VERSION ""

NS_ :

BS_:

BU_: BMS ECC EVBUS_Virtual_ECU GW OBC VCU

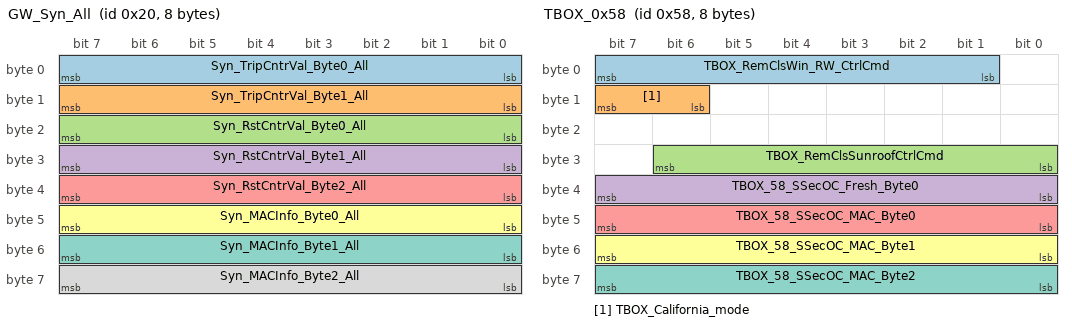
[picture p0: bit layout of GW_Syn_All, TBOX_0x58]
BO_ 32 GW_Syn_All: 8 GW
 SG_ Syn_TripCntrVal_Byte0_All : 7|8@0+ (1,0) [0|255] ""  BMS,OBC,VCU
 SG_ Syn_TripCntrVal_Byte1_All : 15|8@0+ (1,0) [0|255] ""  BMS,OBC,VCU
 SG_ Syn_RstCntrVal_Byte0_All : 23|8@0+ (1,0) [0|255] ""  BMS,OBC,VCU
 SG_ Syn_RstCntrVal_Byte1_All : 31|8@0+ (1,0) [0|255] ""  BMS,OBC,VCU
 SG_ Syn_RstCntrVal_Byte2_All : 39|8@0+ (1,0) [0|255] ""  BMS,OBC,VCU
 SG_ Syn_MACInfo_Byte0_All : 47|8@0+ (1,0) [0|255] ""  BMS,OBC,VCU
 SG_ Syn_MACInfo_Byte1_All : 55|8@0+ (1,0) [0|255] ""  BMS,OBC,VCU
 SG_ Syn_MACInfo_Byte2_All : 63|8@0+ (1,0) [0|255] ""  BMS,OBC,VCU

BO_ 54 TBOX_0x36: 8 GW
 SG_ TBOX_RemSeekCarCtrlCmd : 3|2@0+ (1,0) [0|3] ""  EVBUS_Virtual_ECU
 SG_ TBOX_RemClsTrCmd : 9|2@0+ (1,0) [0|3] ""  EVBUS_Virtual_ECU
 SG_ TBOX_RemDrvrSeatVentnCmd : 12|3@0+ (1,0) [0|7] ""  EVBUS_Virtual_ECU
 SG_ TBOX_RemDrvrSeatHeatgCmd : 15|3@0+ (1,0) [0|7] ""  EVBUS_Virtual_ECU
 SG_ TBOX_RemSetWelFct : 17|2@0+ (1,0) [0|3] ""  EVBUS_Virtual_ECU
 SG_ TBOX_RemPassSeatVentnCmd : 20|3@0+ (1,0) [0|7] ""  EVBUS_Virtual_ECU
 SG_ TBOX_RemPassSeatHeatgCmd : 23|3@0+ (1,0) [0|7] ""  EVBUS_Virtual_ECU
 SG_ TBOX_ClsAVMFct_ICC : 27|1@0+ (1,0) [0|1] ""  EVBUS_Virtual_ECU
 SG_ TBOX_ClsRemAVMFct_AVAP : 28|1@0+ (1,0) [0|1] ""  EVBUS_Virtual_ECU
 SG_ TBOX_RemSetFolwMeFct_BCM : 31|3@0+ (1,0) [0|7] ""  EVBUS_Virtual_ECU
 SG_ TBOX_RemSetCtrlLockFct_PKC : 33|2@0+ (1,0) [0|3] ""  EVBUS_Virtual_ECU
 SG_ TBOX_RemSetKickSnsrFct : 35|2@0+ (1,0) [0|3] ""  EVBUS_Virtual_ECU
 SG_ TBOX_VideoCtrlReq : 38|3@0+ (1,0) [0|7] ""  EVBUS_Virtual_ECU
 SG_ TBOX_VoiceBlowerLimReq : 39|1@0+ (1,0) [0|1] ""  ECC
 SG_ TBOX_RemCtrlCmdFb : 41|2@0+ (1,0) [0|3] ""  EVBUS_Virtual_ECU
 SG_ TBOX_CtrlReMirrReq : 43|2@0+ (1,0) [0|3] ""  EVBUS_Virtual_ECU
 SG_ TBOX_eCallMuteSt : 45|2@0+ (1,0) [0|3] ""  EVBUS_Virtual_ECU
 SG_ TBOX_RemReScrnHeatgCmd : 47|2@0+ (1,0) [0|3] ""  EVBUS_Virtual_ECU
 SG_ TBOX_eCallSt : 58|3@0+ (1,0) [0|7] ""  EVBUS_Virtual_ECU

BO_ 88 TBOX_0x58: 8 GW
 SG_ TBOX_RemClsWin_RW_CtrlCmd : 7|7@0+ (1,0) [0|100] "%"  EVBUS_Virtual_ECU
 SG_ TBOX_California_mode : 15|2@0+ (1,0) [0|3] ""  ECC
 SG_ TBOX_RemClsSunroofCtrlCmd : 30|7@0+ (1,0) [0|100] "%"  EVBUS_Virtual_ECU
 SG_ TBOX_58_SSecOC_Fresh_Byte0 : 39|8@0+ (1,0) [0|255] ""  EVBUS_Virtual_ECU
 SG_ TBOX_58_SSecOC_MAC_Byte0 : 47|8@0+ (1,0) [0|255] ""  EVBUS_Virtual_ECU
 SG_ TBOX_58_SSecOC_MAC_Byte1 : 55|8@0+ (1,0) [0|255] ""  EVBUS_Virtual_ECU
 SG_ TBOX_58_SSecOC_MAC_Byte2 : 63|8@0+ (1,0) [0|255] ""  EVBUS_Virtual_ECU

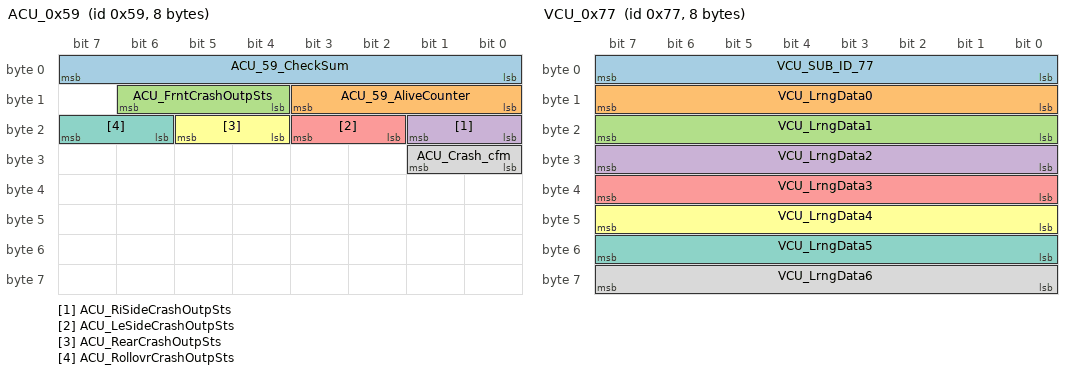
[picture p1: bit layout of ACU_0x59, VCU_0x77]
BO_ 89 ACU_0x59: 8 GW
 SG_ ACU_59_CheckSum : 7|8@0+ (1,0) [0|255] ""  BMS,ECC,OBC
 SG_ ACU_59_AliveCounter : 11|4@0+ (1,0) [0|14] ""  BMS,ECC,OBC
 SG_ ACU_FrntCrashOutpSts : 14|3@0+ (1,0) [0|7] ""  BMS,ECC,OBC
 SG_ ACU_RiSideCrashOutpSts : 17|2@0+ (1,0) [0|3] ""  BMS,ECC,OBC
 SG_ ACU_LeSideCrashOutpSts : 19|2@0+ (1,0) [0|3] ""  BMS,ECC,OBC
 SG_ ACU_RearCrashOutpSts : 21|2@0+ (1,0) [0|3] ""  BMS,ECC,OBC
 SG_ ACU_RollovrCrashOutpSts : 23|2@0+ (1,0) [0|3] ""  BMS,ECC,OBC
 SG_ ACU_Crash_cfm : 25|2@0+ (1,0) [0|3] ""  BMS,ECC,OBC

BO_ 117 VCU_0x75: 8 VCU
 SG_ VCU_SUB_ID_75 : 7|8@0+ (1,0) [0|255] ""  GW
 SG_ VCU_LrngSts : 15|8@0+ (1,0) [0|255] ""  GW

BO_ 119 VCU_0x77: 8 VCU
 SG_ VCU_SUB_ID_77 : 7|8@0+ (1,0) [0|255] ""  GW
 SG_ VCU_LrngData0 : 15|8@0+ (1,0) [0|255] ""  GW
 SG_ VCU_LrngData1 : 23|8@0+ (1,0) [0|255] ""  GW
 SG_ VCU_LrngData2 : 31|8@0+ (1,0) [0|255] ""  GW
 SG_ VCU_LrngData3 : 39|8@0+ (1,0) [0|255] ""  GW
 SG_ VCU_LrngData4 : 47|8@0+ (1,0) [0|255] ""  GW
 SG_ VCU_LrngData5 : 55|8@0+ (1,0) [0|255] ""  GW
 SG_ VCU_LrngData6 : 63|8@0+ (1,0) [0|255] ""  GW

BO_ 121 TBOX_0x79: 8 GW
 SG_ TBOX_LrnFbInfoClassn : 7|8@0+ (1,0) [0|255] ""  EVBUS_Virtual_ECU
 SG_ TBOX_LrngSts : 15|8@0+ (1,0) [0|255] ""  EVBUS_Virtual_ECU

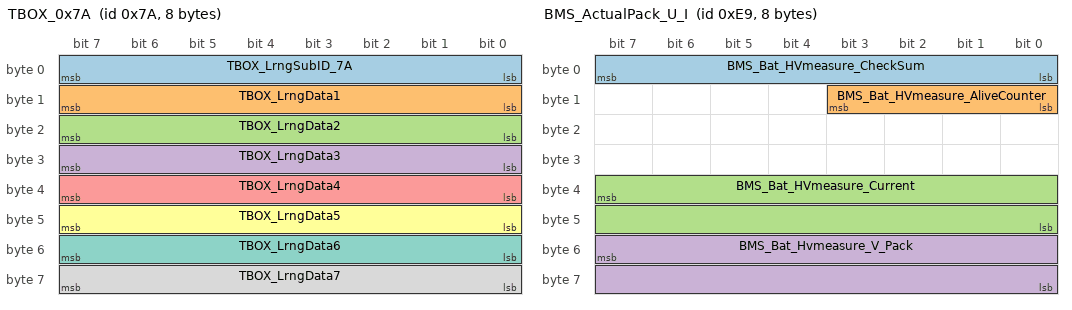
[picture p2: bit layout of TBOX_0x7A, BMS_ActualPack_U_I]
BO_ 122 TBOX_0x7A: 8 GW
 SG_ TBOX_LrngSubID_7A : 7|8@0+ (1,0) [0|255] ""  EVBUS_Virtual_ECU
 SG_ TBOX_LrngData1 : 15|8@0+ (1,0) [0|255] ""  EVBUS_Virtual_ECU
 SG_ TBOX_LrngData2 : 23|8@0+ (1,0) [0|255] ""  EVBUS_Virtual_ECU
 SG_ TBOX_LrngData3 : 31|8@0+ (1,0) [0|255] ""  EVBUS_Virtual_ECU
 SG_ TBOX_LrngData4 : 39|8@0+ (1,0) [0|255] ""  EVBUS_Virtual_ECU
 SG_ TBOX_LrngData5 : 47|8@0+ (1,0) [0|255] ""  EVBUS_Virtual_ECU
 SG_ TBOX_LrngData6 : 55|8@0+ (1,0) [0|255] ""  EVBUS_Virtual_ECU
 SG_ TBOX_LrngData7 : 63|8@0+ (1,0) [0|255] ""  EVBUS_Virtual_ECU

BO_ 147 VCU_0x93: 16 VCU
 SG_ VCU_93_CheckSum : 7|8@0+ (1,0) [0|255] ""  BMS,GW
 SG_ VCU_93_AliveCounter : 11|4@0+ (1,0) [0|14] ""  BMS,GW
 SG_ VCU_EmgyShutOff : 12|1@0+ (1,0) [0|1] ""  BMS,GW
 SG_ VCU_IsolationMonitor_Rq : 13|1@0+ (1,0) [0|1] ""  BMS,GW
 SG_ VCU_Set_Chrg_Mod : 19|4@0+ (1,0) [0|15] ""  BMS,GW
 SG_ VCU_Set_BMS_Mod : 23|4@0+ (1,0) [0|15] ""  BMS,GW
 SG_ VCU_HVBActivateDeactivateRq : 35|4@0+ (1,0) [0|15] ""  BMS,GW
 SG_ VCU_Set_Balc_Mod : 39|4@0+ (1,0) [0|15] ""  BMS,GW
 SG_ VCU_93_SSecOC_Fresh_Byte0 : 71|8@0+ (1,0) [0|255] ""  BMS,GW
 SG_ VCU_93_SSecOC_MAC_Byte0 : 79|8@0+ (1,0) [0|255] ""  BMS,GW
 SG_ VCU_93_SSecOC_MAC_Byte1 : 87|8@0+ (1,0) [0|255] ""  BMS,GW
 SG_ VCU_93_SSecOC_MAC_Byte2 : 95|8@0+ (1,0) [0|255] ""  BMS,GW

BO_ 233 BMS_ActualPack_U_I: 8 BMS
 SG_ BMS_Bat_HVmeasure_CheckSum : 7|8@0+ (1,0) [0|255] ""  GW,VCU
 SG_ BMS_Bat_HVmeasure_AliveCounter : 11|4@0+ (1,0) [0|14] ""  GW,VCU
 SG_ BMS_Bat_HVmeasure_Current : 39|16@0- (0.05,0) [-1250|1250] "A"  ECC,GW,VCU
 SG_ BMS_Bat_Hvmeasure_V_Pack : 55|16@0+ (0.01,0) [0|655.35] "V"  GW,VCU

BO_ 235 BMS_HVBatt_Status_Errors_1: 8 BMS
 SG_ BMS_Critical_Error_Flg_CheckSum : 7|8@0+ (1,0) [0|255] ""  GW,VCU
 SG_ BMS_Critical_Error_Flg_AliveCoun : 11|4@0+ (1,0) [0|14] ""  GW,VCU
 SG_ BMS_ErrorWarning_OverChargeCurre : 12|1@0+ (1,0) [0|1] ""  GW,VCU
 SG_ BMS_ErrorActive_OverChargeCurren : 13|1@0+ (1,0) [0|1] ""  GW,VCU
 SG_ BMS_ErrorWarning_OverDischargeCu : 14|1@0+ (1,0) [0|1] ""  GW,VCU
 SG_ BMS_ErrorActive_OverDischargeCur : 15|1@0+ (1,0) [0|1] ""  GW,VCU
 SG_ BMS_ErrorWarning_ChargePowerLimi : 16|1@0+ (1,0) [0|1] ""  GW,VCU
 SG_ BMS_ErrorActive_ChargePowerLimit : 17|1@0+ (1,0) [0|1] ""  GW,VCU
 SG_ BMS_ErrorWarning_DischargePowerL : 18|1@0+ (1,0) [0|1] ""  GW,VCU
 SG_ BMS_ErrorActive_DischargePowerLi : 19|1@0+ (1,0) [0|1] ""  GW,VCU
 SG_ BMS_ErrorWarning_SOC_Low : 20|1@0+ (1,0) [0|1] ""  GW,VCU
 SG_ BMS_ErrorActive_SOC_Low : 21|1@0+ (1,0) [0|1] ""  GW,VCU
 SG_ BMS_ErrorWarning_Iso : 22|1@0+ (1,0) [0|1] ""  GW,VCU
 SG_ BMS_ErrorActive_Iso_Crit : 23|1@0+ (1,0) [0|1] ""  GW,VCU
 SG_ BMS_ErrorActive_AbsChargeCurrent : 24|1@0+ (1,0) [0|1] ""  GW,VCU
 SG_ BMS_ErrorActive_AbsDischargeCurr : 25|1@0+ (1,0) [0|1] ""  GW,VCU
 SG_ BMS_ErrorActive_AbsChargePowerLi : 26|1@0+ (1,0) [0|1] ""  GW,VCU
 SG_ BMS_ErrorActive_AbsDischargePowe : 27|1@0+ (1,0) [0|1] ""  GW,VCU
 SG_ BMS_ErrorWarning_overcurrent_Pre : 28|1@0+ (1,0) [0|1] ""  GW,VCU
 SG_ BMS_ErrorActive_ServState : 29|1@0+ (1,0) [0|1] ""  GW,VCU
 SG_ BMS_SystemError_KL30C : 30|1@0+ (1,0) [0|1] ""  GW,VCU
 SG_ BMS_SystemError_OmmissionOfKL15 : 31|1@0+ (1,0) [0|1] ""  GW,VCU
 SG_ BMS_SystemError_HV_Interlock : 32|1@0+ (1,0) [0|1] ""  GW,VCU
 SG_ BMS_SystemError_HV_Fuse : 33|1@0+ (1,0) [0|1] ""  GW,VCU
 SG_ BMS_CommError_CommFailure : 34|1@0+ (1,0) [0|1] ""  GW,VCU
 SG_ BMS_CommWarning_PEC_High : 35|1@0+ (1,0) [0|1] ""  GW,VCU
 SG_ BMS_CommError_PEC_High : 36|1@0+ (1,0) [0|1] ""  GW,VCU
 SG_ BMS_HVlinkError_VCU_Comm_Failure : 37|1@0+ (1,0) [0|1] ""  GW,VCU
 SG_ BMS_HVlinkError_Iso_Dev : 38|1@0+ (1,0) [0|1] ""  GW,VCU
 SG_ BMS_HVlinkError_Iso_Dig_Sig : 39|1@0+ (1,0) [0|1] ""  GW,VCU
 SG_ BMS_HVlinkError_ContactorWelded : 40|1@0+ (1,0) [0|1] ""  GW,VCU
 SG_ BMS_HVlinkError_HV_Interlock_Bad : 41|1@0+ (1,0) [0|1] ""  GW,VCU
 SG_ BMS_HardwareError_LCM_General_Fa : 42|1@0+ (1,0) [0|1] ""  GW,VCU
 SG_ BMS_SoftwareError_General_Failr : 43|1@0+ (1,0) [0|1] ""  GW,VCU
 SG_ BMS_ErrorWarning_CellOverVoltage : 44|1@0+ (1,0) [0|1] ""  GW,VCU
 SG_ BMS_ErrorActive_CellOverVoltage : 45|1@0+ (1,0) [0|1] ""  GW,VCU
 SG_ BMS_ErrorWarning_CellUnderVoltag : 46|1@0+ (1,0) [0|1] ""  GW,VCU
 SG_ BMS_ErrorActive_CellUnderVoltage : 47|1@0+ (1,0) [0|1] ""  GW,VCU
 SG_ BMS_ErrorWarning_CellTempHigh : 48|1@0+ (1,0) [0|1] ""  GW,VCU
 SG_ BMS_ErrorActive_CellTempHigh : 49|1@0+ (1,0) [0|1] ""  GW,VCU
 SG_ BMS_ErrorWarning_CellTempLow : 50|1@0+ (1,0) [0|1] ""  GW,VCU
 SG_ BMS_ErrorActive_CellTempLow : 51|1@0+ (1,0) [0|1] ""  GW,VCU
 SG_ BMS_ErrorWarning_HV_OverVoltage : 52|1@0+ (1,0) [0|1] ""  GW,VCU
 SG_ BMS_ErrorActive_HV_OverVoltage : 53|1@0+ (1,0) [0|1] ""  GW,VCU
 SG_ BMS_ErrorWarning_HV_UnderVoltage : 54|1@0+ (1,0) [0|1] ""  GW,VCU
 SG_ BMS_ErrorActive_HV_UnderVoltage : 55|1@0+ (1,0) [0|1] ""  GW,VCU
 SG_ BMS_PVIU_CANcommError : 56|1@0+ (1,0) [0|1] ""  GW,VCU

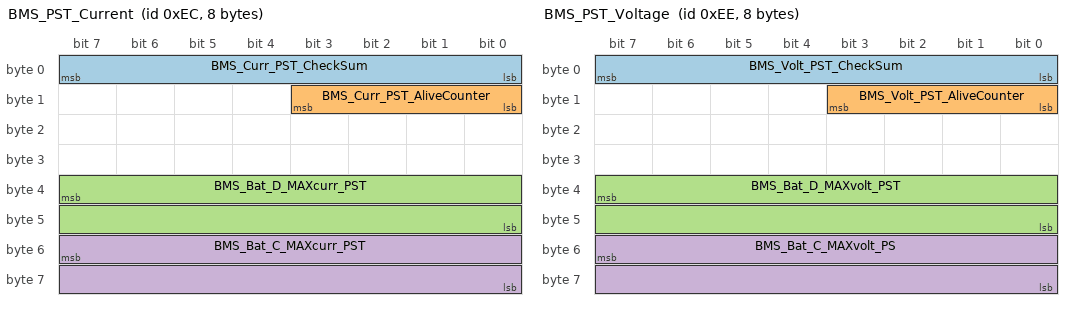
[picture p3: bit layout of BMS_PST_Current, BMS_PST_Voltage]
BO_ 236 BMS_PST_Current: 8 BMS
 SG_ BMS_Curr_PST_CheckSum : 7|8@0+ (1,0) [0|255] ""  GW,VCU
 SG_ BMS_Curr_PST_AliveCounter : 11|4@0+ (1,0) [0|14] ""  GW,VCU
 SG_ BMS_Bat_D_MAXcurr_PST : 39|16@0+ (0.05,0) [0|3276.75] "A"  GW,VCU
 SG_ BMS_Bat_C_MAXcurr_PST : 55|16@0+ (0.05,0) [0|3276.75] "A"  GW,VCU

BO_ 237 BMS_HVBatt_Status_Overall: 8 BMS
 SG_ BMS_OverallStatus_CheckSum : 7|8@0+ (1,0) [0|255] ""  ECC,GW,VCU
 SG_ BMS_OverallStatus_AliveCounter : 11|4@0+ (1,0) [0|14] ""  ECC,GW,VCU
 SG_ BMS_OperationStates : 19|4@0+ (1,0) [0|15] ""  ECC,GW,VCU
 SG_ BMS_BallancingStatus : 23|4@0+ (1,0) [0|15] ""  ECC,GW,VCU
 SG_ BMS_ErrorCategory_CAT0 : 24|1@0+ (1,0) [0|1] ""  ECC,GW,VCU
 SG_ BMS_ErrorCategory_CAT1 : 25|1@0+ (1,0) [0|1] ""  ECC,GW,VCU
 SG_ BMS_ErrorCategory_CAT2 : 26|1@0+ (1,0) [0|1] ""  ECC,GW,VCU
 SG_ BMS_ErrorCategory_CAT3 : 27|1@0+ (1,0) [0|1] ""  ECC,GW,VCU
 SG_ BMS_ErrorCategory_CAT4 : 28|1@0+ (1,0) [0|1] ""  ECC,GW,VCU
 SG_ BMS_ErrorCategory_CAT5 : 29|1@0+ (1,0) [0|1] ""  ECC,GW,VCU
 SG_ BMS_ErrorCategory_CAT6 : 30|1@0+ (1,0) [0|1] ""  ECC,GW,VCU
 SG_ BMS_ErrorCategory_CAT7 : 31|1@0+ (1,0) [0|1] ""  ECC,GW,VCU
 SG_ BMS_ErrorCategory_CAT8 : 32|1@0+ (1,0) [0|1] ""  ECC,GW,VCU
 SG_ BMS_HardwareStatus_OK : 33|1@0+ (1,0) [0|1] ""  ECC,GW,VCU
 SG_ BMS_ErrorCategory_Mem_Empty : 34|1@0+ (1,0) [0|1] ""  ECC,GW,VCU
 SG_ BMS_ConfigurationStatus_OK : 35|1@0+ (1,0) [0|1] ""  ECC,GW,VCU
 SG_ BMS_MeasurementModules_OK : 36|1@0+ (1,0) [0|1] ""  ECC,GW,VCU
 SG_ BMS_BatteryGeneralStatus_OK : 37|1@0+ (1,0) [0|1] ""  ECC,GW,VCU
 SG_ BMS_SDIL_Sts : 38|1@0+ (1,0) [0|1] ""  ECC,GW,VCU
 SG_ BMS_CL30C_Sts : 39|1@0+ (1,0) [0|1] ""  ECC,GW,VCU
 SG_ BMS_CL15_Sts : 40|1@0+ (1,0) [0|1] ""  ECC,GW,VCU
 SG_ BMS_HVIL_OK : 41|1@0+ (1,0) [0|1] ""  ECC,GW,VCU
 SG_ BMS_HV_ContactorsStatus_OK : 42|1@0+ (1,0) [0|1] ""  ECC,GW,VCU
 SG_ BMS_SW_Status_OK : 43|1@0+ (1,0) [0|1] ""  ECC,GW,VCU
 SG_ BMS_CurrentSensor_OK : 44|1@0+ (1,0) [0|1] ""  ECC,GW,VCU
 SG_ BMS_IsolatoinStatus_OK : 45|1@0+ (1,0) [0|1] ""  ECC,GW,VCU
 SG_ BMS_StateMAchine_Status : 55|8@0+ (1,0) [0|255] ""  ECC,GW,OBC,VCU
 SG_ BMS_BDU_Status : 63|8@0+ (1,0) [0|255] ""  ECC,GW,VCU

BO_ 238 BMS_PST_Voltage: 8 BMS
 SG_ BMS_Volt_PST_CheckSum : 7|8@0+ (1,0) [0|255] ""  GW,VCU
 SG_ BMS_Volt_PST_AliveCounter : 11|4@0+ (1,0) [0|14] ""  GW,VCU
 SG_ BMS_Bat_D_MAXvolt_PST : 39|16@0+ (0.02,0) [0|1310.7] "V"  GW,VCU
 SG_ BMS_Bat_C_MAXvolt_PS : 55|16@0+ (0.02,0) [0|1310.7] "V"  GW,VCU

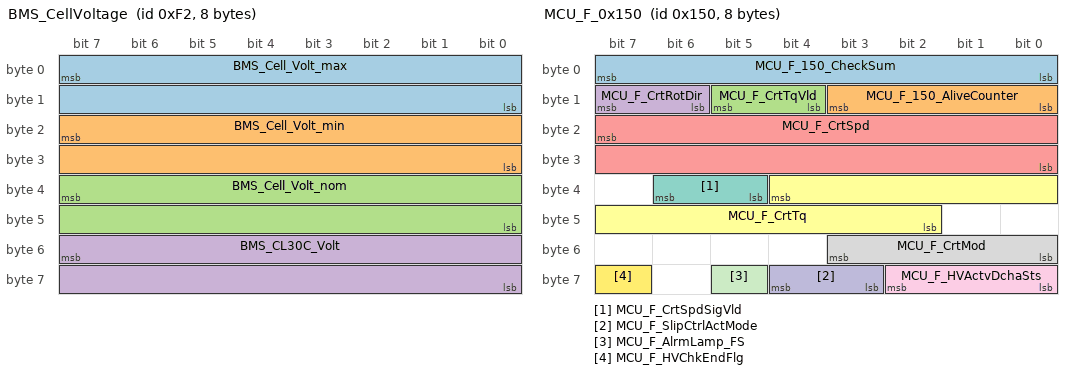
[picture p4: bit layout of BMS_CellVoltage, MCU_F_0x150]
BO_ 242 BMS_CellVoltage: 8 BMS
 SG_ BMS_Cell_Volt_max : 7|16@0+ (0.1,0) [0|6553.5] "mV"  GW,VCU
 SG_ BMS_Cell_Volt_min : 23|16@0+ (0.1,0) [0|6553.5] "mV"  GW,VCU
 SG_ BMS_Cell_Volt_nom : 39|16@0+ (0.1,0) [0|6553.5] "mV"  GW,VCU
 SG_ BMS_CL30C_Volt : 55|16@0+ (0.001,0) [0|65.534] "V"  GW

BO_ 276 ESP_0x114: 8 GW
 SG_ ESP_114_CheckSum : 7|8@0+ (1,0) [0|255] ""  EVBUS_Virtual_ECU
 SG_ ESP_114_AliveCounter : 11|4@0+ (1,0) [0|14] ""  EVBUS_Virtual_ECU
 SG_ ESP_OTARdy_Fb : 13|2@0+ (1,0) [0|3] ""  EVBUS_Virtual_ECU
 SG_ ESP_FltIndcn_DTC : 15|1@0+ (1,0) [0|1] ""  EVBUS_Virtual_ECU
 SG_ ESP_ActvSig_VDC : 16|1@0+ (1,0) [0|1] ""  EVBUS_Virtual_ECU
 SG_ ESP_ActvSig_TCS : 17|1@0+ (1,0) [0|1] ""  EVBUS_Virtual_ECU
 SG_ ESP_ActvSig_EBD : 19|1@0+ (1,0) [0|1] ""  EVBUS_Virtual_ECU
 SG_ ESP_ActvSig_DTC : 20|1@0+ (1,0) [0|1] ""  EVBUS_Virtual_ECU
 SG_ ESP_WarningOn : 22|2@0+ (1,0) [0|3] ""  EVBUS_Virtual_ECU
 SG_ ESP_Actvndcn_CDD : 24|1@0+ (1,0) [0|1] ""  EVBUS_Virtual_ECU
 SG_ ESP_FltIndcn_CDD : 25|1@0+ (1,0) [0|1] ""  EVBUS_Virtual_ECU
 SG_ ESP_ActvIndcn_ABA : 26|1@0+ (1,0) [0|1] ""  EVBUS_Virtual_ECU
 SG_ ESP_FltIndcn_ABA : 27|1@0+ (1,0) [0|1] ""  EVBUS_Virtual_ECU
 SG_ ESP_ActvIndcn_ABP : 28|1@0+ (1,0) [0|1] ""  EVBUS_Virtual_ECU
 SG_ ESP_FltIndcn_ABP : 29|1@0+ (1,0) [0|1] ""  EVBUS_Virtual_ECU
 SG_ ESP_ActvIndcn_AEB : 30|1@0+ (1,0) [0|1] ""  EVBUS_Virtual_ECU
 SG_ ESP_FltIndcn_AEB : 31|1@0+ (1,0) [0|1] ""  EVBUS_Virtual_ECU
 SG_ ESP_ActvIndcn_AWB : 32|1@0+ (1,0) [0|1] ""  EVBUS_Virtual_ECU
 SG_ ESP_FltIndcn_AWB : 33|1@0+ (1,0) [0|1] ""  EVBUS_Virtual_ECU
 SG_ ESP_VehStandstillIndcn : 35|2@0+ (1,0) [0|3] ""  EVBUS_Virtual_ECU
 SG_ ESP_BrkOverTIndcn : 36|1@0+ (1,0) [0|1] ""  ECC
 SG_ ESP_FltIndcn_VDC : 37|1@0+ (1,0) [0|1] ""  EVBUS_Virtual_ECU
 SG_ ESP_ActvIndcn_CDD_AP : 42|1@0+ (1,0) [0|1] ""  EVBUS_Virtual_ECU
 SG_ ESP_FltIndcn_CDD_AP : 43|1@0+ (1,0) [0|1] ""  EVBUS_Virtual_ECU

BO_ 336 MCU_F_0x150: 8 GW
 SG_ MCU_F_150_CheckSum : 7|8@0+ (1,0) [0|255] ""  ECC
 SG_ MCU_F_150_AliveCounter : 11|4@0+ (1,0) [0|14] ""  ECC
 SG_ MCU_F_CrtTqVld : 13|2@0+ (1,0) [0|3] ""  ECC
 SG_ MCU_F_CrtRotDir : 15|2@0+ (1,0) [0|3] ""  ECC
 SG_ MCU_F_CrtSpd : 23|16@0+ (1,-32768) [-32768|32767] "rpm"  BMS,ECC,OBC
 SG_ MCU_F_CrtTq : 36|11@0+ (0.5,-511) [-511|512] "Nm"  ECC
 SG_ MCU_F_CrtSpdSigVld : 38|2@0+ (1,0) [0|3] ""  BMS,ECC,OBC
 SG_ MCU_F_CrtMod : 51|4@0+ (1,0) [0|15] ""  ECC
 SG_ MCU_F_HVActvDchaSts : 58|3@0+ (1,0) [0|7] ""  ECC
 SG_ MCU_F_SlipCtrlActMode : 60|2@0+ (1,0) [0|3] ""  ECC
 SG_ MCU_F_AlrmLamp_FS : 61|1@0+ (1,0) [0|1] ""  ECC
 SG_ MCU_F_HVChkEndFlg : 63|1@0+ (1,0) [0|1] ""  ECC

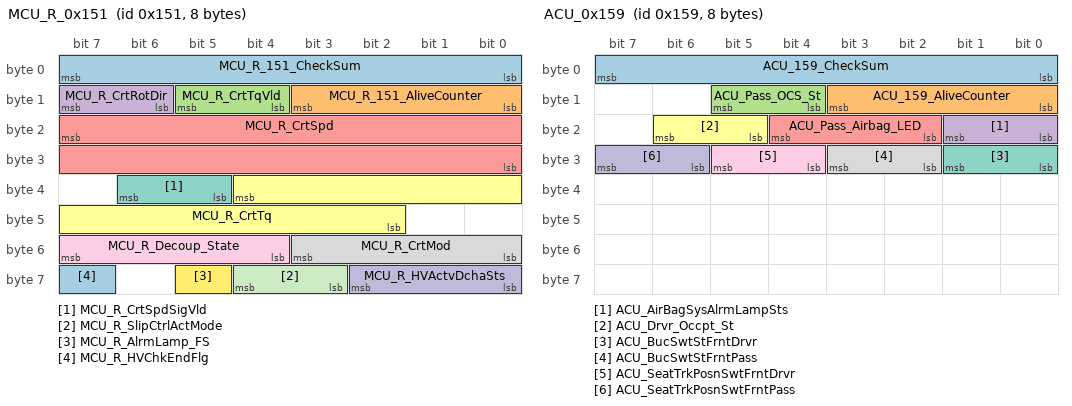
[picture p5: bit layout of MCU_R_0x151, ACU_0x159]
BO_ 337 MCU_R_0x151: 8 GW
 SG_ MCU_R_151_CheckSum : 7|8@0+ (1,0) [0|255] ""  ECC
 SG_ MCU_R_151_AliveCounter : 11|4@0+ (1,0) [0|14] ""  ECC
 SG_ MCU_R_CrtTqVld : 13|2@0+ (1,0) [0|3] ""  ECC
 SG_ MCU_R_CrtRotDir : 15|2@0+ (1,0) [0|3] ""  ECC
 SG_ MCU_R_CrtSpd : 23|16@0+ (1,-32768) [-32768|32767] "rpm"  BMS,ECC,OBC
 SG_ MCU_R_CrtTq : 36|11@0+ (0.5,-511) [-511|512] "Nm"  ECC
 SG_ MCU_R_CrtSpdSigVld : 38|2@0+ (1,0) [0|3] ""  BMS,ECC,OBC
 SG_ MCU_R_CrtMod : 51|4@0+ (1,0) [0|15] ""  ECC
 SG_ MCU_R_Decoup_State : 55|4@0+ (1,0) [0|15] ""  ECC
 SG_ MCU_R_HVActvDchaSts : 58|3@0+ (1,0) [0|7] ""  ECC
 SG_ MCU_R_SlipCtrlActMode : 60|2@0+ (1,0) [0|3] ""  ECC
 SG_ MCU_R_AlrmLamp_FS : 61|1@0+ (1,0) [0|1] ""  ECC
 SG_ MCU_R_HVChkEndFlg : 63|1@0+ (1,0) [0|1] ""  ECC

BO_ 345 ACU_0x159: 8 GW
 SG_ ACU_159_CheckSum : 7|8@0+ (1,0) [0|255] ""  ECC
 SG_ ACU_159_AliveCounter : 11|4@0+ (1,0) [0|14] ""  ECC
 SG_ ACU_Pass_OCS_St : 13|2@0+ (1,0) [0|3] ""  ECC
 SG_ ACU_AirBagSysAlrmLampSts : 17|2@0+ (1,0) [0|3] ""  EVBUS_Virtual_ECU
 SG_ ACU_Pass_Airbag_LED : 20|3@0+ (1,0) [0|7] ""  EVBUS_Virtual_ECU
 SG_ ACU_Drvr_Occpt_St : 22|2@0+ (1,0) [0|3] ""  ECC
 SG_ ACU_BucSwtStFrntDrvr : 25|2@0+ (1,0) [0|3] ""  ECC
 SG_ ACU_BucSwtStFrntPass : 27|2@0+ (1,0) [0|3] ""  ECC
 SG_ ACU_SeatTrkPosnSwtFrntDrvr : 29|2@0+ (1,0) [0|3] ""  EVBUS_Virtual_ECU
 SG_ ACU_SeatTrkPosnSwtFrntPass : 31|2@0+ (1,0) [0|3] ""  EVBUS_Virtual_ECU

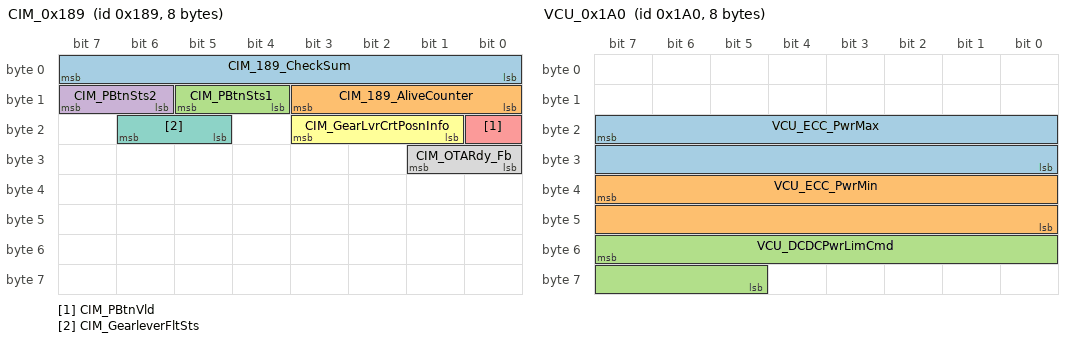
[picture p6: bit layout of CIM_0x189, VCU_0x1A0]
BO_ 393 CIM_0x189: 8 GW
 SG_ CIM_189_CheckSum : 7|8@0+ (1,0) [0|255] ""  VCU
 SG_ CIM_189_AliveCounter : 11|4@0+ (1,0) [0|14] ""  VCU
 SG_ CIM_PBtnSts1 : 13|2@0+ (1,0) [0|3] ""  VCU
 SG_ CIM_PBtnSts2 : 15|2@0+ (1,0) [0|3] ""  VCU
 SG_ CIM_PBtnVld : 16|1@0+ (1,0) [0|1] ""  VCU
 SG_ CIM_GearLvrCrtPosnInfo : 19|3@0+ (1,0) [0|7] ""  VCU
 SG_ CIM_GearleverFltSts : 22|2@0+ (1,0) [0|3] ""  VCU
 SG_ CIM_OTARdy_Fb : 25|2@0+ (1,0) [0|3] ""  EVBUS_Virtual_ECU

BO_ 416 VCU_0x1A0: 8 VCU
 SG_ VCU_ECC_PwrMax : 23|16@0+ (0.01,0) [0|20] "KW"  ECC,GW
 SG_ VCU_ECC_PwrMin : 39|16@0+ (0.01,0) [0|20] "KW"  ECC,GW
 SG_ VCU_DCDCPwrLimCmd : 55|11@0+ (0.01,0) [0|20] "KW"  GW,OBC

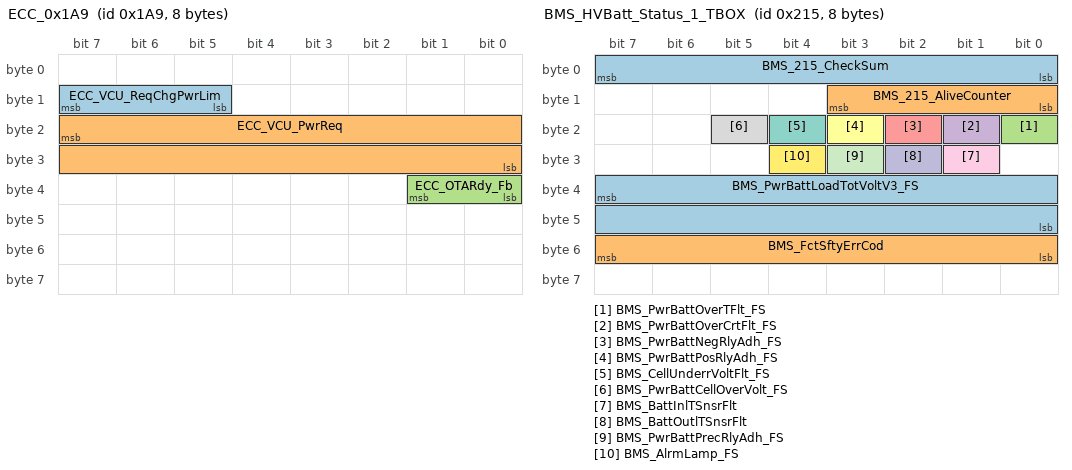
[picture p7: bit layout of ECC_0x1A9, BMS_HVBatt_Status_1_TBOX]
BO_ 425 ECC_0x1A9: 8 ECC
 SG_ ECC_VCU_ReqChgPwrLim : 15|3@0+ (1,0) [0|7] ""  GW,VCU
 SG_ ECC_VCU_PwrReq : 23|16@0+ (0.01,0) [0|20] "KW"  GW,VCU
 SG_ ECC_OTARdy_Fb : 33|2@0+ (1,0) [0|3] ""  GW

BO_ 438 PKC_0x1B6: 8 GW
 SG_ PKC_1B6_CheckSum : 7|8@0+ (1,0) [0|255] ""  VCU
 SG_ PKC_1B6_AliveCounter : 11|4@0+ (1,0) [0|14] ""  VCU
 SG_ PKC_TpMnvrCancel : 13|2@0+ (1,0) [0|3] ""  EVBUS_Virtual_ECU
 SG_ PKC_TpActDeactInp : 15|2@0+ (1,0) [0|3] ""  EVBUS_Virtual_ECU
 SG_ PKC_RemPwrOnOffReq : 17|2@0+ (1,0) [0|3] ""  VCU
 SG_ PKC_RemDrvgReq : 21|4@0+ (1,0) [0|15] ""  VCU
 SG_ PKC_RemChrgDchaGunUnlckCmd : 23|2@0+ (1,0) [0|3] ""  VCU
 SG_ PKC_RmteDviceBattLvl : 31|8@0+ (1,0) [0|100] "%"  EVBUS_Virtual_ECU
 SG_ PKC_BLE_Online : 32|1@0+ (1,0) [0|1] ""  EVBUS_Virtual_ECU
 SG_ PKC_DviceRngeDist : 34|2@0+ (1,0) [0|3] ""  EVBUS_Virtual_ECU
 SG_ PKC_DviceAliveCnt : 39|4@0+ (1,0) [0|15] ""  EVBUS_Virtual_ECU
 SG_ PKC_MnvreEnblInput : 41|2@0+ (1,0) [0|3] ""  EVBUS_Virtual_ECU
 SG_ PKC_RapActDeactInp : 47|2@0+ (1,0) [0|3] ""  EVBUS_Virtual_ECU
 SG_ PKC_MnvrRemsumeKey : 49|2@0+ (1,0) [0|3] ""  EVBUS_Virtual_ECU
 SG_ PKC_MnvrRtnStartKey : 51|2@0+ (1,0) [0|3] ""  EVBUS_Virtual_ECU
 SG_ PKC_AuthUsr : 59|2@0+ (1,0) [0|3] ""  EVBUS_Virtual_ECU
 SG_ PKC_AlcInterlockReqPromt : 61|2@0+ (1,0) [0|3] ""  EVBUS_Virtual_ECU
 SG_ PKC_NFCReminderPromt : 63|2@0+ (1,0) [0|3] ""  EVBUS_Virtual_ECU

BO_ 532 VCU_0x214: 16 VCU
 SG_ VCU_214_234_CheckSum : 7|8@0+ (1,0) [0|255] ""  ECC,GW
 SG_ VCU_214_234_AliveCounter : 11|4@0+ (1,0) [0|14] ""  ECC,GW
 SG_ VCU_RdyLamp : 12|1@0+ (1,0) [0|1] ""  GW
 SG_ VCU_BrkLampCtrlSts : 14|1@0+ (1,0) [0|1] ""  GW
 SG_ VCU_RemWakeUpEndFlg : 15|1@0+ (1,0) [0|1] ""  GW
 SG_ VCU_StgyGearSig : 19|4@0+ (1,0) [0|15] ""  GW
 SG_ VCU_ShiftMisoper : 21|1@0+ (1,0) [0|1] ""  GW
 SG_ VCU_GearSigVld : 23|2@0+ (1,0) [0|3] ""  GW
 SG_ VCU_GearSig : 27|4@0+ (1,0) [0|15] ""  GW
 SG_ VCU_ACCRdy : 28|1@0+ (1,0) [0|1] ""  GW
 SG_ VCU_ParkRdy : 29|1@0+ (1,0) [0|1] ""  GW
 SG_ VCU_APSPercVld : 31|2@0+ (1,0) [0|3] ""  GW
 SG_ VCU_VehSt : 39|16@0+ (1,0) [0|65535] ""  ECC,GW
 SG_ VCU_APSPerc : 55|8@0+ (0.4,0) [0|100] "%"  GW
 SG_ VCU_BrkSig : 56|1@0+ (1,0) [0|1] ""  GW
 SG_ VCU_BrkSigVld : 58|2@0+ (1,0) [0|3] ""  GW
 SG_ VCU_DrvModSigFb : 61|3@0+ (1,0) [0|7] ""  GW
 SG_ VCU_DrvModShiftMisoper : 62|1@0+ (1,0) [0|1] ""  GW
 SG_ VCU_SpclTerrainModEnaSig : 63|1@0+ (1,0) [0|1] ""  GW
 SG_ VCU_214_SSecOC_Fresh_Byte0 : 71|8@0+ (1,0) [0|255] ""  GW
 SG_ VCU_214_SSecOC_MAC_Byte0 : 79|8@0+ (1,0) [0|255] ""  GW
 SG_ VCU_214_SSecOC_MAC_Byte1 : 87|8@0+ (1,0) [0|255] ""  GW
 SG_ VCU_214_SSecOC_MAC_Byte2 : 95|8@0+ (1,0) [0|255] ""  GW

BO_ 533 BMS_HVBatt_Status_1_TBOX: 8 BMS
 SG_ BMS_215_CheckSum : 7|8@0+ (1,0) [0|255] ""  GW,VCU
 SG_ BMS_215_AliveCounter : 11|4@0+ (1,0) [0|14] ""  GW,VCU
 SG_ BMS_PwrBattOverTFlt_FS : 16|1@0+ (1,0) [0|1] ""  GW,VCU
 SG_ BMS_PwrBattOverCrtFlt_FS : 17|1@0+ (1,0) [0|1] ""  GW,VCU
 SG_ BMS_PwrBattNegRlyAdh_FS : 18|1@0+ (1,0) [0|1] ""  GW,VCU
 SG_ BMS_PwrBattPosRlyAdh_FS : 19|1@0+ (1,0) [0|1] ""  GW,VCU
 SG_ BMS_CellUnderrVoltFlt_FS : 20|1@0+ (1,0) [0|1] ""  GW,VCU
 SG_ BMS_PwrBattCellOverVolt_FS : 21|1@0+ (1,0) [0|1] ""  GW,VCU
 SG_ BMS_BattInlTSnsrFlt : 25|1@0+ (1,0) [0|1] ""  ECC,GW,VCU
 SG_ BMS_BattOutlTSnsrFlt : 26|1@0+ (1,0) [0|1] ""  ECC,GW,VCU
 SG_ BMS_PwrBattPrecRlyAdh_FS : 27|1@0+ (1,0) [0|1] ""  GW,VCU
 SG_ BMS_AlrmLamp_FS : 28|1@0+ (1,0) [0|1] ""  GW,VCU
 SG_ BMS_PwrBattLoadTotVoltV3_FS : 39|16@0+ (0.02,0) [0|1310.7] "V"  ECC,GW,VCU
 SG_ BMS_FctSftyErrCod : 55|8@0+ (1,0) [0|255] ""  GW

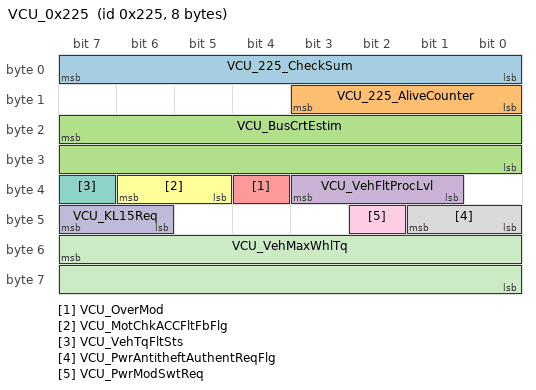
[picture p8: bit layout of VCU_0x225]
BO_ 549 VCU_0x225: 8 VCU
 SG_ VCU_225_CheckSum : 7|8@0+ (1,0) [0|255] ""  GW
 SG_ VCU_225_AliveCounter : 11|4@0+ (1,0) [0|14] ""  GW
 SG_ VCU_BusCrtEstim : 23|16@0+ (0.04,-1000) [-1000|1621.4] "A"  GW
 SG_ VCU_VehFltProcLvl : 35|3@0+ (1,0) [0|7] ""  GW
 SG_ VCU_OverMod : 36|1@0+ (1,0) [0|1] ""  GW
 SG_ VCU_MotChkACCFltFbFlg : 38|2@0+ (1,0) [0|3] ""  GW
 SG_ VCU_VehTqFltSts : 39|1@0+ (1,0) [0|1] ""  GW
 SG_ VCU_PwrAntitheftAuthentReqFlg : 41|2@0+ (1,0) [0|3] ""  GW
 SG_ VCU_PwrModSwtReq : 42|1@0+ (1,0) [0|1] ""  GW
 SG_ VCU_KL15Req : 47|2@0+ (1,0) [0|3] ""  GW
 SG_ VCU_VehMaxWhlTq : 55|16@0+ (1,-32768) [-32768|32767] "Nm"  GW

CM_ SG_ 32 Syn_TripCntrVal_Byte0_All "Trip Counter Value";
CM_ SG_ 32 Syn_TripCntrVal_Byte1_All "Trip Counter Value";
CM_ SG_ 32 Syn_RstCntrVal_Byte0_All "Reset Counter Value";
CM_ SG_ 32 Syn_RstCntrVal_Byte1_All "Reset Counter Value";
CM_ SG_ 32 Syn_RstCntrVal_Byte2_All "Reset Counter Value";
CM_ SG_ 32 Syn_MACInfo_Byte0_All "Synchronization message Mac Info";
CM_ SG_ 32 Syn_MACInfo_Byte1_All "Synchronization message Mac Info";
CM_ SG_ 32 Syn_MACInfo_Byte2_All "Synchronization message Mac Info";
CM_ SG_ 54 TBOX_RemSeekCarCtrlCmd "Remote vehicle locating control command";
CM_ SG_ 54 TBOX_RemClsTrCmd "Close electric tail gate command remotely";
CM_ SG_ 54 TBOX_RemDrvrSeatVentnCmd "Remote driver seat ventilation command";
CM_ SG_ 54 TBOX_RemDrvrSeatHeatgCmd "Remote driver seat heating command";
CM_ SG_ 54 TBOX_RemSetWelFct "Remotely set opening and closing seat courtesy function and steering wheel courtesy function";
CM_ SG_ 54 TBOX_RemPassSeatVentnCmd "Remote passenger seat ventilation command";
CM_ SG_ 54 TBOX_RemPassSeatHeatgCmd "Remote passenger seat heating command";
CM_ SG_ 54 TBOX_ClsAVMFct_ICC "Turn off ICC remote panoramic function";
CM_ SG_ 54 TBOX_ClsRemAVMFct_AVAP "Turn off AVAP signal remote panoramic function";
CM_ SG_ 54 TBOX_RemSetFolwMeFct_BCM "Remotely set BCM follow me home function, headlamp delay off time";
CM_ SG_ 54 TBOX_RemSetCtrlLockFct_PKC "Remote setting opening and closing inductive PEPS unlocking function";
CM_ SG_ 54 TBOX_RemSetKickSnsrFct "Remote setting turns on and off the foot kick sensor function";
CM_ SG_ 54 TBOX_VideoCtrlReq "Video control request";
CM_ SG_ 54 TBOX_VoiceBlowerLimReq "Voice Blower Limit Rquest";
CM_ SG_ 54 TBOX_RemCtrlCmdFb "TBOX remote control command feedback
";
CM_ SG_ 54 TBOX_CtrlReMirrReq "Control rearview mirror request";
CM_ SG_ 54 TBOX_eCallMuteSt "Emergency Call Mute status";
CM_ SG_ 54 TBOX_RemReScrnHeatgCmd "Remote rear screen heating command";
CM_ SG_ 54 TBOX_eCallSt "eCall status";
CM_ SG_ 88 TBOX_58_SSecOC_Fresh_Byte0 "Short SecOC Fresh signal byte 0 on CAN";
CM_ SG_ 88 TBOX_58_SSecOC_MAC_Byte0 "Short SecOC MAC signal byte 0 on CAN";
CM_ SG_ 88 TBOX_58_SSecOC_MAC_Byte1 "Short SecOC MAC signal byte 1 on CAN";
CM_ SG_ 88 TBOX_58_SSecOC_MAC_Byte2 "Short SecOC MAC signal byte 2 on CAN";
CM_ SG_ 89 ACU_59_CheckSum "ACU_59_CheckSum (E2E data ID: 0x98) ";
CM_ SG_ 89 ACU_59_AliveCounter "ACU_0x59_Message counterACU_59_AliveCounter";
CM_ SG_ 89 ACU_FrntCrashOutpSts "Front Crash Status";
CM_ SG_ 89 ACU_RiSideCrashOutpSts "Right Side Crash Status";
CM_ SG_ 89 ACU_LeSideCrashOutpSts "Left Side Crash Status";
CM_ SG_ 89 ACU_RearCrashOutpSts "Rear Crash Status";
CM_ SG_ 89 ACU_RollovrCrashOutpSts "Rollover Crash Status";
CM_ SG_ 89 ACU_Crash_cfm "Crash confirm signal";
CM_ SG_ 117 VCU_SUB_ID_75 "SUB_ID_75";
CM_ SG_ 117 VCU_LrngSts "VCU learning state";
CM_ SG_ 119 VCU_SUB_ID_77 "SUB_ID_77";
CM_ SG_ 119 VCU_LrngData0 "VCU_LEARNING_DATA_0";
CM_ SG_ 119 VCU_LrngData1 "VCU_LEARNING_DATA_1";
CM_ SG_ 119 VCU_LrngData2 "VCU_LEARNING_DATA_2";
CM_ SG_ 119 VCU_LrngData3 "VCU_LEARNING_DATA_3";
CM_ SG_ 119 VCU_LrngData4 "VCU_LEARNING_DATA_4";
CM_ SG_ 119 VCU_LrngData5 "VCU_LEARNING_DATA_5";
CM_ SG_ 119 VCU_LrngData6 "VCU_LEARNING_DATA_6";
CM_ SG_ 121 TBOX_LrnFbInfoClassn "Classification of learning feedback information";
CM_ SG_ 121 TBOX_LrngSts "Tbox learning state";
CM_ SG_ 122 TBOX_LrngSubID_7A "Subfunction identification of learning response message";
CM_ SG_ 122 TBOX_LrngData1 "Learning data";
CM_ SG_ 122 TBOX_LrngData2 "Learning data";
CM_ SG_ 122 TBOX_LrngData3 "Learning data";
CM_ SG_ 122 TBOX_LrngData4 "Learning data";
CM_ SG_ 122 TBOX_LrngData5 "Learning data";
CM_ SG_ 122 TBOX_LrngData6 "Learning data";
CM_ SG_ 122 TBOX_LrngData7 "Learning data";
CM_ SG_ 147 VCU_93_CheckSum "CheckSum(E2E data ID: 0x24)";
CM_ SG_ 147 VCU_93_AliveCounter "Rolling counter";
CM_ SG_ 147 VCU_EmgyShutOff "Emergency shut down request from  VCU";
CM_ SG_ 147 VCU_IsolationMonitor_Rq "Request for isolation Monitoring";
CM_ SG_ 147 VCU_Set_Chrg_Mod "Set BMS to charging Modes";
CM_ SG_ 147 VCU_Set_BMS_Mod "Set BMS to different Modes";
CM_ SG_ 147 VCU_HVBActivateDeactivateRq "Close or open contactors to activate or deactivate HV";
CM_ SG_ 147 VCU_Set_Balc_Mod "Set BMS balancing mode ";
CM_ SG_ 147 VCU_93_SSecOC_Fresh_Byte0 "Short SecOC Fresh signal byte 0 on CAN";
CM_ SG_ 147 VCU_93_SSecOC_MAC_Byte0 "Short SecOC MAC signal byte 0 on CAN";
CM_ SG_ 147 VCU_93_SSecOC_MAC_Byte1 "Short SecOC MAC signal byte 1 on CAN";
CM_ SG_ 147 VCU_93_SSecOC_MAC_Byte2 "Short SecOC MAC signal byte 2 on CAN";
CM_ SG_ 233 BMS_Bat_HVmeasure_CheckSum "Message CheckSum(E2E data ID: 0x26)";
CM_ SG_ 233 BMS_Bat_HVmeasure_AliveCounter "Rolling counter";
CM_ SG_ 233 BMS_Bat_HVmeasure_Current "Values from IVT [A], actual current in HV circuit";
CM_ SG_ 233 BMS_Bat_Hvmeasure_V_Pack "Values from IVT [V], (U1) - Battery voltage";
CM_ SG_ 235 BMS_Critical_Error_Flg_CheckSum "CheckSum  (E2E data ID: 0x21)";
CM_ SG_ 235 BMS_Critical_Error_Flg_AliveCoun "Rolling counter";
CM_ SG_ 235 BMS_ErrorWarning_OverChargeCurre "Battery pack charge current is over the operational limit. The limit value can be calculated as   SOF current prediction value  - 5%";
CM_ SG_ 235 BMS_ErrorActive_OverChargeCurren "Battery pack charge current is over the safety limit. This limit value is calculated in the SOF algorithm and dynamically updated continuously. ";
CM_ SG_ 235 BMS_ErrorWarning_OverDischargeCu "Battery pack discharge current is over the operational limit.  The limit value can be calculated as   SOF current prediction  value - 5%";
CM_ SG_ 235 BMS_ErrorActive_OverDischargeCur "Battery pack discharge current is over the safety limit. This limit value is calculated in the SOF algorithm and dynamically updated continuously. ";
CM_ SG_ 235 BMS_ErrorWarning_ChargePowerLimi "HV system charge power is over the operational limit.  The limit value can be calculated as   SOF value - 5%";
CM_ SG_ 235 BMS_ErrorActive_ChargePowerLimit "HV system charge power is over the safety limit. This limit value is calculated in the SOF algorithm and dynamically updated continuously. ";
CM_ SG_ 235 BMS_ErrorWarning_DischargePowerL "HV system discharge power is over the operational limit.  The limit value can be calculated as   SOF value - 5%";
CM_ SG_ 235 BMS_ErrorActive_DischargePowerLi "HV system discharge power is over the safety limit.  This limit value is calculated in the SOF algorithm and dynamically updated continuously. ";
CM_ SG_ 235 BMS_ErrorWarning_SOC_Low "The currently measured SOC value has reached the warning threshold: SOC system limit ";
CM_ SG_ 235 BMS_ErrorActive_SOC_Low "Current measured SOC value is below of the minimum allowed system limit";
CM_ SG_ 235 BMS_ErrorWarning_Iso "Isolation resistance between HV+ and Ground, or HV- and Ground is under operational limit BMS_Bat_Iso_Warn";
CM_ SG_ 235 BMS_ErrorActive_Iso_Crit "Isolation resistance between HV+ and Ground, or HV- and Ground is under safety limit BMS_Bat_VehIso_Err";
CM_ SG_ 235 BMS_ErrorActive_AbsChargeCurrent "   HV system charge current has exceeded max system  limit";
CM_ SG_ 235 BMS_ErrorActive_AbsDischargeCurr "   HV system discharge current has exceeded max system  limit";
CM_ SG_ 235 BMS_ErrorActive_AbsChargePowerLi "HV system charge power has exceeded max system  limit";
CM_ SG_ 235 BMS_ErrorActive_AbsDischargePowe "HV system charge power has exceeded max system  limit";
CM_ SG_ 235 BMS_ErrorWarning_overcurrent_Pre "Actual HV battery charge or discharge current has exceed the threshold";
CM_ SG_ 235 BMS_ErrorActive_ServState "Service disconnect loop interrupted,  HW reaction will take 500ms BMS_Bat_ServState";
CM_ SG_ 235 BMS_SystemError_KL30C "(Rudimentary) crash signal occured, HW reaction will take 500ms";
CM_ SG_ 235 BMS_SystemError_OmmissionOfKL15 "The clam 15 was suddenly switched off in HV -ON state.";
CM_ SG_ 235 BMS_SystemError_HV_Interlock "HV interlock loop is interrupted, HW reaction will take 500ms";
CM_ SG_ 235 BMS_SystemError_HV_Fuse "The fuse after the contactors was fused due to a short circuit or because the circuit is not closed. This fault can be detected during initialization or in the HV-On state.";
CM_ SG_ 235 BMS_CommError_CommFailure "Communication failure to slave measuremnt modules";
CM_ SG_ 235 BMS_CommWarning_PEC_High "Warning package error count high (checksum)";
CM_ SG_ 235 BMS_CommError_PEC_High "Error package error count high (checksum)";
CM_ SG_ 235 BMS_HVlinkError_VCU_Comm_Failure "VCU_BMS_Control message wasn't received for longer than the VCU_HeartBeat Timeout value";
CM_ SG_ 235 BMS_HVlinkError_Iso_Dev " Status Device err or Kl.31 err.  BMS_Bat_ISO_ERR";
CM_ SG_ 235 BMS_HVlinkError_Iso_Dig_Sig "Device fault, earth connection fault, Undervoltage detected or device switched off BMS_Bat_IntIso_Err";
CM_ SG_ 235 BMS_HVlinkError_ContactorWelded "-A- HV contactor has been welded and no longer opens";
CM_ SG_ 235 BMS_HVlinkError_HV_Interlock_Bad "the PWM frequency or the duty cycle are outside the tolerance range.";
CM_ SG_ 235 BMS_HardwareError_LCM_General_Fa "General hardware error of the master board";
CM_ SG_ 235 BMS_SoftwareError_General_Failr "General software failure";
CM_ SG_ 235 BMS_ErrorWarning_CellOverVoltage "Cell voltage(s) reached over operational limit";
CM_ SG_ 235 BMS_ErrorActive_CellOverVoltage "Cell voltage(s) reached over safety limit";
CM_ SG_ 235 BMS_ErrorWarning_CellUnderVoltag "Cell voltage(s) reached under operational limit";
CM_ SG_ 235 BMS_ErrorActive_CellUnderVoltage "Cell voltage(s) reached under safety limit";
CM_ SG_ 235 BMS_ErrorWarning_CellTempHigh " Cell temperature sensor(s) readout reached over operational limits";
CM_ SG_ 235 BMS_ErrorActive_CellTempHigh " Cell temperature sensor(s) readout reached over safety limits";
CM_ SG_ 235 BMS_ErrorWarning_CellTempLow " Cell temperature sensor(s) readout reached under operational limits";
CM_ SG_ 235 BMS_ErrorActive_CellTempLow " Cell temperature sensor(s) readout reached under safety limits";
CM_ SG_ 235 BMS_ErrorWarning_HV_OverVoltage "U1 Measurement over operational limits";
CM_ SG_ 235 BMS_ErrorActive_HV_OverVoltage "U1 Measurement over safety limits";
CM_ SG_ 235 BMS_ErrorWarning_HV_UnderVoltage "U1 Measurement under operational limits";
CM_ SG_ 235 BMS_ErrorActive_HV_UnderVoltage "U1 Measurement outside limits";
CM_ SG_ 235 BMS_PVIU_CANcommError "PVIU CAN Communication Error status";
CM_ SG_ 236 BMS_Curr_PST_CheckSum "CheckSum(E2E data ID: 0x2C)";
CM_ SG_ 236 BMS_Curr_PST_AliveCounter "Rolling counter";
CM_ SG_ 236 BMS_Bat_D_MAXcurr_PST "predicted discharge current for short time [10s value]";
CM_ SG_ 236 BMS_Bat_C_MAXcurr_PST "   predicted charge current for short time [10s value] When vehicle driving, this signal is used as a recharging (recuperation) current limit";
CM_ SG_ 237 BMS_OverallStatus_CheckSum "Checksum(E2E data ID: 0x22)";
CM_ SG_ 237 BMS_OverallStatus_AliveCounter "Rolling counter";
CM_ SG_ 237 BMS_OperationStates "BMS operational states";
CM_ SG_ 237 BMS_BallancingStatus "BMS balancing status";
CM_ SG_ 237 BMS_ErrorCategory_CAT0 "Escalation level of an error";
CM_ SG_ 237 BMS_ErrorCategory_CAT1 "Escalation level of an error";
CM_ SG_ 237 BMS_ErrorCategory_CAT2 "Escalation level of an error";
CM_ SG_ 237 BMS_ErrorCategory_CAT3 "Escalation level of an error";
CM_ SG_ 237 BMS_ErrorCategory_CAT4 "Escalation level of an error";
CM_ SG_ 237 BMS_ErrorCategory_CAT5 "Escalation level of an error";
CM_ SG_ 237 BMS_ErrorCategory_CAT6 "Escalation level of an error";
CM_ SG_ 237 BMS_ErrorCategory_CAT7 "Escalation level of an error";
CM_ SG_ 237 BMS_ErrorCategory_CAT8 "Escalation level of an error";
CM_ SG_ 237 BMS_HardwareStatus_OK "BMS Hardware OK Flag, Internal Temp. And and Voltages are okey";
CM_ SG_ 237 BMS_ErrorCategory_Mem_Empty "BMS Error memory is empty and OK";
CM_ SG_ 237 BMS_ConfigurationStatus_OK "BMS Configuration was successful";
CM_ SG_ 237 BMS_MeasurementModules_OK "BMS Measurement Modules OK";
CM_ SG_ 237 BMS_BatteryGeneralStatus_OK "BMS Battery status OK";
CM_ SG_ 237 BMS_SDIL_Sts "BMS Service Disconnect status";
CM_ SG_ 237 BMS_CL30C_Sts "BMS Clamp 30  status";
CM_ SG_ 237 BMS_CL15_Sts "BMS Clamp 15 status";
CM_ SG_ 237 BMS_HVIL_OK "BMS BMS HV Interlock OK";
CM_ SG_ 237 BMS_HV_ContactorsStatus_OK "BMS High Voltage / Main contactors OK";
CM_ SG_ 237 BMS_SW_Status_OK "BMS Algorithm status OK";
CM_ SG_ 237 BMS_CurrentSensor_OK "BMS IVT (Current Sensor) OK";
CM_ SG_ 237 BMS_IsolatoinStatus_OK "BMS Insolation and IMD OK ";
CM_ SG_ 237 BMS_StateMAchine_Status "Status of system state machine";
CM_ SG_ 237 BMS_BDU_Status "Status of battery disconnect unit";
CM_ SG_ 238 BMS_Volt_PST_CheckSum "CheckSum(E2E data ID: 0x2D)";
CM_ SG_ 238 BMS_Volt_PST_AliveCounter "Rolling counter";
CM_ SG_ 238 BMS_Bat_D_MAXvolt_PST "predicted discharge REESS voltage for short time [10s value]";
CM_ SG_ 238 BMS_Bat_C_MAXvolt_PS "predicted charge REESS voltage for short time [10s value]";
CM_ SG_ 242 BMS_Cell_Volt_max "The highest cell voltage of the battery pack [mV]";
CM_ SG_ 242 BMS_Cell_Volt_min "The lowest cell voltage of the battery pack [mV]";
CM_ SG_ 242 BMS_Cell_Volt_nom "Average cell voltage of the battery pack [mV]";
CM_ SG_ 242 BMS_CL30C_Volt "CL30C analog value in Volt ";
CM_ SG_ 276 ESP_114_CheckSum "ESP_114_Message checksum (E2E data ID: 0x72)";
CM_ SG_ 276 ESP_114_AliveCounter "EP_114 _Message counter";
CM_ SG_ 276 ESP_OTARdy_Fb "ESP OTA ready status feedback";
CM_ SG_ 276 ESP_FltIndcn_DTC "ESP/TCS fault indication Signal indicates failure monitoring of ESP function. Not used for ABS";
CM_ SG_ 276 ESP_ActvSig_VDC "ESP activation signal VDC operating When ESP is active shall the system send out a bus signal. Not used for ABS.";
CM_ SG_ 276 ESP_ActvSig_TCS "TCS activation signal TCS operating(including DTC operating)When TCS is active shall the system send out a bus signal. Not used for ABS.";
CM_ SG_ 276 ESP_ActvSig_EBD "EBD activation signal indicating EBD in active control or not.";
CM_ SG_ 276 ESP_ActvSig_DTC "DTC activation signal indicate DTC in active control or not.";
CM_ SG_ 276 ESP_WarningOn "ESP brake fault turning on request With this signal ESP requests the warning in the dashboard.";
CM_ SG_ 276 ESP_Actvndcn_CDD "CDD operation indication indicating CDD is working or not.";
CM_ SG_ 276 ESP_FltIndcn_CDD "CDD fault indication indicating CDD is available or not.";
CM_ SG_ 276 ESP_ActvIndcn_ABA "ABA working indication ABA is active.";
CM_ SG_ 276 ESP_FltIndcn_ABA "ABA fault indication the ABA function is available.";
CM_ SG_ 276 ESP_ActvIndcn_ABP "ABP operation indication Prefill (ABP) is active.";
CM_ SG_ 276 ESP_FltIndcn_ABP "ABP fault indication Prefill (ABP) is available.";
CM_ SG_ 276 ESP_ActvIndcn_AEB "AEB operation indication ESP is excuting AEB braking function.";
CM_ SG_ 276 ESP_FltIndcn_AEB "AEB fault indication AEB is available.";
CM_ SG_ 276 ESP_ActvIndcn_AWB "AWB operation indication AWB is active(brake jerk).";
CM_ SG_ 276 ESP_FltIndcn_AWB "AWB fault indication AWB is available. Feedback of AWB activation for ACC.";
CM_ SG_ 276 ESP_VehStandstillIndcn "Vehicle stop indication indicating whether the vehicle is standstill or not; must not be set until standstill is surely reached.";
CM_ SG_ 276 ESP_BrkOverTIndcn "Brake disc high temperature indication , set 1 to exit ACC function indicating brake temperature too high or not.";
CM_ SG_ 276 ESP_FltIndcn_VDC "ESP/TCS fault indication Signal indicates failure monitoring of ESP function. Not used for ABS";
CM_ SG_ 276 ESP_ActvIndcn_CDD_AP "ECS Active indication_CDD_APWhen VLC AP is active shall the system send out a bus signal.";
CM_ SG_ 276 ESP_FltIndcn_CDD_AP "Signal from ESC indicates whether CDD_AP is activated When VLC AP is active shall the system send out a bus signal.";
CM_ SG_ 336 MCU_F_150_CheckSum "Front MCU_150_Message checksum(E2E data ID: 0x29)";
CM_ SG_ 336 MCU_F_150_AliveCounter "MCU_150_Message Counter FrontMCU_F_150_AliveCounter";
CM_ SG_ 336 MCU_F_CrtTqVld "Effective torque of front drive motorMotorFTorquevalidflag";
CM_ SG_ 336 MCU_F_CrtRotDir "Current rotation direction of front drive motorMotorFRotingdirection";
CM_ SG_ 336 MCU_F_CrtSpd "Current speed of front drive motorMotorFSpeed";
CM_ SG_ 336 MCU_F_CrtTq "Current torque of front drive motorMotorFTorque";
CM_ SG_ 336 MCU_F_CrtSpdSigVld "Effective position of front drive motor current speed signalMotorFSpeedsignalvalidflag";
CM_ SG_ 336 MCU_F_CrtMod "Current operating mode of front drive motorMotorFworkingmode";
CM_ SG_ 336 MCU_F_HVActvDchaSts "High-voltage active discharge state of front MCUHVActiveDischargeState";
CM_ SG_ 336 MCU_F_SlipCtrlActMode "the Anti-Slip Control (ASC or ASR on german) state";
CM_ SG_ 336 MCU_F_AlrmLamp_FS "Warning lamp_front drive motor (functional safety)";
CM_ SG_ 336 MCU_F_HVChkEndFlg "High voltage detection completion flag of front MCUMCUFHVCheckStates";
CM_ SG_ 337 MCU_R_151_CheckSum "Rear MCU_151_Message checksum (E2E data ID: 0x34)";
CM_ SG_ 337 MCU_R_151_AliveCounter "Rear MCU_151_Message counterMCU_R_151_AliveCounter";
CM_ SG_ 337 MCU_R_CrtTqVld "Effective torque of rear drive motorMotorRTorquevalidflag";
CM_ SG_ 337 MCU_R_CrtRotDir "Current rotation direction of rear drive motorMotorRRotingdirection";
CM_ SG_ 337 MCU_R_CrtSpd "Current speed of rear drive motorMotorRSpeed";
CM_ SG_ 337 MCU_R_CrtTq "Current torque of rear drive motorMotorRTorque";
CM_ SG_ 337 MCU_R_CrtSpdSigVld "Effective position of current speed signal of rear drive motorMotorRSpeedsignalvalidflag";
CM_ SG_ 337 MCU_R_CrtMod "Current working mode of rear drive motorMotorRworkingmode";
CM_ SG_ 337 MCU_R_Decoup_State "Disconnect status";
CM_ SG_ 337 MCU_R_HVActvDchaSts "High-voltage active discharge state of rear MCUHVActiveDischargeState";
CM_ SG_ 337 MCU_R_SlipCtrlActMode "the Anti-Slip Control (ASC or ASR on german) state";
CM_ SG_ 337 MCU_R_AlrmLamp_FS "Warning lamp_rear drive motor (functional safety)";
CM_ SG_ 337 MCU_R_HVChkEndFlg "High voltage detection completion flag of rear drive motor controllerMCURHVCheckStates";
CM_ SG_ 345 ACU_159_CheckSum "ACU_0x159_Message Checksum ( E2E data ID:  0x97)";
CM_ SG_ 345 ACU_159_AliveCounter "ACU_0x159_Message counterACU_159_AliveCounter";
CM_ SG_ 345 ACU_Pass_OCS_St "Passenger Occupant Status OCS (not for China)";
CM_ SG_ 345 ACU_AirBagSysAlrmLampSts "State of warning lamp of airbag system";
CM_ SG_ 345 ACU_Pass_Airbag_LED "Passenger LED Status";
CM_ SG_ 345 ACU_Drvr_Occpt_St "Driver Occupant Status";
CM_ SG_ 345 ACU_BucSwtStFrntDrvr "Buckle switch state  front driver";
CM_ SG_ 345 ACU_BucSwtStFrntPass "Buckle switch state  front passenger";
CM_ SG_ 345 ACU_SeatTrkPosnSwtFrntDrvr "Seat Track Position Sensor  Front Driver";
CM_ SG_ 345 ACU_SeatTrkPosnSwtFrntPass "Seat Track Position Sensor  Front Passenger";
CM_ SG_ 393 CIM_189_CheckSum "CIM_189_Message checksum ( 0x27)CIM_189_CheckSum";
CM_ SG_ 393 CIM_189_AliveCounter "CIM_189 _Message CounterCIM_189_AliveCounter";
CM_ SG_ 393 CIM_PBtnSts1 "Gear P button1 status";
CM_ SG_ 393 CIM_PBtnSts2 "Gear P button2 status";
CM_ SG_ 393 CIM_PBtnVld "Gear P button valid";
CM_ SG_ 393 CIM_GearLvrCrtPosnInfo "Holding current position information of gear lever";
CM_ SG_ 393 CIM_GearleverFltSts "Gear fault state";
CM_ SG_ 393 CIM_OTARdy_Fb "CIM OTA ready status feedback";
CM_ SG_ 416 VCU_ECC_PwrMax "maximal power that can be used by ECC HV components";
CM_ SG_ 416 VCU_ECC_PwrMin "minimal power that must be used by the ECC HV components.";
CM_ SG_ 416 VCU_DCDCPwrLimCmd "DC/DC power limit command";
CM_ SG_ 425 ECC_VCU_PwrReq "actual power requested(used) by the ECC HV components";
CM_ SG_ 425 ECC_OTARdy_Fb "ECC OTA ready status feedback";
CM_ SG_ 438 PKC_1B6_CheckSum "PKC_1B6_Message inspection (0x19)PKC_1B6_CheckSum";
CM_ SG_ 438 PKC_1B6_AliveCounter "PKC_1B6_AliveCounter";
CM_ SG_ 438 PKC_TpMnvrCancel "Cancel of trained parking maneuver";
CM_ SG_ 438 PKC_TpActDeactInp "Activation and deactivation of trained parking";
CM_ SG_ 438 PKC_RemPwrOnOffReq "Remote power on/off request";
CM_ SG_ 438 PKC_RemDrvgReq "Remote driving request";
CM_ SG_ 438 PKC_RemChrgDchaGunUnlckCmd "Remote charge and discharge gun unlocking command";
CM_ SG_ 438 PKC_RmteDviceBattLvl "Remote control device battery power Indicates the remote device battery percentage.";
CM_ SG_ 438 PKC_BLE_Online "Mobile APP online signal";
CM_ SG_ 438 PKC_DviceRngeDist "Remote control device distance Remote device distance from vehicle.";
CM_ SG_ 438 PKC_DviceAliveCnt "Heartbeat signal Remote device heart beat.";
CM_ SG_ 438 PKC_MnvreEnblInput "RPA parking switch state Remote control deadman switch pressed or unpressed.";
CM_ SG_ 438 PKC_RapActDeactInp "RPA Cancel Request Parking maneuvering cancel request.";
CM_ SG_ 438 PKC_MnvrRemsumeKey "RPA recovery request Parking maneuverin Remsume request.";
CM_ SG_ 438 PKC_MnvrRtnStartKey "RPA return start position request Request return to original point.";
CM_ SG_ 438 PKC_AlcInterlockReqPromt "Alcohol test result";
CM_ SG_ 438 PKC_NFCReminderPromt "If more than 30 seconds elapsed since the unlocking the vehicle with the NFC";
CM_ SG_ 532 VCU_214_234_CheckSum "VCU_214_Message checksum (E2E data ID: 0x12)";
CM_ SG_ 532 VCU_214_234_AliveCounter "VCU_214_Packet counterVCU_214_AliveCounter";
CM_ SG_ 532 VCU_RdyLamp "READY lamp";
CM_ SG_ 532 VCU_BrkLampCtrlSts "Stop lamp control state";
CM_ SG_ 532 VCU_RemWakeUpEndFlg "Terminal wake-up end flag bit";
CM_ SG_ 532 VCU_StgyGearSig "Strategy gear signal";
CM_ SG_ 532 VCU_ShiftMisoper "Gear misoperation";
CM_ SG_ 532 VCU_GearSigVld "Effective bit of gear signal";
CM_ SG_ 532 VCU_GearSig "Gear signal";
CM_ SG_ 532 VCU_ACCRdy "ACC ready signal from VCU";
CM_ SG_ 532 VCU_ParkRdy "Park ready signal from VCU";
CM_ SG_ 532 VCU_APSPercVld "Effective position of accelerator pedal opening";
CM_ SG_ 532 VCU_VehSt "State of complete vehicle";
CM_ SG_ 532 VCU_APSPerc "Accelerator pedal opening";
CM_ SG_ 532 VCU_BrkSig "Brake signal";
CM_ SG_ 532 VCU_BrkSigVld "Effective bit of brake signal";
CM_ SG_ 532 VCU_DrvModSigFb "Driving mode signal feedback to ICC";
CM_ SG_ 532 VCU_DrvModShiftMisoper "Driving mode switching error operation";
CM_ SG_ 532 VCU_SpclTerrainModEnaSig "All-terrain driving mode enable signal";
CM_ SG_ 532 VCU_214_SSecOC_Fresh_Byte0 "Short SecOC Fresh signal byte 0 on CAN";
CM_ SG_ 532 VCU_214_SSecOC_MAC_Byte0 "Short SecOC MAC signal byte 0 on CAN";
CM_ SG_ 532 VCU_214_SSecOC_MAC_Byte1 "Short SecOC MAC signal byte 1 on CAN";
CM_ SG_ 532 VCU_214_SSecOC_MAC_Byte2 "Short SecOC MAC signal byte 2 on CAN";
CM_ SG_ 533 BMS_215_CheckSum "BMS_215_Message checksum( E2E data ID: 0x13)";
CM_ SG_ 533 BMS_215_AliveCounter "BMS_215 _Message counterBMS_215_AliveCounter";
CM_ SG_ 533 BMS_PwrBattOverTFlt_FS "Power battery temperature too high (functional safety)";
CM_ SG_ 533 BMS_PwrBattOverCrtFlt_FS "Power battery overcurrent fault (functional safety)";
CM_ SG_ 533 BMS_PwrBattNegRlyAdh_FS "Connection of relay at negative terminal of traction battery (functional safety)";
CM_ SG_ 533 BMS_PwrBattPosRlyAdh_FS "Traction battery positive terminal relay sticking (functional safety)";
CM_ SG_ 533 BMS_CellUnderrVoltFlt_FS "Single undervoltage fault (functional safety)";
CM_ SG_ 533 BMS_PwrBattCellOverVolt_FS "Power battery cell overvoltage (functional safety)";
CM_ SG_ 533 BMS_BattInlTSnsrFlt "Battery inlet water temperature sensor fault";
CM_ SG_ 533 BMS_BattOutlTSnsrFlt "Battery outlet water temperature sensor fault";
CM_ SG_ 533 BMS_PwrBattPrecRlyAdh_FS "Traction battery pre-charge relay blocking (functional safety)";
CM_ SG_ 533 BMS_AlrmLamp_FS "Warning lamp_BMS (functional safety)";
CM_ SG_ 533 BMS_PwrBattLoadTotVoltV3_FS "Total voltage of traction battery load end V3 (functional safety)";
CM_ SG_ 533 BMS_FctSftyErrCod "Functional safety fault codeFunctional safety code";
CM_ SG_ 549 VCU_225_CheckSum "VCU_225_message checksum ( E2E data ID: 0x2A)";
CM_ SG_ 549 VCU_225_AliveCounter "VCU_225_Message counterVCU_225_AliveCounter";
CM_ SG_ 549 VCU_BusCrtEstim "Estimated value of bus current";
CM_ SG_ 549 VCU_VehFltProcLvl "Vehicle fault handling level";
CM_ SG_ 549 VCU_OverMod "Overtaking Mode";
CM_ SG_ 549 VCU_MotChkACCFltFbFlg "Motor detection ACC fault feedback flag bit";
CM_ SG_ 549 VCU_VehTqFltSts "Vehicle torque fault state";
CM_ SG_ 549 VCU_PwrAntitheftAuthentReqFlg "Power anti-theft authentication request flag position";
CM_ SG_ 549 VCU_PwrModSwtReq "Power mode switch request";
CM_ SG_ 549 VCU_VehMaxWhlTq "Maximum allowable wheel end torque of the vehicle (sum)";
BA_DEF_  "NmAsrWaitBusSleepTime" INT 0 65535;
BA_DEF_  "NmAsrTimeoutTime" INT 0 65535;
BA_DEF_  "NmAsrRepeatMessageTime" INT 0 65535;
BA_DEF_ BU_  "NmAsrNodeIdentifier" HEX 0 255;
BA_DEF_ BU_  "NmAsrNode" ENUM  "No","Yes";
BA_DEF_  "E2EP01ProfileName" STRING ;
BA_DEF_  "NmAsrMessageCount" INT 1 256;
BA_DEF_  "E2EP01ProfileBehavior" ENUM  "PRE_R4_2","R4_2";
BA_DEF_ BO_  "NmAsrMessage" ENUM  "No","Yes";
BA_DEF_ BU_  "NmAsrCanMsgReducedTime" INT 320 640;
BA_DEF_ BU_  "NmAsrCanMsgCycleOffset" INT 0 65535;
BA_DEF_ SG_  "GenSigCycleTime" INT 0 0;
BA_DEF_  "NmAsrBaseAddress" HEX 0 2047;
BA_DEF_  "NmAsrCanMsgCycleTime" INT 0 0;
BA_DEF_ BO_  "NmMessage" ENUM  "No","Yes";
BA_DEF_ BO_  "SC_Message" ENUM  "No","Yes","Yes, split message";
BA_DEF_ BO_  "DiagState" ENUM  "No","Yes";
BA_DEF_ BO_  "SC_LinkPos" INT 0 65535;
BA_DEF_ BO_  "DiagRequest" ENUM  "No","Yes";
BA_DEF_ BO_  "DiagFdOnly" ENUM  "No","Yes";
BA_DEF_ BO_  "DiagResponse" ENUM  "No","Yes";
BA_DEF_ BO_  "SCP_AuthInfoTxLength" INT 0 512;
BA_DEF_  "BusBaudateData" INT 0 10000;
BA_DEF_  "E2EP01DataIdMode" ENUM  "all16Bit","alternating8Bit","lower8Bit","lower12Bit";
BA_DEF_ BO_  "GenMsgSendType" ENUM  "Cyclic","NotUsed","NotUsed","NotUsed","NotUsed","NotUsed","NotUsed","IfActive","NoMsgSendType";
BA_DEF_ BO_  "SCP_DataId" INT 0 65535;
BA_DEF_  "BusBaudateOther" INT 0 10000;
BA_DEF_ BO_  "GenMsgCycleTime" INT 0 0;
BA_DEF_ BO_  "SCP_FreshnessValueId" INT 0 65535;
BA_DEF_ BO_  "SCP_FreshnessValueLength" INT 0 512;
BA_DEF_ SG_  "GenSigStartValue" INT 0 0;
BA_DEF_ BO_  "SCL_CryptographicMessageID" INT 0 65535;
BA_DEF_ SG_  "GenSigInactiveValue" INT 0 0;
BA_DEF_ SG_  "GenSigSendType" ENUM  "Cyclic","OnWrite","OnWriteWithRepetition","OnChange","OnChangeWithRepetition","IfActive","IfActiveWithRepetition","NoSigSendType";
BA_DEF_ BO_  "SCP_FreshnessValueTxLength" INT 0 512;
BA_DEF_ BO_  "GenMsgCycleTimeFast" INT 0 0;
BA_DEF_ BO_  "GenMsgNrOfRepetition" INT 0 0;
BA_DEF_ BO_  "DiagConnection" INT 0 65535;
BA_DEF_ BO_  "GenMsgDelayTime" INT 0 0;
BA_DEF_  "DBName" STRING ;
BA_DEF_  "BusBaudrate" INT 0 10000;
BA_DEF_ BU_  "NodeLayerModules" STRING ;
BA_DEF_ BU_  "ILUsed" ENUM  "No","Yes";
BA_DEF_ BU_  "DiagStationAddress" HEX 0 255;
BA_DEF_ BU_  "NmNode" ENUM  "No","Yes";
BA_DEF_ BU_  "NmStationAddress" HEX 0 65535;
BA_DEF_ BU_  "NmCAN" INT 0 2;
BA_DEF_  "NmType" STRING ;
BA_DEF_  "NmBaseAddress" HEX 1024 2047;
BA_DEF_  "NmMessageCount" INT 0 255;
BA_DEF_ BO_  "CANFD_BRS" ENUM  "0","1";
BA_DEF_ BO_  "VFrameFormat" ENUM  "StandardCAN","ExtendedCAN","reserved","reserved","reserved","reserved","reserved","reserved","reserved","reserved","reserved","reserved","reserved","reserved","StandardCAN_FD","ExtendedCAN_FD";
BA_DEF_ BO_  "GenMsgILSupport" ENUM  "No","Yes";
BA_DEF_ BO_  "GenMsgStartDelayTime" INT 0 65535;
BA_DEF_  "BusType" STRING ;
BA_DEF_ BO_  "E2EP01DataLength" INT 0 65535;
BA_DEF_ BO_  "E2EP01DataId" INT 0 65535;
BA_DEF_ SG_  "sigSecLevel" STRING ;
BA_DEF_ SG_  "sigConfig" STRING ;
BA_DEF_ SG_  "sigExplanation" STRING ;
BA_DEF_ SG_  "SystemSignalLongSymbol" STRING ;
BA_DEF_REL_ BU_SG_REL_  "SC_Verification" ENUM  "No","Yes";
BA_DEF_DEF_  "NmAsrWaitBusSleepTime" 1500;
BA_DEF_DEF_  "NmAsrTimeoutTime" 2000;
BA_DEF_DEF_  "NmAsrRepeatMessageTime" 3200;
BA_DEF_DEF_  "NmAsrNodeIdentifier" 0;
BA_DEF_DEF_  "NmAsrNode" "No";
BA_DEF_DEF_  "E2EP01ProfileName" "PROFILE_01";
BA_DEF_DEF_  "NmAsrMessageCount" 128;
BA_DEF_DEF_  "E2EP01ProfileBehavior" "R4_2";
BA_DEF_DEF_  "NmAsrMessage" "No";
BA_DEF_DEF_  "NmAsrCanMsgReducedTime" 320;
BA_DEF_DEF_  "NmAsrCanMsgCycleOffset" 0;
BA_DEF_DEF_  "GenSigCycleTime" 0;
BA_DEF_DEF_  "NmAsrBaseAddress" 1024;
BA_DEF_DEF_  "NmAsrCanMsgCycleTime" 640;
BA_DEF_DEF_  "NmMessage" "No";
BA_DEF_DEF_  "SC_Message" "No";
BA_DEF_DEF_  "DiagState" "No";
BA_DEF_DEF_  "SC_LinkPos" 0;
BA_DEF_DEF_  "DiagRequest" "No";
BA_DEF_DEF_  "DiagFdOnly" "No";
BA_DEF_DEF_  "DiagResponse" "No";
BA_DEF_DEF_  "SCP_AuthInfoTxLength" 0;
BA_DEF_DEF_  "BusBaudateData" 2;
BA_DEF_DEF_  "E2EP01DataIdMode" "lower8Bit";
BA_DEF_DEF_  "GenMsgSendType" "Cyclic";
BA_DEF_DEF_  "SCP_DataId" 0;
BA_DEF_DEF_  "BusBaudateOther" 500;
BA_DEF_DEF_  "GenMsgCycleTime" 0;
BA_DEF_DEF_  "SCP_FreshnessValueId" 0;
BA_DEF_DEF_  "SCP_FreshnessValueLength" 0;
BA_DEF_DEF_  "GenSigStartValue" 0;
BA_DEF_DEF_  "SCL_CryptographicMessageID" 0;
BA_DEF_DEF_  "GenSigInactiveValue" 0;
BA_DEF_DEF_  "GenSigSendType" "Cyclic";
BA_DEF_DEF_  "SCP_FreshnessValueTxLength" 0;
BA_DEF_DEF_  "GenMsgCycleTimeFast" 0;
BA_DEF_DEF_  "GenMsgNrOfRepetition" 0;
BA_DEF_DEF_  "DiagConnection" 0;
BA_DEF_DEF_  "GenMsgDelayTime" 0;
BA_DEF_DEF_  "DBName" "";
BA_DEF_DEF_  "BusBaudrate" 500;
BA_DEF_DEF_  "NodeLayerModules" "CANoeILNLVector.dll";
BA_DEF_DEF_  "ILUsed" "Yes";
BA_DEF_DEF_  "DiagStationAddress" 0;
BA_DEF_DEF_  "NmNode" "No";
BA_DEF_DEF_  "NmStationAddress" 0;
BA_DEF_DEF_  "NmCAN" 0;
BA_DEF_DEF_  "NmType" "NmAsr";
BA_DEF_DEF_  "NmBaseAddress" 1024;
BA_DEF_DEF_  "NmMessageCount" 128;
BA_DEF_DEF_  "CANFD_BRS" "1";
BA_DEF_DEF_  "VFrameFormat" "StandardCAN";
BA_DEF_DEF_  "GenMsgILSupport" "Yes";
BA_DEF_DEF_  "GenMsgStartDelayTime" 0;
BA_DEF_DEF_  "BusType" "CAN";
BA_DEF_DEF_  "E2EP01DataLength" 0;
BA_DEF_DEF_  "E2EP01DataId" 0;
BA_DEF_DEF_  "sigSecLevel" "";
BA_DEF_DEF_  "sigConfig" "";
BA_DEF_DEF_  "sigExplanation" "";
BA_DEF_DEF_REL_ "SC_Verification" "No";
BA_DEF_DEF_  "SystemSignalLongSymbol" "";
BA_ "BusBaudrate" 2000;
BA_ "BusType" "CAN FD";
BA_ "NmAsrMessageCount" 64;
BA_ "NmMessageCount" 64;
BA_ "DBName" "FM29_EVBUS_Matrix_CANFD_V3906";
BA_ "DiagStationAddress" BU_ BMS 233;
BA_ "NmAsrNodeIdentifier" BU_ BMS 7;
BA_ "NmStationAddress" BU_ BMS 7;
BA_ "DiagStationAddress" BU_ ECC 248;
BA_ "NmAsrCanMsgCycleOffset" BU_ ECC 95;
BA_ "NmAsrCanMsgReducedTime" BU_ ECC 367;
BA_ "NmAsrNode" BU_ ECC 1;
BA_ "NmAsrNodeIdentifier" BU_ ECC 19;
BA_ "NmCAN" BU_ ECC 1;
BA_ "NmNode" BU_ ECC 1;
BA_ "NmStationAddress" BU_ ECC 19;
BA_ "NmAsrCanMsgCycleOffset" BU_ GW 270;
BA_ "NmAsrCanMsgReducedTime" BU_ GW 455;
BA_ "NmAsrNode" BU_ GW 1;
BA_ "NmAsrNodeIdentifier" BU_ GW 54;
BA_ "NmCAN" BU_ GW 1;
BA_ "NmNode" BU_ GW 1;
BA_ "NmStationAddress" BU_ GW 54;
BA_ "DiagStationAddress" BU_ OBC 251;
BA_ "NmAsrNodeIdentifier" BU_ OBC 6;
BA_ "NmStationAddress" BU_ OBC 6;
BA_ "DiagStationAddress" BU_ VCU 202;
BA_ "NmAsrCanMsgCycleOffset" BU_ VCU 5;
BA_ "NmAsrCanMsgReducedTime" BU_ VCU 322;
BA_ "NmAsrNode" BU_ VCU 1;
BA_ "NmAsrNodeIdentifier" BU_ VCU 1;
BA_ "NmCAN" BU_ VCU 1;
BA_ "NmNode" BU_ VCU 1;
BA_ "NmStationAddress" BU_ VCU 1;
BA_ "GenMsgDelayTime" BO_ 32 50;
BA_ "GenMsgSendType" BO_ 32 8;
BA_ "SCP_AuthInfoTxLength" BO_ 32 24;
BA_ "SCP_DataId" BO_ 32 32;
BA_ "SCP_FreshnessValueLength" BO_ 32 40;
BA_ "SCP_FreshnessValueTxLength" BO_ 32 40;
BA_ "SC_Message" BO_ 32 1;
BA_ "GenMsgNrOfRepetition" BO_ 32 3;
BA_ "GenMsgCycleTimeFast" BO_ 32 50;
BA_ "VFrameFormat" BO_ 32 14;
BA_ "GenMsgDelayTime" BO_ 54 20;
BA_ "GenMsgSendType" BO_ 54 8;
BA_ "GenMsgNrOfRepetition" BO_ 54 3;
BA_ "GenMsgCycleTimeFast" BO_ 54 20;
BA_ "VFrameFormat" BO_ 54 14;
BA_ "GenMsgCycleTime" BO_ 88 100;
BA_ "GenMsgDelayTime" BO_ 88 30;
BA_ "GenMsgStartDelayTime" BO_ 88 30;
BA_ "SCL_CryptographicMessageID" BO_ 88 88;
BA_ "SCP_AuthInfoTxLength" BO_ 88 24;
BA_ "SCP_DataId" BO_ 88 88;
BA_ "SCP_FreshnessValueId" BO_ 88 88;
BA_ "SCP_FreshnessValueLength" BO_ 88 64;
BA_ "SCP_FreshnessValueTxLength" BO_ 88 8;
BA_ "SC_LinkPos" BO_ 88 32;
BA_ "SC_Message" BO_ 88 1;
BA_ "GenMsgNrOfRepetition" BO_ 88 3;
BA_ "GenMsgCycleTimeFast" BO_ 88 20;
BA_ "VFrameFormat" BO_ 88 14;
BA_ "E2EP01DataId" BO_ 89 152;
BA_ "E2EP01DataLength" BO_ 89 64;
BA_ "GenMsgCycleTime" BO_ 89 50;
BA_ "GenMsgCycleTimeFast" BO_ 89 10;
BA_ "GenMsgDelayTime" BO_ 89 10;
BA_ "GenMsgNrOfRepetition" BO_ 89 5;
BA_ "VFrameFormat" BO_ 89 14;
BA_ "GenMsgDelayTime" BO_ 117 20;
BA_ "GenMsgSendType" BO_ 117 8;
BA_ "GenMsgNrOfRepetition" BO_ 117 3;
BA_ "GenMsgCycleTimeFast" BO_ 117 20;
BA_ "VFrameFormat" BO_ 117 14;
BA_ "GenMsgDelayTime" BO_ 119 20;
BA_ "GenMsgSendType" BO_ 119 8;
BA_ "GenMsgNrOfRepetition" BO_ 119 3;
BA_ "GenMsgCycleTimeFast" BO_ 119 20;
BA_ "VFrameFormat" BO_ 119 14;
BA_ "GenMsgSendType" BO_ 121 8;
BA_ "GenMsgNrOfRepetition" BO_ 121 3;
BA_ "GenMsgCycleTimeFast" BO_ 121 20;
BA_ "VFrameFormat" BO_ 121 14;
BA_ "GenMsgSendType" BO_ 122 8;
BA_ "GenMsgNrOfRepetition" BO_ 122 3;
BA_ "GenMsgCycleTimeFast" BO_ 122 20;
BA_ "VFrameFormat" BO_ 122 14;
BA_ "E2EP01DataId" BO_ 147 36;
BA_ "E2EP01DataLength" BO_ 147 64;
BA_ "GenMsgCycleTime" BO_ 147 20;
BA_ "SCL_CryptographicMessageID" BO_ 147 147;
BA_ "SCP_AuthInfoTxLength" BO_ 147 24;
BA_ "SCP_DataId" BO_ 147 147;
BA_ "SCP_FreshnessValueId" BO_ 147 147;
BA_ "SCP_FreshnessValueLength" BO_ 147 64;
BA_ "SCP_FreshnessValueTxLength" BO_ 147 8;
BA_ "SC_LinkPos" BO_ 147 64;
BA_ "SC_Message" BO_ 147 1;
BA_ "VFrameFormat" BO_ 147 14;
BA_ "E2EP01DataId" BO_ 233 38;
BA_ "E2EP01DataLength" BO_ 233 64;
BA_ "GenMsgCycleTime" BO_ 233 20;
BA_ "VFrameFormat" BO_ 233 14;
BA_ "E2EP01DataId" BO_ 235 33;
BA_ "E2EP01DataLength" BO_ 235 64;
BA_ "GenMsgCycleTime" BO_ 235 20;
BA_ "VFrameFormat" BO_ 235 14;
BA_ "E2EP01DataId" BO_ 236 44;
BA_ "E2EP01DataLength" BO_ 236 64;
BA_ "GenMsgCycleTime" BO_ 236 20;
BA_ "VFrameFormat" BO_ 236 14;
BA_ "E2EP01DataId" BO_ 237 34;
BA_ "E2EP01DataLength" BO_ 237 64;
BA_ "GenMsgCycleTime" BO_ 237 20;
BA_ "VFrameFormat" BO_ 237 14;
BA_ "E2EP01DataId" BO_ 238 45;
BA_ "E2EP01DataLength" BO_ 238 64;
BA_ "GenMsgCycleTime" BO_ 238 20;
BA_ "VFrameFormat" BO_ 238 14;
BA_ "GenMsgCycleTime" BO_ 242 50;
BA_ "VFrameFormat" BO_ 242 14;
BA_ "E2EP01DataId" BO_ 276 114;
BA_ "E2EP01DataLength" BO_ 276 64;
BA_ "GenMsgCycleTime" BO_ 276 20;
BA_ "VFrameFormat" BO_ 276 14;
BA_ "E2EP01DataId" BO_ 336 41;
BA_ "E2EP01DataLength" BO_ 336 64;
BA_ "GenMsgCycleTime" BO_ 336 10;
BA_ "VFrameFormat" BO_ 336 14;
BA_ "E2EP01DataId" BO_ 337 52;
BA_ "E2EP01DataLength" BO_ 337 64;
BA_ "GenMsgCycleTime" BO_ 337 10;
BA_ "VFrameFormat" BO_ 337 14;
BA_ "E2EP01DataId" BO_ 345 151;
BA_ "E2EP01DataLength" BO_ 345 64;
BA_ "GenMsgCycleTime" BO_ 345 100;
BA_ "VFrameFormat" BO_ 345 14;
BA_ "E2EP01DataId" BO_ 393 39;
BA_ "E2EP01DataLength" BO_ 393 64;
BA_ "GenMsgCycleTime" BO_ 393 20;
BA_ "VFrameFormat" BO_ 393 14;
BA_ "GenMsgCycleTime" BO_ 416 100;
BA_ "VFrameFormat" BO_ 416 14;
BA_ "GenMsgCycleTime" BO_ 425 100;
BA_ "VFrameFormat" BO_ 425 14;
BA_ "E2EP01DataId" BO_ 438 25;
BA_ "E2EP01DataLength" BO_ 438 64;
BA_ "GenMsgCycleTime" BO_ 438 10;
BA_ "VFrameFormat" BO_ 438 14;
BA_ "E2EP01DataId" BO_ 532 18;
BA_ "E2EP01DataLength" BO_ 532 64;
BA_ "GenMsgCycleTime" BO_ 532 10;
BA_ "SCL_CryptographicMessageID" BO_ 532 532;
BA_ "SCP_AuthInfoTxLength" BO_ 532 24;
BA_ "SCP_DataId" BO_ 532 532;
BA_ "SCP_FreshnessValueId" BO_ 532 532;
BA_ "SCP_FreshnessValueLength" BO_ 532 64;
BA_ "SCP_FreshnessValueTxLength" BO_ 532 8;
BA_ "SC_LinkPos" BO_ 532 64;
BA_ "SC_Message" BO_ 532 1;
BA_ "VFrameFormat" BO_ 532 14;
BA_ "E2EP01DataId" BO_ 533 19;
BA_ "E2EP01DataLength" BO_ 533 64;
BA_ "GenMsgCycleTime" BO_ 533 20;
BA_ "VFrameFormat" BO_ 533 14;
BA_ "E2EP01DataId" BO_ 549 42;
BA_ "E2EP01DataLength" BO_ 549 64;
BA_ "GenMsgCycleTime" BO_ 549 20;
BA_ "VFrameFormat" BO_ 549 14;
BA_ "GenSigSendType" SG_ 32 Syn_TripCntrVal_Byte0_All 2;
BA_ "sigConfig" SG_ 32 Syn_TripCntrVal_Byte0_All "null";
BA_ "sigExplanation" SG_ 32 Syn_TripCntrVal_Byte0_All "null";
BA_ "sigSecLevel" SG_ 32 Syn_TripCntrVal_Byte0_All "null";
BA_ "GenSigSendType" SG_ 32 Syn_TripCntrVal_Byte1_All 2;
BA_ "sigConfig" SG_ 32 Syn_TripCntrVal_Byte1_All "null";
BA_ "sigExplanation" SG_ 32 Syn_TripCntrVal_Byte1_All "null";
BA_ "sigSecLevel" SG_ 32 Syn_TripCntrVal_Byte1_All "null";
BA_ "GenSigSendType" SG_ 32 Syn_RstCntrVal_Byte0_All 2;
BA_ "sigConfig" SG_ 32 Syn_RstCntrVal_Byte0_All "null";
BA_ "sigExplanation" SG_ 32 Syn_RstCntrVal_Byte0_All "null";
BA_ "sigSecLevel" SG_ 32 Syn_RstCntrVal_Byte0_All "null";
BA_ "GenSigSendType" SG_ 32 Syn_RstCntrVal_Byte1_All 2;
BA_ "sigConfig" SG_ 32 Syn_RstCntrVal_Byte1_All "null";
BA_ "sigExplanation" SG_ 32 Syn_RstCntrVal_Byte1_All "null";
BA_ "sigSecLevel" SG_ 32 Syn_RstCntrVal_Byte1_All "null";
BA_ "GenSigSendType" SG_ 32 Syn_RstCntrVal_Byte2_All 2;
BA_ "sigConfig" SG_ 32 Syn_RstCntrVal_Byte2_All "null";
BA_ "sigExplanation" SG_ 32 Syn_RstCntrVal_Byte2_All "null";
BA_ "sigSecLevel" SG_ 32 Syn_RstCntrVal_Byte2_All "null";
BA_ "GenSigSendType" SG_ 32 Syn_MACInfo_Byte0_All 2;
BA_ "sigConfig" SG_ 32 Syn_MACInfo_Byte0_All "null";
BA_ "sigExplanation" SG_ 32 Syn_MACInfo_Byte0_All "null";
BA_ "sigSecLevel" SG_ 32 Syn_MACInfo_Byte0_All "null";
BA_ "GenSigSendType" SG_ 32 Syn_MACInfo_Byte1_All 2;
BA_ "sigConfig" SG_ 32 Syn_MACInfo_Byte1_All "null";
BA_ "sigExplanation" SG_ 32 Syn_MACInfo_Byte1_All "null";
BA_ "sigSecLevel" SG_ 32 Syn_MACInfo_Byte1_All "null";
BA_ "GenSigSendType" SG_ 32 Syn_MACInfo_Byte2_All 2;
BA_ "sigConfig" SG_ 32 Syn_MACInfo_Byte2_All "null";
BA_ "sigExplanation" SG_ 32 Syn_MACInfo_Byte2_All "null";
BA_ "sigSecLevel" SG_ 32 Syn_MACInfo_Byte2_All "null";
BA_ "GenSigSendType" SG_ 54 TBOX_RemSeekCarCtrlCmd 2;
BA_ "sigConfig" SG_ 54 TBOX_RemSeekCarCtrlCmd "null";
BA_ "sigExplanation" SG_ 54 TBOX_RemSeekCarCtrlCmd "null";
BA_ "sigSecLevel" SG_ 54 TBOX_RemSeekCarCtrlCmd "null";
BA_ "GenSigSendType" SG_ 54 TBOX_RemClsTrCmd 3;
BA_ "sigConfig" SG_ 54 TBOX_RemClsTrCmd "null";
BA_ "sigExplanation" SG_ 54 TBOX_RemClsTrCmd "null";
BA_ "sigSecLevel" SG_ 54 TBOX_RemClsTrCmd "null";
BA_ "GenSigSendType" SG_ 54 TBOX_RemDrvrSeatVentnCmd 3;
BA_ "sigConfig" SG_ 54 TBOX_RemDrvrSeatVentnCmd "null";
BA_ "sigExplanation" SG_ 54 TBOX_RemDrvrSeatVentnCmd "null";
BA_ "sigSecLevel" SG_ 54 TBOX_RemDrvrSeatVentnCmd "null";
BA_ "GenSigSendType" SG_ 54 TBOX_RemDrvrSeatHeatgCmd 3;
BA_ "sigConfig" SG_ 54 TBOX_RemDrvrSeatHeatgCmd "null";
BA_ "sigExplanation" SG_ 54 TBOX_RemDrvrSeatHeatgCmd "null";
BA_ "sigSecLevel" SG_ 54 TBOX_RemDrvrSeatHeatgCmd "null";
BA_ "GenSigSendType" SG_ 54 TBOX_RemSetWelFct 2;
BA_ "sigConfig" SG_ 54 TBOX_RemSetWelFct "null";
BA_ "sigExplanation" SG_ 54 TBOX_RemSetWelFct "null";
BA_ "sigSecLevel" SG_ 54 TBOX_RemSetWelFct "null";
BA_ "GenSigSendType" SG_ 54 TBOX_RemPassSeatVentnCmd 2;
BA_ "sigConfig" SG_ 54 TBOX_RemPassSeatVentnCmd "null";
BA_ "sigExplanation" SG_ 54 TBOX_RemPassSeatVentnCmd "null";
BA_ "sigSecLevel" SG_ 54 TBOX_RemPassSeatVentnCmd "null";
BA_ "GenSigSendType" SG_ 54 TBOX_RemPassSeatHeatgCmd 2;
BA_ "sigConfig" SG_ 54 TBOX_RemPassSeatHeatgCmd "null";
BA_ "sigExplanation" SG_ 54 TBOX_RemPassSeatHeatgCmd "null";
BA_ "sigSecLevel" SG_ 54 TBOX_RemPassSeatHeatgCmd "null";
BA_ "GenSigSendType" SG_ 54 TBOX_ClsAVMFct_ICC 2;
BA_ "sigConfig" SG_ 54 TBOX_ClsAVMFct_ICC "null";
BA_ "sigExplanation" SG_ 54 TBOX_ClsAVMFct_ICC "null";
BA_ "sigSecLevel" SG_ 54 TBOX_ClsAVMFct_ICC "null";
BA_ "GenSigSendType" SG_ 54 TBOX_ClsRemAVMFct_AVAP 2;
BA_ "sigConfig" SG_ 54 TBOX_ClsRemAVMFct_AVAP "null";
BA_ "sigExplanation" SG_ 54 TBOX_ClsRemAVMFct_AVAP "null";
BA_ "sigSecLevel" SG_ 54 TBOX_ClsRemAVMFct_AVAP "null";
BA_ "GenSigSendType" SG_ 54 TBOX_RemSetFolwMeFct_BCM 2;
BA_ "sigConfig" SG_ 54 TBOX_RemSetFolwMeFct_BCM "null";
BA_ "sigExplanation" SG_ 54 TBOX_RemSetFolwMeFct_BCM "null";
BA_ "sigSecLevel" SG_ 54 TBOX_RemSetFolwMeFct_BCM "null";
BA_ "GenSigSendType" SG_ 54 TBOX_RemSetCtrlLockFct_PKC 2;
BA_ "sigConfig" SG_ 54 TBOX_RemSetCtrlLockFct_PKC "null";
BA_ "sigExplanation" SG_ 54 TBOX_RemSetCtrlLockFct_PKC "null";
BA_ "sigSecLevel" SG_ 54 TBOX_RemSetCtrlLockFct_PKC "null";
BA_ "GenSigSendType" SG_ 54 TBOX_RemSetKickSnsrFct 2;
BA_ "sigConfig" SG_ 54 TBOX_RemSetKickSnsrFct "null";
BA_ "sigExplanation" SG_ 54 TBOX_RemSetKickSnsrFct "null";
BA_ "sigSecLevel" SG_ 54 TBOX_RemSetKickSnsrFct "null";
BA_ "GenSigSendType" SG_ 54 TBOX_VideoCtrlReq 2;
BA_ "sigConfig" SG_ 54 TBOX_VideoCtrlReq "null";
BA_ "sigExplanation" SG_ 54 TBOX_VideoCtrlReq "null";
BA_ "sigSecLevel" SG_ 54 TBOX_VideoCtrlReq "null";
BA_ "GenSigSendType" SG_ 54 TBOX_VoiceBlowerLimReq 2;
BA_ "sigConfig" SG_ 54 TBOX_VoiceBlowerLimReq "null";
BA_ "sigExplanation" SG_ 54 TBOX_VoiceBlowerLimReq "null";
BA_ "sigSecLevel" SG_ 54 TBOX_VoiceBlowerLimReq "null";
BA_ "GenSigSendType" SG_ 54 TBOX_RemCtrlCmdFb 3;
BA_ "sigConfig" SG_ 54 TBOX_RemCtrlCmdFb "null";
BA_ "sigExplanation" SG_ 54 TBOX_RemCtrlCmdFb "null";
BA_ "sigSecLevel" SG_ 54 TBOX_RemCtrlCmdFb "null";
BA_ "GenSigSendType" SG_ 54 TBOX_CtrlReMirrReq 2;
BA_ "sigConfig" SG_ 54 TBOX_CtrlReMirrReq "null";
BA_ "sigExplanation" SG_ 54 TBOX_CtrlReMirrReq "null";
BA_ "sigSecLevel" SG_ 54 TBOX_CtrlReMirrReq "null";
BA_ "GenSigSendType" SG_ 54 TBOX_eCallMuteSt 2;
BA_ "sigConfig" SG_ 54 TBOX_eCallMuteSt "null";
BA_ "sigExplanation" SG_ 54 TBOX_eCallMuteSt "null";
BA_ "sigSecLevel" SG_ 54 TBOX_eCallMuteSt "null";
BA_ "GenSigSendType" SG_ 54 TBOX_RemReScrnHeatgCmd 2;
BA_ "GenSigSendType" SG_ 54 TBOX_eCallSt 2;
BA_ "sigConfig" SG_ 54 TBOX_eCallSt "null";
BA_ "sigExplanation" SG_ 54 TBOX_eCallSt "null";
BA_ "sigSecLevel" SG_ 54 TBOX_eCallSt "null";
BA_ "GenSigSendType" SG_ 88 TBOX_RemClsWin_RW_CtrlCmd 2;
BA_ "GenSigSendType" SG_ 88 TBOX_RemClsSunroofCtrlCmd 3;
BA_ "sigConfig" SG_ 88 TBOX_RemClsSunroofCtrlCmd "null";
BA_ "sigExplanation" SG_ 88 TBOX_RemClsSunroofCtrlCmd "null";
BA_ "sigSecLevel" SG_ 88 TBOX_RemClsSunroofCtrlCmd "null";
BA_ "sigConfig" SG_ 88 TBOX_58_SSecOC_Fresh_Byte0 "null";
BA_ "sigExplanation" SG_ 88 TBOX_58_SSecOC_Fresh_Byte0 "null";
BA_ "sigSecLevel" SG_ 88 TBOX_58_SSecOC_Fresh_Byte0 "null";
BA_ "sigConfig" SG_ 88 TBOX_58_SSecOC_MAC_Byte0 "null";
BA_ "sigExplanation" SG_ 88 TBOX_58_SSecOC_MAC_Byte0 "null";
BA_ "sigSecLevel" SG_ 88 TBOX_58_SSecOC_MAC_Byte0 "null";
BA_ "sigConfig" SG_ 88 TBOX_58_SSecOC_MAC_Byte1 "null";
BA_ "sigExplanation" SG_ 88 TBOX_58_SSecOC_MAC_Byte1 "null";
BA_ "sigSecLevel" SG_ 88 TBOX_58_SSecOC_MAC_Byte1 "null";
BA_ "sigConfig" SG_ 88 TBOX_58_SSecOC_MAC_Byte2 "null";
BA_ "sigExplanation" SG_ 88 TBOX_58_SSecOC_MAC_Byte2 "null";
BA_ "sigSecLevel" SG_ 88 TBOX_58_SSecOC_MAC_Byte2 "null";
BA_ "sigConfig" SG_ 89 ACU_59_CheckSum "null";
BA_ "sigExplanation" SG_ 89 ACU_59_CheckSum "null";
BA_ "sigSecLevel" SG_ 89 ACU_59_CheckSum "null";
BA_ "sigConfig" SG_ 89 ACU_59_AliveCounter "null";
BA_ "sigExplanation" SG_ 89 ACU_59_AliveCounter "null";
BA_ "sigSecLevel" SG_ 89 ACU_59_AliveCounter "null";
BA_ "GenSigSendType" SG_ 89 ACU_FrntCrashOutpSts 4;
BA_ "sigConfig" SG_ 89 ACU_FrntCrashOutpSts "null";
BA_ "sigExplanation" SG_ 89 ACU_FrntCrashOutpSts "null";
BA_ "sigSecLevel" SG_ 89 ACU_FrntCrashOutpSts "A(D)";
BA_ "GenSigSendType" SG_ 89 ACU_RiSideCrashOutpSts 4;
BA_ "sigConfig" SG_ 89 ACU_RiSideCrashOutpSts "null";
BA_ "sigExplanation" SG_ 89 ACU_RiSideCrashOutpSts "null";
BA_ "sigSecLevel" SG_ 89 ACU_RiSideCrashOutpSts "A(D)";
BA_ "GenSigSendType" SG_ 89 ACU_LeSideCrashOutpSts 4;
BA_ "sigConfig" SG_ 89 ACU_LeSideCrashOutpSts "null";
BA_ "sigExplanation" SG_ 89 ACU_LeSideCrashOutpSts "null";
BA_ "sigSecLevel" SG_ 89 ACU_LeSideCrashOutpSts "A(D)";
BA_ "GenSigSendType" SG_ 89 ACU_RearCrashOutpSts 4;
BA_ "sigConfig" SG_ 89 ACU_RearCrashOutpSts "null";
BA_ "sigExplanation" SG_ 89 ACU_RearCrashOutpSts "null";
BA_ "sigSecLevel" SG_ 89 ACU_RearCrashOutpSts "A(D)";
BA_ "GenSigSendType" SG_ 89 ACU_RollovrCrashOutpSts 4;
BA_ "sigConfig" SG_ 89 ACU_RollovrCrashOutpSts "null";
BA_ "sigExplanation" SG_ 89 ACU_RollovrCrashOutpSts "null";
BA_ "sigSecLevel" SG_ 89 ACU_RollovrCrashOutpSts "A(D)";
BA_ "GenSigSendType" SG_ 89 ACU_Crash_cfm 4;
BA_ "sigConfig" SG_ 89 ACU_Crash_cfm "null";
BA_ "sigExplanation" SG_ 89 ACU_Crash_cfm "null";
BA_ "sigSecLevel" SG_ 89 ACU_Crash_cfm "A(D)";
BA_ "GenSigSendType" SG_ 117 VCU_SUB_ID_75 2;
BA_ "sigConfig" SG_ 117 VCU_SUB_ID_75 "null";
BA_ "sigExplanation" SG_ 117 VCU_SUB_ID_75 "null";
BA_ "sigSecLevel" SG_ 117 VCU_SUB_ID_75 "null";
BA_ "GenSigSendType" SG_ 117 VCU_LrngSts 2;
BA_ "sigConfig" SG_ 117 VCU_LrngSts "null";
BA_ "sigExplanation" SG_ 117 VCU_LrngSts "null";
BA_ "sigSecLevel" SG_ 117 VCU_LrngSts "null";
BA_ "GenSigSendType" SG_ 119 VCU_SUB_ID_77 2;
BA_ "sigConfig" SG_ 119 VCU_SUB_ID_77 "null";
BA_ "sigExplanation" SG_ 119 VCU_SUB_ID_77 "null";
BA_ "sigSecLevel" SG_ 119 VCU_SUB_ID_77 "null";
BA_ "GenSigSendType" SG_ 119 VCU_LrngData0 2;
BA_ "sigConfig" SG_ 119 VCU_LrngData0 "null";
BA_ "sigExplanation" SG_ 119 VCU_LrngData0 "null";
BA_ "sigSecLevel" SG_ 119 VCU_LrngData0 "null";
BA_ "GenSigSendType" SG_ 119 VCU_LrngData1 2;
BA_ "sigConfig" SG_ 119 VCU_LrngData1 "null";
BA_ "sigExplanation" SG_ 119 VCU_LrngData1 "null";
BA_ "sigSecLevel" SG_ 119 VCU_LrngData1 "null";
BA_ "GenSigSendType" SG_ 119 VCU_LrngData2 2;
BA_ "sigConfig" SG_ 119 VCU_LrngData2 "null";
BA_ "sigExplanation" SG_ 119 VCU_LrngData2 "null";
BA_ "sigSecLevel" SG_ 119 VCU_LrngData2 "null";
BA_ "GenSigSendType" SG_ 119 VCU_LrngData3 2;
BA_ "sigConfig" SG_ 119 VCU_LrngData3 "null";
BA_ "sigExplanation" SG_ 119 VCU_LrngData3 "null";
BA_ "sigSecLevel" SG_ 119 VCU_LrngData3 "null";
BA_ "GenSigSendType" SG_ 119 VCU_LrngData4 2;
BA_ "sigConfig" SG_ 119 VCU_LrngData4 "null";
BA_ "sigExplanation" SG_ 119 VCU_LrngData4 "null";
BA_ "sigSecLevel" SG_ 119 VCU_LrngData4 "null";
BA_ "GenSigSendType" SG_ 119 VCU_LrngData5 2;
BA_ "sigConfig" SG_ 119 VCU_LrngData5 "null";
BA_ "sigExplanation" SG_ 119 VCU_LrngData5 "null";
BA_ "sigSecLevel" SG_ 119 VCU_LrngData5 "null";
BA_ "GenSigSendType" SG_ 119 VCU_LrngData6 2;
BA_ "sigConfig" SG_ 119 VCU_LrngData6 "null";
BA_ "sigExplanation" SG_ 119 VCU_LrngData6 "null";
BA_ "sigSecLevel" SG_ 119 VCU_LrngData6 "null";
BA_ "GenSigSendType" SG_ 121 TBOX_LrnFbInfoClassn 2;
BA_ "sigConfig" SG_ 121 TBOX_LrnFbInfoClassn "null";
BA_ "sigExplanation" SG_ 121 TBOX_LrnFbInfoClassn "null";
BA_ "sigSecLevel" SG_ 121 TBOX_LrnFbInfoClassn "null";
BA_ "GenSigSendType" SG_ 121 TBOX_LrngSts 2;
BA_ "sigConfig" SG_ 121 TBOX_LrngSts "null";
BA_ "sigExplanation" SG_ 121 TBOX_LrngSts "null";
BA_ "sigSecLevel" SG_ 121 TBOX_LrngSts "null";
BA_ "GenSigSendType" SG_ 122 TBOX_LrngSubID_7A 2;
BA_ "sigConfig" SG_ 122 TBOX_LrngSubID_7A "null";
BA_ "sigExplanation" SG_ 122 TBOX_LrngSubID_7A "null";
BA_ "sigSecLevel" SG_ 122 TBOX_LrngSubID_7A "null";
BA_ "GenSigSendType" SG_ 122 TBOX_LrngData1 2;
BA_ "sigConfig" SG_ 122 TBOX_LrngData1 "null";
BA_ "sigExplanation" SG_ 122 TBOX_LrngData1 "null";
BA_ "sigSecLevel" SG_ 122 TBOX_LrngData1 "null";
BA_ "GenSigSendType" SG_ 122 TBOX_LrngData2 2;
BA_ "sigConfig" SG_ 122 TBOX_LrngData2 "null";
BA_ "sigExplanation" SG_ 122 TBOX_LrngData2 "null";
BA_ "sigSecLevel" SG_ 122 TBOX_LrngData2 "null";
BA_ "GenSigSendType" SG_ 122 TBOX_LrngData3 2;
BA_ "sigConfig" SG_ 122 TBOX_LrngData3 "null";
BA_ "sigExplanation" SG_ 122 TBOX_LrngData3 "null";
BA_ "sigSecLevel" SG_ 122 TBOX_LrngData3 "null";
BA_ "GenSigSendType" SG_ 122 TBOX_LrngData4 2;
BA_ "sigConfig" SG_ 122 TBOX_LrngData4 "null";
BA_ "sigExplanation" SG_ 122 TBOX_LrngData4 "null";
BA_ "sigSecLevel" SG_ 122 TBOX_LrngData4 "null";
BA_ "GenSigSendType" SG_ 122 TBOX_LrngData5 2;
BA_ "sigConfig" SG_ 122 TBOX_LrngData5 "null";
BA_ "sigExplanation" SG_ 122 TBOX_LrngData5 "null";
BA_ "sigSecLevel" SG_ 122 TBOX_LrngData5 "null";
BA_ "GenSigSendType" SG_ 122 TBOX_LrngData6 2;
BA_ "sigConfig" SG_ 122 TBOX_LrngData6 "null";
BA_ "sigExplanation" SG_ 122 TBOX_LrngData6 "null";
BA_ "sigSecLevel" SG_ 122 TBOX_LrngData6 "null";
BA_ "GenSigSendType" SG_ 122 TBOX_LrngData7 2;
BA_ "sigConfig" SG_ 122 TBOX_LrngData7 "null";
BA_ "sigExplanation" SG_ 122 TBOX_LrngData7 "null";
BA_ "sigSecLevel" SG_ 122 TBOX_LrngData7 "null";
BA_ "sigConfig" SG_ 147 VCU_93_CheckSum "null";
BA_ "sigExplanation" SG_ 147 VCU_93_CheckSum "null";
BA_ "sigSecLevel" SG_ 147 VCU_93_CheckSum "null";
BA_ "sigConfig" SG_ 147 VCU_93_AliveCounter "null";
BA_ "sigExplanation" SG_ 147 VCU_93_AliveCounter "null";
BA_ "sigSecLevel" SG_ 147 VCU_93_AliveCounter "null";
BA_ "sigConfig" SG_ 147 VCU_EmgyShutOff "null";
BA_ "sigExplanation" SG_ 147 VCU_EmgyShutOff "null";
BA_ "sigSecLevel" SG_ 147 VCU_EmgyShutOff "null";
BA_ "sigConfig" SG_ 147 VCU_IsolationMonitor_Rq "null";
BA_ "sigExplanation" SG_ 147 VCU_IsolationMonitor_Rq "null";
BA_ "sigSecLevel" SG_ 147 VCU_IsolationMonitor_Rq "null";
BA_ "sigConfig" SG_ 147 VCU_Set_Chrg_Mod "null";
BA_ "sigExplanation" SG_ 147 VCU_Set_Chrg_Mod "null";
BA_ "sigSecLevel" SG_ 147 VCU_Set_Chrg_Mod "null";
BA_ "sigConfig" SG_ 147 VCU_Set_BMS_Mod "null";
BA_ "sigExplanation" SG_ 147 VCU_Set_BMS_Mod "null";
BA_ "sigSecLevel" SG_ 147 VCU_Set_BMS_Mod "null";
BA_ "sigConfig" SG_ 147 VCU_HVBActivateDeactivateRq "null";
BA_ "sigExplanation" SG_ 147 VCU_HVBActivateDeactivateRq "null";
BA_ "sigSecLevel" SG_ 147 VCU_HVBActivateDeactivateRq "null";
BA_ "sigConfig" SG_ 147 VCU_Set_Balc_Mod "null";
BA_ "sigExplanation" SG_ 147 VCU_Set_Balc_Mod "null";
BA_ "sigSecLevel" SG_ 147 VCU_Set_Balc_Mod "null";
BA_ "sigConfig" SG_ 147 VCU_93_SSecOC_Fresh_Byte0 "null";
BA_ "sigExplanation" SG_ 147 VCU_93_SSecOC_Fresh_Byte0 "null";
BA_ "sigSecLevel" SG_ 147 VCU_93_SSecOC_Fresh_Byte0 "null";
BA_ "sigConfig" SG_ 147 VCU_93_SSecOC_MAC_Byte0 "null";
BA_ "sigExplanation" SG_ 147 VCU_93_SSecOC_MAC_Byte0 "null";
BA_ "sigSecLevel" SG_ 147 VCU_93_SSecOC_MAC_Byte0 "null";
BA_ "sigConfig" SG_ 147 VCU_93_SSecOC_MAC_Byte1 "null";
BA_ "sigExplanation" SG_ 147 VCU_93_SSecOC_MAC_Byte1 "null";
BA_ "sigSecLevel" SG_ 147 VCU_93_SSecOC_MAC_Byte1 "null";
BA_ "sigConfig" SG_ 147 VCU_93_SSecOC_MAC_Byte2 "null";
BA_ "sigExplanation" SG_ 147 VCU_93_SSecOC_MAC_Byte2 "null";
BA_ "sigSecLevel" SG_ 147 VCU_93_SSecOC_MAC_Byte2 "null";
BA_ "sigConfig" SG_ 233 BMS_Bat_HVmeasure_CheckSum "null";
BA_ "sigExplanation" SG_ 233 BMS_Bat_HVmeasure_CheckSum "null";
BA_ "sigSecLevel" SG_ 233 BMS_Bat_HVmeasure_CheckSum "null";
BA_ "sigConfig" SG_ 233 BMS_Bat_HVmeasure_AliveCounter "null";
BA_ "sigExplanation" SG_ 233 BMS_Bat_HVmeasure_AliveCounter "null";
BA_ "sigSecLevel" SG_ 233 BMS_Bat_HVmeasure_AliveCounter "null";
BA_ "sigConfig" SG_ 233 BMS_Bat_HVmeasure_Current "null";
BA_ "sigExplanation" SG_ 233 BMS_Bat_HVmeasure_Current "null";
BA_ "sigSecLevel" SG_ 233 BMS_Bat_HVmeasure_Current "A(B)";
BA_ "sigConfig" SG_ 233 BMS_Bat_Hvmeasure_V_Pack "null";
BA_ "sigExplanation" SG_ 233 BMS_Bat_Hvmeasure_V_Pack "null";
BA_ "sigSecLevel" SG_ 233 BMS_Bat_Hvmeasure_V_Pack "null";
BA_ "sigConfig" SG_ 235 BMS_Critical_Error_Flg_CheckSum "null";
BA_ "sigExplanation" SG_ 235 BMS_Critical_Error_Flg_CheckSum "null";
BA_ "sigSecLevel" SG_ 235 BMS_Critical_Error_Flg_CheckSum "null";
BA_ "sigConfig" SG_ 235 BMS_Critical_Error_Flg_AliveCoun "null";
BA_ "sigExplanation" SG_ 235 BMS_Critical_Error_Flg_AliveCoun "null";
BA_ "sigSecLevel" SG_ 235 BMS_Critical_Error_Flg_AliveCoun "null";
BA_ "SystemSignalLongSymbol" SG_ 235 BMS_Critical_Error_Flg_AliveCoun "BMS_Critical_Error_Flg_AliveCounter";
BA_ "sigConfig" SG_ 235 BMS_ErrorWarning_OverChargeCurre "null";
BA_ "sigExplanation" SG_ 235 BMS_ErrorWarning_OverChargeCurre "null";
BA_ "sigSecLevel" SG_ 235 BMS_ErrorWarning_OverChargeCurre "null";
BA_ "SystemSignalLongSymbol" SG_ 235 BMS_ErrorWarning_OverChargeCurre "BMS_ErrorWarning_OverChargeCurrent";
BA_ "sigConfig" SG_ 235 BMS_ErrorActive_OverChargeCurren "null";
BA_ "sigExplanation" SG_ 235 BMS_ErrorActive_OverChargeCurren "null";
BA_ "sigSecLevel" SG_ 235 BMS_ErrorActive_OverChargeCurren "null";
BA_ "SystemSignalLongSymbol" SG_ 235 BMS_ErrorActive_OverChargeCurren "BMS_ErrorActive_OverChargeCurrent";
BA_ "sigConfig" SG_ 235 BMS_ErrorWarning_OverDischargeCu "null";
BA_ "sigExplanation" SG_ 235 BMS_ErrorWarning_OverDischargeCu "null";
BA_ "sigSecLevel" SG_ 235 BMS_ErrorWarning_OverDischargeCu "null";
BA_ "SystemSignalLongSymbol" SG_ 235 BMS_ErrorWarning_OverDischargeCu "BMS_ErrorWarning_OverDischargeCurrent";
BA_ "sigConfig" SG_ 235 BMS_ErrorActive_OverDischargeCur "null";
BA_ "sigExplanation" SG_ 235 BMS_ErrorActive_OverDischargeCur "null";
BA_ "sigSecLevel" SG_ 235 BMS_ErrorActive_OverDischargeCur "null";
BA_ "SystemSignalLongSymbol" SG_ 235 BMS_ErrorActive_OverDischargeCur "BMS_ErrorActive_OverDischargeCurrent";
BA_ "sigConfig" SG_ 235 BMS_ErrorWarning_ChargePowerLimi "null";
BA_ "sigExplanation" SG_ 235 BMS_ErrorWarning_ChargePowerLimi "null";
BA_ "sigSecLevel" SG_ 235 BMS_ErrorWarning_ChargePowerLimi "null";
BA_ "SystemSignalLongSymbol" SG_ 235 BMS_ErrorWarning_ChargePowerLimi "BMS_ErrorWarning_ChargePowerLimitHit";
BA_ "sigConfig" SG_ 235 BMS_ErrorActive_ChargePowerLimit "null";
BA_ "sigExplanation" SG_ 235 BMS_ErrorActive_ChargePowerLimit "null";
BA_ "sigSecLevel" SG_ 235 BMS_ErrorActive_ChargePowerLimit "null";
BA_ "SystemSignalLongSymbol" SG_ 235 BMS_ErrorActive_ChargePowerLimit "BMS_ErrorActive_ChargePowerLimitHit";
BA_ "sigConfig" SG_ 235 BMS_ErrorWarning_DischargePowerL "null";
BA_ "sigExplanation" SG_ 235 BMS_ErrorWarning_DischargePowerL "null";
BA_ "sigSecLevel" SG_ 235 BMS_ErrorWarning_DischargePowerL "null";
BA_ "SystemSignalLongSymbol" SG_ 235 BMS_ErrorWarning_DischargePowerL "BMS_ErrorWarning_DischargePowerLimitHit";
BA_ "sigConfig" SG_ 235 BMS_ErrorActive_DischargePowerLi "null";
BA_ "sigExplanation" SG_ 235 BMS_ErrorActive_DischargePowerLi "null";
BA_ "sigSecLevel" SG_ 235 BMS_ErrorActive_DischargePowerLi "null";
BA_ "SystemSignalLongSymbol" SG_ 235 BMS_ErrorActive_DischargePowerLi "BMS_ErrorActive_DischargePowerLimitHit";
BA_ "sigConfig" SG_ 235 BMS_ErrorWarning_SOC_Low "null";
BA_ "sigExplanation" SG_ 235 BMS_ErrorWarning_SOC_Low "null";
BA_ "sigSecLevel" SG_ 235 BMS_ErrorWarning_SOC_Low "null";
BA_ "sigConfig" SG_ 235 BMS_ErrorActive_SOC_Low "null";
BA_ "sigExplanation" SG_ 235 BMS_ErrorActive_SOC_Low "null";
BA_ "sigSecLevel" SG_ 235 BMS_ErrorActive_SOC_Low "null";
BA_ "sigConfig" SG_ 235 BMS_ErrorWarning_Iso "null";
BA_ "sigExplanation" SG_ 235 BMS_ErrorWarning_Iso "null";
BA_ "sigSecLevel" SG_ 235 BMS_ErrorWarning_Iso "null";
BA_ "sigConfig" SG_ 235 BMS_ErrorActive_Iso_Crit "null";
BA_ "sigExplanation" SG_ 235 BMS_ErrorActive_Iso_Crit "null";
BA_ "sigSecLevel" SG_ 235 BMS_ErrorActive_Iso_Crit "null";
BA_ "sigConfig" SG_ 235 BMS_ErrorActive_AbsChargeCurrent "null";
BA_ "sigExplanation" SG_ 235 BMS_ErrorActive_AbsChargeCurrent "null";
BA_ "sigSecLevel" SG_ 235 BMS_ErrorActive_AbsChargeCurrent "null";
BA_ "SystemSignalLongSymbol" SG_ 235 BMS_ErrorActive_AbsChargeCurrent "BMS_ErrorActive_AbsChargeCurrentLim";
BA_ "sigConfig" SG_ 235 BMS_ErrorActive_AbsDischargeCurr "null";
BA_ "sigExplanation" SG_ 235 BMS_ErrorActive_AbsDischargeCurr "null";
BA_ "sigSecLevel" SG_ 235 BMS_ErrorActive_AbsDischargeCurr "null";
BA_ "SystemSignalLongSymbol" SG_ 235 BMS_ErrorActive_AbsDischargeCurr "BMS_ErrorActive_AbsDischargeCurrentLimitH";
BA_ "sigConfig" SG_ 235 BMS_ErrorActive_AbsChargePowerLi "null";
BA_ "sigExplanation" SG_ 235 BMS_ErrorActive_AbsChargePowerLi "null";
BA_ "sigSecLevel" SG_ 235 BMS_ErrorActive_AbsChargePowerLi "null";
BA_ "SystemSignalLongSymbol" SG_ 235 BMS_ErrorActive_AbsChargePowerLi "BMS_ErrorActive_AbsChargePowerLim";
BA_ "sigConfig" SG_ 235 BMS_ErrorActive_AbsDischargePowe "null";
BA_ "sigExplanation" SG_ 235 BMS_ErrorActive_AbsDischargePowe "null";
BA_ "sigSecLevel" SG_ 235 BMS_ErrorActive_AbsDischargePowe "null";
BA_ "SystemSignalLongSymbol" SG_ 235 BMS_ErrorActive_AbsDischargePowe "BMS_ErrorActive_AbsDischargePowerLimHit";
BA_ "sigConfig" SG_ 235 BMS_ErrorWarning_overcurrent_Pre "null";
BA_ "sigExplanation" SG_ 235 BMS_ErrorWarning_overcurrent_Pre "null";
BA_ "sigSecLevel" SG_ 235 BMS_ErrorWarning_overcurrent_Pre "null";
BA_ "SystemSignalLongSymbol" SG_ 235 BMS_ErrorWarning_overcurrent_Pre "BMS_ErrorWarning_overcurrent_Prewarn";
BA_ "sigConfig" SG_ 235 BMS_ErrorActive_ServState "null";
BA_ "sigExplanation" SG_ 235 BMS_ErrorActive_ServState "null";
BA_ "sigSecLevel" SG_ 235 BMS_ErrorActive_ServState "null";
BA_ "sigConfig" SG_ 235 BMS_SystemError_KL30C "null";
BA_ "sigExplanation" SG_ 235 BMS_SystemError_KL30C "null";
BA_ "sigSecLevel" SG_ 235 BMS_SystemError_KL30C "null";
BA_ "sigConfig" SG_ 235 BMS_SystemError_OmmissionOfKL15 "null";
BA_ "sigExplanation" SG_ 235 BMS_SystemError_OmmissionOfKL15 "null";
BA_ "sigSecLevel" SG_ 235 BMS_SystemError_OmmissionOfKL15 "null";
BA_ "sigConfig" SG_ 235 BMS_SystemError_HV_Interlock "null";
BA_ "sigExplanation" SG_ 235 BMS_SystemError_HV_Interlock "null";
BA_ "sigSecLevel" SG_ 235 BMS_SystemError_HV_Interlock "null";
BA_ "sigConfig" SG_ 235 BMS_SystemError_HV_Fuse "null";
BA_ "sigExplanation" SG_ 235 BMS_SystemError_HV_Fuse "null";
BA_ "sigSecLevel" SG_ 235 BMS_SystemError_HV_Fuse "null";
BA_ "sigConfig" SG_ 235 BMS_CommError_CommFailure "null";
BA_ "sigExplanation" SG_ 235 BMS_CommError_CommFailure "null";
BA_ "sigSecLevel" SG_ 235 BMS_CommError_CommFailure "null";
BA_ "sigConfig" SG_ 235 BMS_CommWarning_PEC_High "null";
BA_ "sigExplanation" SG_ 235 BMS_CommWarning_PEC_High "null";
BA_ "sigSecLevel" SG_ 235 BMS_CommWarning_PEC_High "null";
BA_ "sigConfig" SG_ 235 BMS_CommError_PEC_High "null";
BA_ "sigExplanation" SG_ 235 BMS_CommError_PEC_High "null";
BA_ "sigSecLevel" SG_ 235 BMS_CommError_PEC_High "null";
BA_ "sigConfig" SG_ 235 BMS_HVlinkError_VCU_Comm_Failure "null";
BA_ "sigExplanation" SG_ 235 BMS_HVlinkError_VCU_Comm_Failure "null";
BA_ "sigSecLevel" SG_ 235 BMS_HVlinkError_VCU_Comm_Failure "null";
BA_ "sigConfig" SG_ 235 BMS_HVlinkError_Iso_Dev "null";
BA_ "sigExplanation" SG_ 235 BMS_HVlinkError_Iso_Dev "null";
BA_ "sigSecLevel" SG_ 235 BMS_HVlinkError_Iso_Dev "null";
BA_ "sigConfig" SG_ 235 BMS_HVlinkError_Iso_Dig_Sig "null";
BA_ "sigExplanation" SG_ 235 BMS_HVlinkError_Iso_Dig_Sig "null";
BA_ "sigSecLevel" SG_ 235 BMS_HVlinkError_Iso_Dig_Sig "null";
BA_ "sigConfig" SG_ 235 BMS_HVlinkError_ContactorWelded "null";
BA_ "sigExplanation" SG_ 235 BMS_HVlinkError_ContactorWelded "null";
BA_ "sigSecLevel" SG_ 235 BMS_HVlinkError_ContactorWelded "null";
BA_ "sigConfig" SG_ 235 BMS_HVlinkError_HV_Interlock_Bad "null";
BA_ "sigExplanation" SG_ 235 BMS_HVlinkError_HV_Interlock_Bad "null";
BA_ "sigSecLevel" SG_ 235 BMS_HVlinkError_HV_Interlock_Bad "null";
BA_ "SystemSignalLongSymbol" SG_ 235 BMS_HVlinkError_HV_Interlock_Bad "BMS_HVlinkError_HV_Interlock_BadSigIntegr";
BA_ "sigConfig" SG_ 235 BMS_HardwareError_LCM_General_Fa "null";
BA_ "sigExplanation" SG_ 235 BMS_HardwareError_LCM_General_Fa "null";
BA_ "sigSecLevel" SG_ 235 BMS_HardwareError_LCM_General_Fa "null";
BA_ "SystemSignalLongSymbol" SG_ 235 BMS_HardwareError_LCM_General_Fa "BMS_HardwareError_LCM_General_Failr";
BA_ "sigConfig" SG_ 235 BMS_SoftwareError_General_Failr "null";
BA_ "sigExplanation" SG_ 235 BMS_SoftwareError_General_Failr "null";
BA_ "sigSecLevel" SG_ 235 BMS_SoftwareError_General_Failr "null";
BA_ "sigConfig" SG_ 235 BMS_ErrorWarning_CellOverVoltage "null";
BA_ "sigExplanation" SG_ 235 BMS_ErrorWarning_CellOverVoltage "null";
BA_ "sigSecLevel" SG_ 235 BMS_ErrorWarning_CellOverVoltage "null";
BA_ "sigConfig" SG_ 235 BMS_ErrorActive_CellOverVoltage "null";
BA_ "sigExplanation" SG_ 235 BMS_ErrorActive_CellOverVoltage "null";
BA_ "sigSecLevel" SG_ 235 BMS_ErrorActive_CellOverVoltage "null";
BA_ "sigConfig" SG_ 235 BMS_ErrorWarning_CellUnderVoltag "null";
BA_ "sigExplanation" SG_ 235 BMS_ErrorWarning_CellUnderVoltag "null";
BA_ "sigSecLevel" SG_ 235 BMS_ErrorWarning_CellUnderVoltag "null";
BA_ "SystemSignalLongSymbol" SG_ 235 BMS_ErrorWarning_CellUnderVoltag "BMS_ErrorWarning_CellUnderVoltage";
BA_ "sigConfig" SG_ 235 BMS_ErrorActive_CellUnderVoltage "null";
BA_ "sigExplanation" SG_ 235 BMS_ErrorActive_CellUnderVoltage "null";
BA_ "sigSecLevel" SG_ 235 BMS_ErrorActive_CellUnderVoltage "null";
BA_ "sigConfig" SG_ 235 BMS_ErrorWarning_CellTempHigh "null";
BA_ "sigExplanation" SG_ 235 BMS_ErrorWarning_CellTempHigh "null";
BA_ "sigSecLevel" SG_ 235 BMS_ErrorWarning_CellTempHigh "null";
BA_ "sigConfig" SG_ 235 BMS_ErrorActive_CellTempHigh "null";
BA_ "sigExplanation" SG_ 235 BMS_ErrorActive_CellTempHigh "null";
BA_ "sigSecLevel" SG_ 235 BMS_ErrorActive_CellTempHigh "null";
BA_ "sigConfig" SG_ 235 BMS_ErrorWarning_CellTempLow "null";
BA_ "sigExplanation" SG_ 235 BMS_ErrorWarning_CellTempLow "null";
BA_ "sigSecLevel" SG_ 235 BMS_ErrorWarning_CellTempLow "null";
BA_ "sigConfig" SG_ 235 BMS_ErrorActive_CellTempLow "null";
BA_ "sigExplanation" SG_ 235 BMS_ErrorActive_CellTempLow "null";
BA_ "sigSecLevel" SG_ 235 BMS_ErrorActive_CellTempLow "null";
BA_ "sigConfig" SG_ 235 BMS_ErrorWarning_HV_OverVoltage "null";
BA_ "sigExplanation" SG_ 235 BMS_ErrorWarning_HV_OverVoltage "null";
BA_ "sigSecLevel" SG_ 235 BMS_ErrorWarning_HV_OverVoltage "null";
BA_ "sigConfig" SG_ 235 BMS_ErrorActive_HV_OverVoltage "null";
BA_ "sigExplanation" SG_ 235 BMS_ErrorActive_HV_OverVoltage "null";
BA_ "sigSecLevel" SG_ 235 BMS_ErrorActive_HV_OverVoltage "null";
BA_ "sigConfig" SG_ 235 BMS_ErrorWarning_HV_UnderVoltage "null";
BA_ "sigExplanation" SG_ 235 BMS_ErrorWarning_HV_UnderVoltage "null";
BA_ "sigSecLevel" SG_ 235 BMS_ErrorWarning_HV_UnderVoltage "null";
BA_ "sigConfig" SG_ 235 BMS_ErrorActive_HV_UnderVoltage "null";
BA_ "sigExplanation" SG_ 235 BMS_ErrorActive_HV_UnderVoltage "null";
BA_ "sigSecLevel" SG_ 235 BMS_ErrorActive_HV_UnderVoltage "null";
BA_ "sigConfig" SG_ 235 BMS_PVIU_CANcommError "null";
BA_ "sigExplanation" SG_ 235 BMS_PVIU_CANcommError "null";
BA_ "sigSecLevel" SG_ 235 BMS_PVIU_CANcommError "null";
BA_ "sigConfig" SG_ 236 BMS_Curr_PST_CheckSum "null";
BA_ "sigExplanation" SG_ 236 BMS_Curr_PST_CheckSum "null";
BA_ "sigSecLevel" SG_ 236 BMS_Curr_PST_CheckSum "null";
BA_ "sigConfig" SG_ 236 BMS_Curr_PST_AliveCounter "null";
BA_ "sigExplanation" SG_ 236 BMS_Curr_PST_AliveCounter "null";
BA_ "sigSecLevel" SG_ 236 BMS_Curr_PST_AliveCounter "null";
BA_ "sigConfig" SG_ 236 BMS_Bat_D_MAXcurr_PST "null";
BA_ "sigExplanation" SG_ 236 BMS_Bat_D_MAXcurr_PST "null";
BA_ "sigSecLevel" SG_ 236 BMS_Bat_D_MAXcurr_PST "null";
BA_ "sigConfig" SG_ 236 BMS_Bat_C_MAXcurr_PST "null";
BA_ "sigExplanation" SG_ 236 BMS_Bat_C_MAXcurr_PST "null";
BA_ "sigSecLevel" SG_ 236 BMS_Bat_C_MAXcurr_PST "null";
BA_ "sigConfig" SG_ 237 BMS_OverallStatus_CheckSum "null";
BA_ "sigExplanation" SG_ 237 BMS_OverallStatus_CheckSum "null";
BA_ "sigSecLevel" SG_ 237 BMS_OverallStatus_CheckSum "null";
BA_ "sigConfig" SG_ 237 BMS_OverallStatus_AliveCounter "null";
BA_ "sigExplanation" SG_ 237 BMS_OverallStatus_AliveCounter "null";
BA_ "sigSecLevel" SG_ 237 BMS_OverallStatus_AliveCounter "null";
BA_ "sigConfig" SG_ 237 BMS_OperationStates "null";
BA_ "sigExplanation" SG_ 237 BMS_OperationStates "null";
BA_ "sigSecLevel" SG_ 237 BMS_OperationStates "null";
BA_ "sigConfig" SG_ 237 BMS_BallancingStatus "null";
BA_ "sigExplanation" SG_ 237 BMS_BallancingStatus "null";
BA_ "sigSecLevel" SG_ 237 BMS_BallancingStatus "null";
BA_ "sigConfig" SG_ 237 BMS_ErrorCategory_CAT0 "null";
BA_ "sigExplanation" SG_ 237 BMS_ErrorCategory_CAT0 "null";
BA_ "sigSecLevel" SG_ 237 BMS_ErrorCategory_CAT0 "null";
BA_ "sigConfig" SG_ 237 BMS_ErrorCategory_CAT1 "null";
BA_ "sigExplanation" SG_ 237 BMS_ErrorCategory_CAT1 "null";
BA_ "sigSecLevel" SG_ 237 BMS_ErrorCategory_CAT1 "null";
BA_ "sigConfig" SG_ 237 BMS_ErrorCategory_CAT2 "null";
BA_ "sigExplanation" SG_ 237 BMS_ErrorCategory_CAT2 "null";
BA_ "sigSecLevel" SG_ 237 BMS_ErrorCategory_CAT2 "null";
BA_ "sigConfig" SG_ 237 BMS_ErrorCategory_CAT3 "null";
BA_ "sigExplanation" SG_ 237 BMS_ErrorCategory_CAT3 "null";
BA_ "sigSecLevel" SG_ 237 BMS_ErrorCategory_CAT3 "null";
BA_ "sigConfig" SG_ 237 BMS_ErrorCategory_CAT4 "null";
BA_ "sigExplanation" SG_ 237 BMS_ErrorCategory_CAT4 "null";
BA_ "sigSecLevel" SG_ 237 BMS_ErrorCategory_CAT4 "null";
BA_ "sigConfig" SG_ 237 BMS_ErrorCategory_CAT5 "null";
BA_ "sigExplanation" SG_ 237 BMS_ErrorCategory_CAT5 "null";
BA_ "sigSecLevel" SG_ 237 BMS_ErrorCategory_CAT5 "null";
BA_ "sigConfig" SG_ 237 BMS_ErrorCategory_CAT6 "null";
BA_ "sigExplanation" SG_ 237 BMS_ErrorCategory_CAT6 "null";
BA_ "sigSecLevel" SG_ 237 BMS_ErrorCategory_CAT6 "null";
BA_ "sigConfig" SG_ 237 BMS_ErrorCategory_CAT7 "null";
BA_ "sigExplanation" SG_ 237 BMS_ErrorCategory_CAT7 "null";
BA_ "sigSecLevel" SG_ 237 BMS_ErrorCategory_CAT7 "null";
BA_ "sigConfig" SG_ 237 BMS_ErrorCategory_CAT8 "null";
BA_ "sigExplanation" SG_ 237 BMS_ErrorCategory_CAT8 "null";
BA_ "sigSecLevel" SG_ 237 BMS_ErrorCategory_CAT8 "null";
BA_ "sigConfig" SG_ 237 BMS_HardwareStatus_OK "null";
BA_ "sigExplanation" SG_ 237 BMS_HardwareStatus_OK "null";
BA_ "sigSecLevel" SG_ 237 BMS_HardwareStatus_OK "null";
BA_ "sigConfig" SG_ 237 BMS_ErrorCategory_Mem_Empty "null";
BA_ "sigExplanation" SG_ 237 BMS_ErrorCategory_Mem_Empty "null";
BA_ "sigSecLevel" SG_ 237 BMS_ErrorCategory_Mem_Empty "null";
BA_ "sigConfig" SG_ 237 BMS_ConfigurationStatus_OK "null";
BA_ "sigExplanation" SG_ 237 BMS_ConfigurationStatus_OK "null";
BA_ "sigSecLevel" SG_ 237 BMS_ConfigurationStatus_OK "null";
BA_ "sigConfig" SG_ 237 BMS_MeasurementModules_OK "null";
BA_ "sigExplanation" SG_ 237 BMS_MeasurementModules_OK "null";
BA_ "sigSecLevel" SG_ 237 BMS_MeasurementModules_OK "null";
BA_ "sigConfig" SG_ 237 BMS_BatteryGeneralStatus_OK "null";
BA_ "sigExplanation" SG_ 237 BMS_BatteryGeneralStatus_OK "null";
BA_ "sigSecLevel" SG_ 237 BMS_BatteryGeneralStatus_OK "null";
BA_ "sigConfig" SG_ 237 BMS_SDIL_Sts "null";
BA_ "sigExplanation" SG_ 237 BMS_SDIL_Sts "null";
BA_ "sigSecLevel" SG_ 237 BMS_SDIL_Sts "null";
BA_ "sigConfig" SG_ 237 BMS_CL30C_Sts "null";
BA_ "sigExplanation" SG_ 237 BMS_CL30C_Sts "null";
BA_ "sigSecLevel" SG_ 237 BMS_CL30C_Sts "null";
BA_ "sigConfig" SG_ 237 BMS_CL15_Sts "null";
BA_ "sigExplanation" SG_ 237 BMS_CL15_Sts "null";
BA_ "sigSecLevel" SG_ 237 BMS_CL15_Sts "null";
BA_ "sigConfig" SG_ 237 BMS_HVIL_OK "null";
BA_ "sigExplanation" SG_ 237 BMS_HVIL_OK "null";
BA_ "sigSecLevel" SG_ 237 BMS_HVIL_OK "null";
BA_ "sigConfig" SG_ 237 BMS_HV_ContactorsStatus_OK "null";
BA_ "sigExplanation" SG_ 237 BMS_HV_ContactorsStatus_OK "null";
BA_ "sigSecLevel" SG_ 237 BMS_HV_ContactorsStatus_OK "null";
BA_ "sigConfig" SG_ 237 BMS_SW_Status_OK "null";
BA_ "sigExplanation" SG_ 237 BMS_SW_Status_OK "null";
BA_ "sigSecLevel" SG_ 237 BMS_SW_Status_OK "null";
BA_ "sigConfig" SG_ 237 BMS_CurrentSensor_OK "null";
BA_ "sigExplanation" SG_ 237 BMS_CurrentSensor_OK "null";
BA_ "sigSecLevel" SG_ 237 BMS_CurrentSensor_OK "null";
BA_ "sigConfig" SG_ 237 BMS_IsolatoinStatus_OK "null";
BA_ "sigExplanation" SG_ 237 BMS_IsolatoinStatus_OK "null";
BA_ "sigSecLevel" SG_ 237 BMS_IsolatoinStatus_OK "null";
BA_ "sigConfig" SG_ 237 BMS_StateMAchine_Status "null";
BA_ "sigExplanation" SG_ 237 BMS_StateMAchine_Status "null";
BA_ "sigSecLevel" SG_ 237 BMS_StateMAchine_Status "null";
BA_ "sigConfig" SG_ 237 BMS_BDU_Status "null";
BA_ "sigExplanation" SG_ 237 BMS_BDU_Status "null";
BA_ "sigSecLevel" SG_ 237 BMS_BDU_Status "null";
BA_ "sigConfig" SG_ 238 BMS_Volt_PST_CheckSum "null";
BA_ "sigExplanation" SG_ 238 BMS_Volt_PST_CheckSum "null";
BA_ "sigSecLevel" SG_ 238 BMS_Volt_PST_CheckSum "null";
BA_ "sigConfig" SG_ 238 BMS_Volt_PST_AliveCounter "null";
BA_ "sigExplanation" SG_ 238 BMS_Volt_PST_AliveCounter "null";
BA_ "sigSecLevel" SG_ 238 BMS_Volt_PST_AliveCounter "null";
BA_ "sigConfig" SG_ 238 BMS_Bat_D_MAXvolt_PST "null";
BA_ "sigExplanation" SG_ 238 BMS_Bat_D_MAXvolt_PST "null";
BA_ "sigSecLevel" SG_ 238 BMS_Bat_D_MAXvolt_PST "null";
BA_ "sigConfig" SG_ 238 BMS_Bat_C_MAXvolt_PS "null";
BA_ "sigExplanation" SG_ 238 BMS_Bat_C_MAXvolt_PS "null";
BA_ "sigSecLevel" SG_ 238 BMS_Bat_C_MAXvolt_PS "null";
BA_ "sigConfig" SG_ 242 BMS_Cell_Volt_max "null";
BA_ "sigExplanation" SG_ 242 BMS_Cell_Volt_max "null";
BA_ "sigSecLevel" SG_ 242 BMS_Cell_Volt_max "null";
BA_ "sigConfig" SG_ 242 BMS_Cell_Volt_min "null";
BA_ "sigExplanation" SG_ 242 BMS_Cell_Volt_min "null";
BA_ "sigSecLevel" SG_ 242 BMS_Cell_Volt_min "B";
BA_ "sigConfig" SG_ 242 BMS_Cell_Volt_nom "null";
BA_ "sigExplanation" SG_ 242 BMS_Cell_Volt_nom "null";
BA_ "sigSecLevel" SG_ 242 BMS_Cell_Volt_nom "null";
BA_ "sigConfig" SG_ 276 ESP_114_CheckSum "null";
BA_ "sigExplanation" SG_ 276 ESP_114_CheckSum "null";
BA_ "sigSecLevel" SG_ 276 ESP_114_CheckSum "null";
BA_ "sigConfig" SG_ 276 ESP_114_AliveCounter "null";
BA_ "sigExplanation" SG_ 276 ESP_114_AliveCounter "null";
BA_ "sigSecLevel" SG_ 276 ESP_114_AliveCounter "null";
BA_ "sigConfig" SG_ 276 ESP_FltIndcn_DTC "null";
BA_ "sigExplanation" SG_ 276 ESP_FltIndcn_DTC "null";
BA_ "sigSecLevel" SG_ 276 ESP_FltIndcn_DTC "A";
BA_ "sigConfig" SG_ 276 ESP_ActvSig_VDC "null";
BA_ "sigExplanation" SG_ 276 ESP_ActvSig_VDC "null";
BA_ "sigSecLevel" SG_ 276 ESP_ActvSig_VDC "B";
BA_ "sigConfig" SG_ 276 ESP_ActvSig_TCS "null";
BA_ "sigExplanation" SG_ 276 ESP_ActvSig_TCS "null";
BA_ "sigSecLevel" SG_ 276 ESP_ActvSig_TCS "B";
BA_ "sigConfig" SG_ 276 ESP_ActvSig_EBD "null";
BA_ "sigExplanation" SG_ 276 ESP_ActvSig_EBD "null";
BA_ "sigSecLevel" SG_ 276 ESP_ActvSig_EBD "B";
BA_ "sigConfig" SG_ 276 ESP_ActvSig_DTC "null";
BA_ "sigExplanation" SG_ 276 ESP_ActvSig_DTC "null";
BA_ "sigSecLevel" SG_ 276 ESP_ActvSig_DTC "B";
BA_ "sigConfig" SG_ 276 ESP_WarningOn "null";
BA_ "sigExplanation" SG_ 276 ESP_WarningOn "null";
BA_ "sigSecLevel" SG_ 276 ESP_WarningOn "B";
BA_ "sigConfig" SG_ 276 ESP_Actvndcn_CDD "null";
BA_ "sigExplanation" SG_ 276 ESP_Actvndcn_CDD "null";
BA_ "sigSecLevel" SG_ 276 ESP_Actvndcn_CDD "null";
BA_ "sigConfig" SG_ 276 ESP_FltIndcn_CDD "null";
BA_ "sigExplanation" SG_ 276 ESP_FltIndcn_CDD "null";
BA_ "sigSecLevel" SG_ 276 ESP_FltIndcn_CDD "null";
BA_ "sigConfig" SG_ 276 ESP_ActvIndcn_ABA "null";
BA_ "sigExplanation" SG_ 276 ESP_ActvIndcn_ABA "null";
BA_ "sigSecLevel" SG_ 276 ESP_ActvIndcn_ABA "A";
BA_ "sigConfig" SG_ 276 ESP_FltIndcn_ABA "null";
BA_ "sigExplanation" SG_ 276 ESP_FltIndcn_ABA "null";
BA_ "sigSecLevel" SG_ 276 ESP_FltIndcn_ABA "A";
BA_ "sigConfig" SG_ 276 ESP_ActvIndcn_ABP "null";
BA_ "sigExplanation" SG_ 276 ESP_ActvIndcn_ABP "null";
BA_ "sigSecLevel" SG_ 276 ESP_ActvIndcn_ABP "A";
BA_ "sigConfig" SG_ 276 ESP_FltIndcn_ABP "null";
BA_ "sigExplanation" SG_ 276 ESP_FltIndcn_ABP "null";
BA_ "sigSecLevel" SG_ 276 ESP_FltIndcn_ABP "A";
BA_ "sigConfig" SG_ 276 ESP_ActvIndcn_AEB "null";
BA_ "sigExplanation" SG_ 276 ESP_ActvIndcn_AEB "null";
BA_ "sigSecLevel" SG_ 276 ESP_ActvIndcn_AEB "A";
BA_ "sigConfig" SG_ 276 ESP_FltIndcn_AEB "null";
BA_ "sigExplanation" SG_ 276 ESP_FltIndcn_AEB "null";
BA_ "sigSecLevel" SG_ 276 ESP_FltIndcn_AEB "A";
BA_ "sigConfig" SG_ 276 ESP_ActvIndcn_AWB "null";
BA_ "sigExplanation" SG_ 276 ESP_ActvIndcn_AWB "null";
BA_ "sigSecLevel" SG_ 276 ESP_ActvIndcn_AWB "C";
BA_ "sigConfig" SG_ 276 ESP_FltIndcn_AWB "null";
BA_ "sigExplanation" SG_ 276 ESP_FltIndcn_AWB "null";
BA_ "sigSecLevel" SG_ 276 ESP_FltIndcn_AWB "C";
BA_ "sigConfig" SG_ 276 ESP_VehStandstillIndcn "null";
BA_ "sigExplanation" SG_ 276 ESP_VehStandstillIndcn "null";
BA_ "sigSecLevel" SG_ 276 ESP_VehStandstillIndcn "null";
BA_ "sigConfig" SG_ 276 ESP_BrkOverTIndcn "null";
BA_ "sigExplanation" SG_ 276 ESP_BrkOverTIndcn "null";
BA_ "sigSecLevel" SG_ 276 ESP_BrkOverTIndcn "C";
BA_ "sigConfig" SG_ 276 ESP_FltIndcn_VDC "null";
BA_ "sigExplanation" SG_ 276 ESP_FltIndcn_VDC "null";
BA_ "sigSecLevel" SG_ 276 ESP_FltIndcn_VDC "B";
BA_ "sigConfig" SG_ 276 ESP_ActvIndcn_CDD_AP "null";
BA_ "sigExplanation" SG_ 276 ESP_ActvIndcn_CDD_AP "null";
BA_ "sigSecLevel" SG_ 276 ESP_ActvIndcn_CDD_AP "null";
BA_ "sigConfig" SG_ 276 ESP_FltIndcn_CDD_AP "null";
BA_ "sigExplanation" SG_ 276 ESP_FltIndcn_CDD_AP "null";
BA_ "sigSecLevel" SG_ 276 ESP_FltIndcn_CDD_AP "null";
BA_ "sigConfig" SG_ 336 MCU_F_150_CheckSum "null";
BA_ "sigExplanation" SG_ 336 MCU_F_150_CheckSum "null";
BA_ "sigSecLevel" SG_ 336 MCU_F_150_CheckSum "null";
BA_ "sigConfig" SG_ 336 MCU_F_150_AliveCounter "null";
BA_ "sigExplanation" SG_ 336 MCU_F_150_AliveCounter "null";
BA_ "sigSecLevel" SG_ 336 MCU_F_150_AliveCounter "null";
BA_ "sigConfig" SG_ 336 MCU_F_CrtTqVld "null";
BA_ "sigExplanation" SG_ 336 MCU_F_CrtTqVld "null";
BA_ "sigSecLevel" SG_ 336 MCU_F_CrtTqVld "B";
BA_ "sigConfig" SG_ 336 MCU_F_CrtRotDir "null";
BA_ "sigExplanation" SG_ 336 MCU_F_CrtRotDir "null";
BA_ "sigSecLevel" SG_ 336 MCU_F_CrtRotDir "C";
BA_ "GenSigStartValue" SG_ 336 MCU_F_CrtSpd 32768;
BA_ "sigConfig" SG_ 336 MCU_F_CrtSpd "null";
BA_ "sigExplanation" SG_ 336 MCU_F_CrtSpd "null";
BA_ "sigSecLevel" SG_ 336 MCU_F_CrtSpd "C";
BA_ "GenSigStartValue" SG_ 336 MCU_F_CrtTq 1022;
BA_ "sigConfig" SG_ 336 MCU_F_CrtTq "null";
BA_ "sigExplanation" SG_ 336 MCU_F_CrtTq "null";
BA_ "sigSecLevel" SG_ 336 MCU_F_CrtTq "B";
BA_ "sigConfig" SG_ 336 MCU_F_CrtSpdSigVld "null";
BA_ "sigExplanation" SG_ 336 MCU_F_CrtSpdSigVld "null";
BA_ "sigSecLevel" SG_ 336 MCU_F_CrtSpdSigVld "C";
BA_ "GenSigStartValue" SG_ 336 MCU_F_CrtMod 14;
BA_ "sigConfig" SG_ 336 MCU_F_CrtMod "null";
BA_ "sigExplanation" SG_ 336 MCU_F_CrtMod "null";
BA_ "sigSecLevel" SG_ 336 MCU_F_CrtMod "C";
BA_ "GenSigStartValue" SG_ 336 MCU_F_HVActvDchaSts 6;
BA_ "sigConfig" SG_ 336 MCU_F_HVActvDchaSts "null";
BA_ "sigExplanation" SG_ 336 MCU_F_HVActvDchaSts "null";
BA_ "sigSecLevel" SG_ 336 MCU_F_HVActvDchaSts "B";
BA_ "sigSecLevel" SG_ 336 MCU_F_SlipCtrlActMode "QM";
BA_ "sigConfig" SG_ 336 MCU_F_AlrmLamp_FS "null";
BA_ "sigExplanation" SG_ 336 MCU_F_AlrmLamp_FS "null";
BA_ "sigSecLevel" SG_ 336 MCU_F_AlrmLamp_FS "null";
BA_ "sigConfig" SG_ 336 MCU_F_HVChkEndFlg "null";
BA_ "sigExplanation" SG_ 336 MCU_F_HVChkEndFlg "null";
BA_ "sigSecLevel" SG_ 336 MCU_F_HVChkEndFlg "null";
BA_ "sigConfig" SG_ 337 MCU_R_151_CheckSum "null";
BA_ "sigExplanation" SG_ 337 MCU_R_151_CheckSum "null";
BA_ "sigSecLevel" SG_ 337 MCU_R_151_CheckSum "null";
BA_ "sigConfig" SG_ 337 MCU_R_151_AliveCounter "null";
BA_ "sigExplanation" SG_ 337 MCU_R_151_AliveCounter "null";
BA_ "sigSecLevel" SG_ 337 MCU_R_151_AliveCounter "null";
BA_ "sigConfig" SG_ 337 MCU_R_CrtTqVld "null";
BA_ "sigExplanation" SG_ 337 MCU_R_CrtTqVld "null";
BA_ "sigSecLevel" SG_ 337 MCU_R_CrtTqVld "B";
BA_ "sigConfig" SG_ 337 MCU_R_CrtRotDir "null";
BA_ "sigExplanation" SG_ 337 MCU_R_CrtRotDir "null";
BA_ "sigSecLevel" SG_ 337 MCU_R_CrtRotDir "C";
BA_ "GenSigStartValue" SG_ 337 MCU_R_CrtSpd 32768;
BA_ "sigConfig" SG_ 337 MCU_R_CrtSpd "null";
BA_ "sigExplanation" SG_ 337 MCU_R_CrtSpd "null";
BA_ "sigSecLevel" SG_ 337 MCU_R_CrtSpd "C";
BA_ "GenSigStartValue" SG_ 337 MCU_R_CrtTq 1022;
BA_ "sigConfig" SG_ 337 MCU_R_CrtTq "null";
BA_ "sigExplanation" SG_ 337 MCU_R_CrtTq "null";
BA_ "sigSecLevel" SG_ 337 MCU_R_CrtTq "B";
BA_ "sigConfig" SG_ 337 MCU_R_CrtSpdSigVld "null";
BA_ "sigExplanation" SG_ 337 MCU_R_CrtSpdSigVld "null";
BA_ "sigSecLevel" SG_ 337 MCU_R_CrtSpdSigVld "C";
BA_ "GenSigStartValue" SG_ 337 MCU_R_CrtMod 14;
BA_ "sigConfig" SG_ 337 MCU_R_CrtMod "null";
BA_ "sigExplanation" SG_ 337 MCU_R_CrtMod "null";
BA_ "sigSecLevel" SG_ 337 MCU_R_CrtMod "C";
BA_ "sigConfig" SG_ 337 MCU_R_Decoup_State "C";
BA_ "sigExplanation" SG_ 337 MCU_R_Decoup_State "null";
BA_ "sigSecLevel" SG_ 337 MCU_R_Decoup_State "C";
BA_ "GenSigStartValue" SG_ 337 MCU_R_HVActvDchaSts 6;
BA_ "sigConfig" SG_ 337 MCU_R_HVActvDchaSts "null";
BA_ "sigExplanation" SG_ 337 MCU_R_HVActvDchaSts "null";
BA_ "sigSecLevel" SG_ 337 MCU_R_HVActvDchaSts "B";
BA_ "sigSecLevel" SG_ 337 MCU_R_SlipCtrlActMode "QM";
BA_ "sigConfig" SG_ 337 MCU_R_AlrmLamp_FS "null";
BA_ "sigExplanation" SG_ 337 MCU_R_AlrmLamp_FS "null";
BA_ "sigSecLevel" SG_ 337 MCU_R_AlrmLamp_FS "null";
BA_ "sigConfig" SG_ 337 MCU_R_HVChkEndFlg "null";
BA_ "sigExplanation" SG_ 337 MCU_R_HVChkEndFlg "null";
BA_ "sigSecLevel" SG_ 337 MCU_R_HVChkEndFlg "null";
BA_ "sigConfig" SG_ 345 ACU_159_CheckSum "null";
BA_ "sigExplanation" SG_ 345 ACU_159_CheckSum "null";
BA_ "sigSecLevel" SG_ 345 ACU_159_CheckSum "null";
BA_ "sigConfig" SG_ 345 ACU_159_AliveCounter "null";
BA_ "sigExplanation" SG_ 345 ACU_159_AliveCounter "null";
BA_ "sigSecLevel" SG_ 345 ACU_159_AliveCounter "null";
BA_ "sigConfig" SG_ 345 ACU_Pass_OCS_St "null";
BA_ "sigExplanation" SG_ 345 ACU_Pass_OCS_St "null";
BA_ "sigSecLevel" SG_ 345 ACU_Pass_OCS_St "null";
BA_ "sigConfig" SG_ 345 ACU_AirBagSysAlrmLampSts "null";
BA_ "sigExplanation" SG_ 345 ACU_AirBagSysAlrmLampSts "null";
BA_ "sigSecLevel" SG_ 345 ACU_AirBagSysAlrmLampSts "null";
BA_ "sigConfig" SG_ 345 ACU_Pass_Airbag_LED "null";
BA_ "sigExplanation" SG_ 345 ACU_Pass_Airbag_LED "null";
BA_ "sigSecLevel" SG_ 345 ACU_Pass_Airbag_LED "null";
BA_ "sigConfig" SG_ 345 ACU_Drvr_Occpt_St "null";
BA_ "sigExplanation" SG_ 345 ACU_Drvr_Occpt_St "null";
BA_ "sigSecLevel" SG_ 345 ACU_Drvr_Occpt_St "A";
BA_ "sigConfig" SG_ 345 ACU_BucSwtStFrntDrvr "null";
BA_ "sigExplanation" SG_ 345 ACU_BucSwtStFrntDrvr "null";
BA_ "sigSecLevel" SG_ 345 ACU_BucSwtStFrntDrvr "A";
BA_ "sigConfig" SG_ 345 ACU_BucSwtStFrntPass "null";
BA_ "sigExplanation" SG_ 345 ACU_BucSwtStFrntPass "null";
BA_ "sigSecLevel" SG_ 345 ACU_BucSwtStFrntPass "null";
BA_ "sigConfig" SG_ 345 ACU_SeatTrkPosnSwtFrntDrvr "null";
BA_ "sigExplanation" SG_ 345 ACU_SeatTrkPosnSwtFrntDrvr "null";
BA_ "sigSecLevel" SG_ 345 ACU_SeatTrkPosnSwtFrntDrvr "null";
BA_ "sigConfig" SG_ 345 ACU_SeatTrkPosnSwtFrntPass "null";
BA_ "sigExplanation" SG_ 345 ACU_SeatTrkPosnSwtFrntPass "null";
BA_ "sigSecLevel" SG_ 345 ACU_SeatTrkPosnSwtFrntPass "null";
BA_ "sigConfig" SG_ 393 CIM_189_CheckSum "null";
BA_ "sigExplanation" SG_ 393 CIM_189_CheckSum "null";
BA_ "sigSecLevel" SG_ 393 CIM_189_CheckSum "null";
BA_ "sigConfig" SG_ 393 CIM_189_AliveCounter "null";
BA_ "sigExplanation" SG_ 393 CIM_189_AliveCounter "null";
BA_ "sigSecLevel" SG_ 393 CIM_189_AliveCounter "null";
BA_ "sigConfig" SG_ 393 CIM_PBtnSts1 "null";
BA_ "sigExplanation" SG_ 393 CIM_PBtnSts1 "null";
BA_ "sigSecLevel" SG_ 393 CIM_PBtnSts1 "B";
BA_ "sigConfig" SG_ 393 CIM_PBtnSts2 "null";
BA_ "sigExplanation" SG_ 393 CIM_PBtnSts2 "null";
BA_ "sigSecLevel" SG_ 393 CIM_PBtnSts2 "B";
BA_ "sigConfig" SG_ 393 CIM_PBtnVld "null";
BA_ "sigExplanation" SG_ 393 CIM_PBtnVld "null";
BA_ "sigSecLevel" SG_ 393 CIM_PBtnVld "B";
BA_ "sigConfig" SG_ 393 CIM_GearLvrCrtPosnInfo "null";
BA_ "sigExplanation" SG_ 393 CIM_GearLvrCrtPosnInfo "null";
BA_ "sigSecLevel" SG_ 393 CIM_GearLvrCrtPosnInfo "null";
BA_ "sigConfig" SG_ 393 CIM_GearleverFltSts "null";
BA_ "sigExplanation" SG_ 393 CIM_GearleverFltSts "null";
BA_ "sigSecLevel" SG_ 393 CIM_GearleverFltSts "null";
BA_ "sigConfig" SG_ 416 VCU_ECC_PwrMax "null";
BA_ "sigExplanation" SG_ 416 VCU_ECC_PwrMax "null";
BA_ "sigSecLevel" SG_ 416 VCU_ECC_PwrMax "null";
BA_ "sigConfig" SG_ 416 VCU_ECC_PwrMin "null";
BA_ "sigExplanation" SG_ 416 VCU_ECC_PwrMin "null";
BA_ "sigSecLevel" SG_ 416 VCU_ECC_PwrMin "null";
BA_ "sigConfig" SG_ 416 VCU_DCDCPwrLimCmd "null";
BA_ "sigExplanation" SG_ 416 VCU_DCDCPwrLimCmd "null";
BA_ "sigSecLevel" SG_ 416 VCU_DCDCPwrLimCmd "null";
BA_ "sigConfig" SG_ 425 ECC_VCU_ReqChgPwrLim "null";
BA_ "sigExplanation" SG_ 425 ECC_VCU_ReqChgPwrLim "null";
BA_ "sigSecLevel" SG_ 425 ECC_VCU_ReqChgPwrLim "null";
BA_ "sigConfig" SG_ 425 ECC_VCU_PwrReq "null";
BA_ "sigExplanation" SG_ 425 ECC_VCU_PwrReq "null";
BA_ "sigSecLevel" SG_ 425 ECC_VCU_PwrReq "null";
BA_ "sigConfig" SG_ 438 PKC_1B6_CheckSum "null";
BA_ "sigExplanation" SG_ 438 PKC_1B6_CheckSum "null";
BA_ "sigSecLevel" SG_ 438 PKC_1B6_CheckSum "null";
BA_ "sigConfig" SG_ 438 PKC_1B6_AliveCounter "null";
BA_ "sigExplanation" SG_ 438 PKC_1B6_AliveCounter "null";
BA_ "sigSecLevel" SG_ 438 PKC_1B6_AliveCounter "null";
BA_ "sigConfig" SG_ 438 PKC_RemPwrOnOffReq "null";
BA_ "sigExplanation" SG_ 438 PKC_RemPwrOnOffReq "null";
BA_ "sigSecLevel" SG_ 438 PKC_RemPwrOnOffReq "null";
BA_ "sigConfig" SG_ 438 PKC_RemDrvgReq "null";
BA_ "sigExplanation" SG_ 438 PKC_RemDrvgReq "null";
BA_ "sigSecLevel" SG_ 438 PKC_RemDrvgReq "null";
BA_ "sigConfig" SG_ 438 PKC_RemChrgDchaGunUnlckCmd "null";
BA_ "sigExplanation" SG_ 438 PKC_RemChrgDchaGunUnlckCmd "null";
BA_ "sigSecLevel" SG_ 438 PKC_RemChrgDchaGunUnlckCmd "null";
BA_ "sigConfig" SG_ 438 PKC_RmteDviceBattLvl "null";
BA_ "sigExplanation" SG_ 438 PKC_RmteDviceBattLvl "null";
BA_ "sigSecLevel" SG_ 438 PKC_RmteDviceBattLvl "null";
BA_ "sigConfig" SG_ 438 PKC_BLE_Online "null";
BA_ "sigExplanation" SG_ 438 PKC_BLE_Online "null";
BA_ "sigSecLevel" SG_ 438 PKC_BLE_Online "null";
BA_ "sigConfig" SG_ 438 PKC_DviceRngeDist "null";
BA_ "sigExplanation" SG_ 438 PKC_DviceRngeDist "null";
BA_ "sigSecLevel" SG_ 438 PKC_DviceRngeDist "null";
BA_ "sigConfig" SG_ 438 PKC_DviceAliveCnt "null";
BA_ "sigExplanation" SG_ 438 PKC_DviceAliveCnt "null";
BA_ "sigSecLevel" SG_ 438 PKC_DviceAliveCnt "null";
BA_ "sigConfig" SG_ 438 PKC_MnvreEnblInput "null";
BA_ "sigExplanation" SG_ 438 PKC_MnvreEnblInput "null";
BA_ "sigSecLevel" SG_ 438 PKC_MnvreEnblInput "null";
BA_ "sigConfig" SG_ 438 PKC_RapActDeactInp "null";
BA_ "sigExplanation" SG_ 438 PKC_RapActDeactInp "null";
BA_ "sigSecLevel" SG_ 438 PKC_RapActDeactInp "null";
BA_ "sigConfig" SG_ 438 PKC_MnvrRemsumeKey "null";
BA_ "sigExplanation" SG_ 438 PKC_MnvrRemsumeKey "null";
BA_ "sigSecLevel" SG_ 438 PKC_MnvrRemsumeKey "null";
BA_ "sigConfig" SG_ 438 PKC_MnvrRtnStartKey "null";
BA_ "sigExplanation" SG_ 438 PKC_MnvrRtnStartKey "null";
BA_ "sigSecLevel" SG_ 438 PKC_MnvrRtnStartKey "null";
BA_ "sigConfig" SG_ 532 VCU_214_234_CheckSum "null";
BA_ "sigExplanation" SG_ 532 VCU_214_234_CheckSum "null";
BA_ "sigSecLevel" SG_ 532 VCU_214_234_CheckSum "null";
BA_ "sigConfig" SG_ 532 VCU_214_234_AliveCounter "null";
BA_ "sigExplanation" SG_ 532 VCU_214_234_AliveCounter "null";
BA_ "sigSecLevel" SG_ 532 VCU_214_234_AliveCounter "null";
BA_ "sigConfig" SG_ 532 VCU_RdyLamp "null";
BA_ "sigExplanation" SG_ 532 VCU_RdyLamp "null";
BA_ "sigSecLevel" SG_ 532 VCU_RdyLamp "null";
BA_ "sigConfig" SG_ 532 VCU_BrkLampCtrlSts "null";
BA_ "sigExplanation" SG_ 532 VCU_BrkLampCtrlSts "null";
BA_ "sigSecLevel" SG_ 532 VCU_BrkLampCtrlSts "null";
BA_ "sigConfig" SG_ 532 VCU_RemWakeUpEndFlg "null";
BA_ "sigExplanation" SG_ 532 VCU_RemWakeUpEndFlg "null";
BA_ "sigSecLevel" SG_ 532 VCU_RemWakeUpEndFlg "null";
BA_ "sigConfig" SG_ 532 VCU_StgyGearSig "null";
BA_ "sigExplanation" SG_ 532 VCU_StgyGearSig "null";
BA_ "sigSecLevel" SG_ 532 VCU_StgyGearSig "B";
BA_ "sigConfig" SG_ 532 VCU_ShiftMisoper "null";
BA_ "sigExplanation" SG_ 532 VCU_ShiftMisoper "null";
BA_ "sigSecLevel" SG_ 532 VCU_ShiftMisoper "null";
BA_ "sigConfig" SG_ 532 VCU_GearSigVld "null";
BA_ "sigExplanation" SG_ 532 VCU_GearSigVld "null";
BA_ "sigSecLevel" SG_ 532 VCU_GearSigVld "C";
BA_ "sigConfig" SG_ 532 VCU_GearSig "null";
BA_ "sigExplanation" SG_ 532 VCU_GearSig "null";
BA_ "sigSecLevel" SG_ 532 VCU_GearSig "C";
BA_ "sigConfig" SG_ 532 VCU_ACCRdy "null";
BA_ "sigExplanation" SG_ 532 VCU_ACCRdy "null";
BA_ "sigSecLevel" SG_ 532 VCU_ACCRdy "null";
BA_ "sigConfig" SG_ 532 VCU_ParkRdy "null";
BA_ "sigExplanation" SG_ 532 VCU_ParkRdy "null";
BA_ "sigSecLevel" SG_ 532 VCU_ParkRdy "null";
BA_ "sigConfig" SG_ 532 VCU_APSPercVld "null";
BA_ "sigExplanation" SG_ 532 VCU_APSPercVld "null";
BA_ "sigSecLevel" SG_ 532 VCU_APSPercVld "null";
BA_ "sigConfig" SG_ 532 VCU_VehSt "null";
BA_ "sigExplanation" SG_ 532 VCU_VehSt "null";
BA_ "sigSecLevel" SG_ 532 VCU_VehSt "B";
BA_ "sigConfig" SG_ 532 VCU_APSPerc "null";
BA_ "sigExplanation" SG_ 532 VCU_APSPerc "null";
BA_ "sigSecLevel" SG_ 532 VCU_APSPerc "B";
BA_ "sigConfig" SG_ 532 VCU_BrkSig "null";
BA_ "sigExplanation" SG_ 532 VCU_BrkSig "null";
BA_ "sigSecLevel" SG_ 532 VCU_BrkSig "null";
BA_ "sigConfig" SG_ 532 VCU_BrkSigVld "null";
BA_ "sigExplanation" SG_ 532 VCU_BrkSigVld "null";
BA_ "sigSecLevel" SG_ 532 VCU_BrkSigVld "null";
BA_ "sigConfig" SG_ 532 VCU_DrvModSigFb "null";
BA_ "sigExplanation" SG_ 532 VCU_DrvModSigFb "null";
BA_ "sigSecLevel" SG_ 532 VCU_DrvModSigFb "null";
BA_ "sigConfig" SG_ 532 VCU_DrvModShiftMisoper "null";
BA_ "sigExplanation" SG_ 532 VCU_DrvModShiftMisoper "null";
BA_ "sigSecLevel" SG_ 532 VCU_DrvModShiftMisoper "null";
BA_ "sigConfig" SG_ 532 VCU_SpclTerrainModEnaSig "null";
BA_ "sigExplanation" SG_ 532 VCU_SpclTerrainModEnaSig "null";
BA_ "sigSecLevel" SG_ 532 VCU_SpclTerrainModEnaSig "null";
BA_ "sigConfig" SG_ 532 VCU_214_SSecOC_Fresh_Byte0 "null";
BA_ "sigExplanation" SG_ 532 VCU_214_SSecOC_Fresh_Byte0 "null";
BA_ "sigSecLevel" SG_ 532 VCU_214_SSecOC_Fresh_Byte0 "null";
BA_ "sigConfig" SG_ 532 VCU_214_SSecOC_MAC_Byte0 "null";
BA_ "sigExplanation" SG_ 532 VCU_214_SSecOC_MAC_Byte0 "null";
BA_ "sigSecLevel" SG_ 532 VCU_214_SSecOC_MAC_Byte0 "null";
BA_ "sigConfig" SG_ 532 VCU_214_SSecOC_MAC_Byte1 "null";
BA_ "sigExplanation" SG_ 532 VCU_214_SSecOC_MAC_Byte1 "null";
BA_ "sigSecLevel" SG_ 532 VCU_214_SSecOC_MAC_Byte1 "null";
BA_ "sigConfig" SG_ 532 VCU_214_SSecOC_MAC_Byte2 "null";
BA_ "sigExplanation" SG_ 532 VCU_214_SSecOC_MAC_Byte2 "null";
BA_ "sigSecLevel" SG_ 532 VCU_214_SSecOC_MAC_Byte2 "null";
BA_ "sigConfig" SG_ 533 BMS_215_CheckSum "null";
BA_ "sigExplanation" SG_ 533 BMS_215_CheckSum "null";
BA_ "sigSecLevel" SG_ 533 BMS_215_CheckSum "null";
BA_ "sigConfig" SG_ 533 BMS_215_AliveCounter "null";
BA_ "sigExplanation" SG_ 533 BMS_215_AliveCounter "null";
BA_ "sigSecLevel" SG_ 533 BMS_215_AliveCounter "null";
BA_ "sigConfig" SG_ 533 BMS_PwrBattOverTFlt_FS "null";
BA_ "sigExplanation" SG_ 533 BMS_PwrBattOverTFlt_FS "null";
BA_ "sigSecLevel" SG_ 533 BMS_PwrBattOverTFlt_FS "null";
BA_ "sigConfig" SG_ 533 BMS_PwrBattOverCrtFlt_FS "null";
BA_ "sigExplanation" SG_ 533 BMS_PwrBattOverCrtFlt_FS "null";
BA_ "sigSecLevel" SG_ 533 BMS_PwrBattOverCrtFlt_FS "null";
BA_ "sigConfig" SG_ 533 BMS_PwrBattNegRlyAdh_FS "null";
BA_ "sigExplanation" SG_ 533 BMS_PwrBattNegRlyAdh_FS "null";
BA_ "sigSecLevel" SG_ 533 BMS_PwrBattNegRlyAdh_FS "null";
BA_ "sigConfig" SG_ 533 BMS_PwrBattPosRlyAdh_FS "null";
BA_ "sigExplanation" SG_ 533 BMS_PwrBattPosRlyAdh_FS "null";
BA_ "sigSecLevel" SG_ 533 BMS_PwrBattPosRlyAdh_FS "null";
BA_ "sigConfig" SG_ 533 BMS_CellUnderrVoltFlt_FS "null";
BA_ "sigExplanation" SG_ 533 BMS_CellUnderrVoltFlt_FS "null";
BA_ "sigSecLevel" SG_ 533 BMS_CellUnderrVoltFlt_FS "null";
BA_ "sigConfig" SG_ 533 BMS_PwrBattCellOverVolt_FS "null";
BA_ "sigExplanation" SG_ 533 BMS_PwrBattCellOverVolt_FS "null";
BA_ "sigSecLevel" SG_ 533 BMS_PwrBattCellOverVolt_FS "B";
BA_ "sigConfig" SG_ 533 BMS_BattInlTSnsrFlt "null";
BA_ "sigExplanation" SG_ 533 BMS_BattInlTSnsrFlt "null";
BA_ "sigSecLevel" SG_ 533 BMS_BattInlTSnsrFlt "null";
BA_ "sigConfig" SG_ 533 BMS_BattOutlTSnsrFlt "null";
BA_ "sigExplanation" SG_ 533 BMS_BattOutlTSnsrFlt "null";
BA_ "sigSecLevel" SG_ 533 BMS_BattOutlTSnsrFlt "null";
BA_ "sigConfig" SG_ 533 BMS_PwrBattPrecRlyAdh_FS "null";
BA_ "sigExplanation" SG_ 533 BMS_PwrBattPrecRlyAdh_FS "null";
BA_ "sigSecLevel" SG_ 533 BMS_PwrBattPrecRlyAdh_FS "null";
BA_ "sigConfig" SG_ 533 BMS_AlrmLamp_FS "null";
BA_ "sigExplanation" SG_ 533 BMS_AlrmLamp_FS "null";
BA_ "sigSecLevel" SG_ 533 BMS_AlrmLamp_FS "null";
BA_ "sigConfig" SG_ 533 BMS_PwrBattLoadTotVoltV3_FS "null";
BA_ "sigExplanation" SG_ 533 BMS_PwrBattLoadTotVoltV3_FS "null";
BA_ "sigSecLevel" SG_ 533 BMS_PwrBattLoadTotVoltV3_FS "null";
BA_ "sigConfig" SG_ 533 BMS_FctSftyErrCod "null";
BA_ "sigExplanation" SG_ 533 BMS_FctSftyErrCod "null";
BA_ "sigSecLevel" SG_ 533 BMS_FctSftyErrCod "B";
BA_ "sigConfig" SG_ 549 VCU_225_CheckSum "null";
BA_ "sigExplanation" SG_ 549 VCU_225_CheckSum "null";
BA_ "sigSecLevel" SG_ 549 VCU_225_CheckSum "null";
BA_ "sigConfig" SG_ 549 VCU_225_AliveCounter "null";
BA_ "sigExplanation" SG_ 549 VCU_225_AliveCounter "null";
BA_ "sigSecLevel" SG_ 549 VCU_225_AliveCounter "null";
BA_ "GenSigStartValue" SG_ 549 VCU_BusCrtEstim 25000;
BA_ "sigConfig" SG_ 549 VCU_BusCrtEstim "null";
BA_ "sigExplanation" SG_ 549 VCU_BusCrtEstim "null";
BA_ "sigSecLevel" SG_ 549 VCU_BusCrtEstim "null";
BA_ "sigConfig" SG_ 549 VCU_VehFltProcLvl "null";
BA_ "sigExplanation" SG_ 549 VCU_VehFltProcLvl "null";
BA_ "sigSecLevel" SG_ 549 VCU_VehFltProcLvl "null";
BA_ "sigConfig" SG_ 549 VCU_OverMod "null";
BA_ "sigExplanation" SG_ 549 VCU_OverMod "null";
BA_ "sigSecLevel" SG_ 549 VCU_OverMod "null";
BA_ "sigConfig" SG_ 549 VCU_MotChkACCFltFbFlg "null";
BA_ "sigExplanation" SG_ 549 VCU_MotChkACCFltFbFlg "null";
BA_ "sigSecLevel" SG_ 549 VCU_MotChkACCFltFbFlg "null";
BA_ "sigConfig" SG_ 549 VCU_VehTqFltSts "null";
BA_ "sigExplanation" SG_ 549 VCU_VehTqFltSts "null";
BA_ "sigSecLevel" SG_ 549 VCU_VehTqFltSts "null";
BA_ "sigConfig" SG_ 549 VCU_PwrAntitheftAuthentReqFlg "null";
BA_ "sigExplanation" SG_ 549 VCU_PwrAntitheftAuthentReqFlg "null";
BA_ "sigSecLevel" SG_ 549 VCU_PwrAntitheftAuthentReqFlg "null";
BA_ "sigConfig" SG_ 549 VCU_PwrModSwtReq "null";
BA_ "sigExplanation" SG_ 549 VCU_PwrModSwtReq "null";
BA_ "sigSecLevel" SG_ 549 VCU_PwrModSwtReq "null";
BA_ "GenSigStartValue" SG_ 549 VCU_VehMaxWhlTq 32768;
BA_ "sigConfig" SG_ 549 VCU_VehMaxWhlTq "null";
BA_ "sigExplanation" SG_ 549 VCU_VehMaxWhlTq "null";
BA_ "sigSecLevel" SG_ 549 VCU_VehMaxWhlTq "null";
BA_REL_ "SC_Verification" BU_SG_REL_ BMS SG_ 32 Syn_TripCntrVal_Byte0_All 1;
BA_REL_ "SC_Verification" BU_SG_REL_ OBC SG_ 32 Syn_TripCntrVal_Byte0_All 1;
BA_REL_ "SC_Verification" BU_SG_REL_ VCU SG_ 32 Syn_TripCntrVal_Byte0_All 1;
BA_REL_ "SC_Verification" BU_SG_REL_ BMS SG_ 32 Syn_TripCntrVal_Byte1_All 1;
BA_REL_ "SC_Verification" BU_SG_REL_ OBC SG_ 32 Syn_TripCntrVal_Byte1_All 1;
BA_REL_ "SC_Verification" BU_SG_REL_ VCU SG_ 32 Syn_TripCntrVal_Byte1_All 1;
BA_REL_ "SC_Verification" BU_SG_REL_ BMS SG_ 32 Syn_RstCntrVal_Byte0_All 1;
BA_REL_ "SC_Verification" BU_SG_REL_ OBC SG_ 32 Syn_RstCntrVal_Byte0_All 1;
BA_REL_ "SC_Verification" BU_SG_REL_ VCU SG_ 32 Syn_RstCntrVal_Byte0_All 1;
BA_REL_ "SC_Verification" BU_SG_REL_ BMS SG_ 32 Syn_RstCntrVal_Byte1_All 1;
BA_REL_ "SC_Verification" BU_SG_REL_ OBC SG_ 32 Syn_RstCntrVal_Byte1_All 1;
BA_REL_ "SC_Verification" BU_SG_REL_ VCU SG_ 32 Syn_RstCntrVal_Byte1_All 1;
BA_REL_ "SC_Verification" BU_SG_REL_ BMS SG_ 32 Syn_MACInfo_Byte0_All 1;
BA_REL_ "SC_Verification" BU_SG_REL_ OBC SG_ 32 Syn_MACInfo_Byte0_All 1;
BA_REL_ "SC_Verification" BU_SG_REL_ VCU SG_ 32 Syn_MACInfo_Byte0_All 1;
BA_REL_ "SC_Verification" BU_SG_REL_ BMS SG_ 32 Syn_MACInfo_Byte1_All 1;
BA_REL_ "SC_Verification" BU_SG_REL_ OBC SG_ 32 Syn_MACInfo_Byte1_All 1;
BA_REL_ "SC_Verification" BU_SG_REL_ VCU SG_ 32 Syn_MACInfo_Byte1_All 1;
BA_REL_ "SC_Verification" BU_SG_REL_ BMS SG_ 32 Syn_MACInfo_Byte2_All 1;
BA_REL_ "SC_Verification" BU_SG_REL_ OBC SG_ 32 Syn_MACInfo_Byte2_All 1;
BA_REL_ "SC_Verification" BU_SG_REL_ VCU SG_ 32 Syn_MACInfo_Byte2_All 1;
VAL_ 54 TBOX_RemSeekCarCtrlCmd 0 "without_remote_control" 1 "Remote_flash_lamp" 2 "Sound_horn_remotely" 3 "Remote_flashing_horn" ;
VAL_ 54 TBOX_RemClsTrCmd 0 "without_remote_control" 1 "Remote_open_tailgate" 2 "Remote_close_tailgate" 3 "Reserved" ;
VAL_ 54 TBOX_RemDrvrSeatVentnCmd 0 "Void" 1 "Remote_driver_seat_ventilation_high_gear" 2 "remote_driver_seat_ventilation_middle_gear" 3 "remote_driver_seat_ventilation_low_gear" 4 "remotely_close_driver_seat_ventilation" 5 "Reserved" 6 "Reserved" 7 "Reserved" ;
VAL_ 54 TBOX_RemDrvrSeatHeatgCmd 0 "Void" 1 "remote_driver's_seat_heating_high_gear" 2 "remote_driver_seat_heating_mid_gear" 3 "remote_driver's_seat_heating_low_gear" 4 "remotely_close_driver_seat_heating" 5 "Reserved" 6 "Reserved" 7 "Reserved" ;
VAL_ 54 TBOX_RemSetWelFct 0 "No_remote_setting" 1 "function_on" 2 "function_OFF" 3 "Reserved" ;
VAL_ 54 TBOX_RemPassSeatVentnCmd 0 "without_remote_control" 1 "Open_the_first_position_of_the_passenger_seat_remotely" 2 "Open_the_second_ventilation_gear_of_the_passenger_seat_remotely" 3 "Remote_driving_passenger_seat_ventilation_third_gear" 4 "Remote_closing_passenger_seat_heating" 5 "Reserved" 6 "Reserved" 7 "Reserved" ;
VAL_ 54 TBOX_RemPassSeatHeatgCmd 0 "without_remote_control" 1 "Remote_open_passenger_seat_heating_first_gear" 2 "Remote_passenger_seat_heating_second_gear" 3 "Remote_passenger_seat_heating_third_gear" 4 "Remote_closing_passenger_seat_heating" 5 "Reserved" 6 "Reserved" 7 "Reserved" ;
VAL_ 54 TBOX_ClsAVMFct_ICC 0 "without_remote_control" 1 "Turn_off_ICC" ;
VAL_ 54 TBOX_ClsRemAVMFct_AVAP 0 "without_remote_control" 1 "Turn_off_AVAP" ;
VAL_ 54 TBOX_RemSetFolwMeFct_BCM 0 "No_remote_setting" 1 "Follow_Me_Home_function_OFF" 2 "headlamp_delay:15_s" 3 "Headlamp_delay:30_s" 4 "Headlamp_delay:45_s" 5 "Headlamp_delay_60_s" 6 "Reserved" 7 "Reserved" ;
VAL_ 54 TBOX_RemSetCtrlLockFct_PKC 0 "No_remote_setting" 1 "function_on" 2 "function_OFF" 3 "Reserved" ;
VAL_ 54 TBOX_RemSetKickSnsrFct 0 "No_remote_setting" 1 "function_on" 2 "function_OFF" 3 "Reserved" ;
VAL_ 54 TBOX_VideoCtrlReq 0 "No_remote_view_command" 1 "panoramic" 2 "Left_side" 3 "Right" 4 "Front_side" 5 "Rear_side" 6 "Turn_off_views" 7 "Reserved" ;
VAL_ 54 TBOX_VoiceBlowerLimReq 0 "No_request" 1 "Request" ;
VAL_ 54 TBOX_RemCtrlCmdFb 0 "Void" 1 "Successful" 2 "Failed" 3 "Reserved" ;
VAL_ 54 TBOX_CtrlReMirrReq 0 "without_control" 1 "Unfold_rear-view_mirror" 2 "Folding_rear-view_mirrors" 3 "Invalid_value" ;
VAL_ 54 TBOX_eCallMuteSt 0 "No_actiont" 1 "EcallUnmute" 2 "AutomaticEcallMute" 3 "ManualEcallMute" ;
VAL_ 54 TBOX_RemReScrnHeatgCmd 0 "No_Req_/_Stop_heating" 1 "Heating_Req" 2 "Reserved" 3 "Invalid" ;
VAL_ 54 TBOX_eCallSt 0 "eCall_Standby" 1 "eCall_in_Testmode" 2 "eCall_FAILURE" 3 "eCall_DEACTIVATED" 4 "eCall_Active_manual_triggered" 5 "eCall_Active_automatic_triggered" 6 "Reserved" 7 "Reserved" ;
VAL_ 88 TBOX_RemClsWin_RW_CtrlCmd 126 "No_operation" 127 "Invalid" ;
VAL_ 88 TBOX_California_mode 0 "INIT" 1 "ON" 2 "OFF" 3 "INVALID" ;
VAL_ 88 TBOX_RemClsSunroofCtrlCmd 127 "Invalid" ;
VAL_ 89 ACU_FrntCrashOutpSts 0 "no_crash,_level_0" 1 "front_crash_low,_level_1" 2 "front_crash_high,_level_2" 3 "unused" 4 "unused" 5 "unused" 6 "unused" 7 "invalid" ;
VAL_ 89 ACU_RiSideCrashOutpSts 0 "no_crash,_level_0" 1 "right_side_crash_high,_level_2" 2 "unused" 3 "invalid" ;
VAL_ 89 ACU_LeSideCrashOutpSts 0 "no_crash,_level_0" 1 "left_side_crash_high,_level_2" 2 "unused" 3 "invalid" ;
VAL_ 89 ACU_RearCrashOutpSts 0 "no_crash,_level_0" 1 "rear_crash_high,_level_2" 2 "unused" 3 "invalid" ;
VAL_ 89 ACU_RollovrCrashOutpSts 0 "no_crash,_level_0" 1 "rollover_crash,_level_2" 2 "unused" 3 "invalid" ;
VAL_ 89 ACU_Crash_cfm 0 "no_crash" 1 "crash_happened" 2 "not_used" 3 "invalid" ;
VAL_ 117 VCU_SUB_ID_75 0 "Reserved" 1 "Report_VCU_Learning_Status" 2 "Reserved" 3 "Reserved" 4 "Reserved" 5 "Response_To_Set_Learnt_Command" 6 "Reserved" 7 "Reserved" 8 "Reserved" 9 "Reserved" 10 "Reserved" 11 "Reserved" 12 "Reserved" 13 "Reserved" 14 "Reserved" 15 "Reserved" 16 "Reserved" 17 "Reserved" 18 "Reserved" 19 "Reserved" 20 "Reserved" 21 "Reserved" 22 "Reserved" 23 "Reserved" 24 "Reserved" 25 "Reserved" 26 "Reserved" 27 "Reserved" 28 "Reserved" 29 "Reserved" 30 "Reserved" 31 "Reserved" 32 "Reserved" 33 "Reserved" 34 "Reserved" 35 "Reserved" 36 "Reserved" 37 "Reserved" 38 "Reserved" 39 "Reserved" 40 "Reserved" 41 "Reserved" 42 "Reserved" 43 "Reserved" 44 "Reserved" 45 "Reserved" 46 "Reserved" 47 "Reserved" 48 "Reserved" 49 "Reserved" 50 "Reserved" 51 "Reserved" 52 "Reserved" 53 "Reserved" 54 "Reserved" 55 "Reserved" 56 "Reserved" 57 "Reserved" 58 "Reserved" 59 "Reserved" 60 "Reserved" 61 "Reserved" 62 "Reserved" 63 "Reserved" 64 "Reserved" 65 "Reserved" 66 "Reserved" 67 "Reserved" 68 "Reserved" 69 "Reserved" 70 "Reserved" 71 "Reserved" 72 "Reserved" 73 "Reserved" 74 "Reserved" 75 "Reserved" 76 "Reserved" 77 "Reserved" 78 "Reserved" 79 "Reserved" 80 "Reserved" 81 "Reserved" 82 "Reserved" 83 "Reserved" 84 "Reserved" 85 "Reserved" 86 "Reserved" 87 "Reserved" 88 "Reserved" 89 "Reserved" 90 "Reserved" 91 "Reserved" 92 "Reserved" 93 "Reserved" 94 "Reserved" 95 "Reserved" 96 "Reserved" 97 "Reserved" 98 "Reserved" 99 "Reserved" 100 "Reserved" 101 "Reserved" 102 "Reserved" 103 "Reserved" 104 "Reserved" 105 "Reserved" 106 "Reserved" 107 "Reserved" 108 "Reserved" 109 "Reserved" 110 "Reserved" 111 "Reserved" 112 "Reserved" 113 "Reserved" 114 "Reserved" 115 "Reserved" 116 "Reserved" 117 "Reserved" 118 "Reserved" 119 "Reserved" 120 "Reserved" 121 "Reserved" 122 "Reserved" 123 "Reserved" 124 "Reserved" 125 "Reserved" 126 "Reserved" 127 "Reserved" 128 "Reserved" 129 "Reserved" 130 "Reserved" 131 "Reserved" 132 "Reserved" 133 "Reserved" 134 "Reserved" 135 "Reserved" 136 "Reserved" 137 "Reserved" 138 "Reserved" 139 "Reserved" 140 "Reserved" 141 "Reserved" 142 "Reserved" 143 "Reserved" 144 "Reserved" 145 "Reserved" 146 "Reserved" 147 "Reserved" 148 "Reserved" 149 "Reserved" 150 "Reserved" 151 "Reserved" 152 "Reserved" 153 "Reserved" 154 "Reserved" 155 "Reserved" 156 "Reserved" 157 "Reserved" 158 "Reserved" 159 "Reserved" 160 "Reserved" 161 "Reserved" 162 "Reserved" 163 "Reserved" 164 "Reserved" 165 "Reserved" 166 "Reserved" 167 "Reserved" 168 "Reserved" 169 "Reserved" 170 "Reserved" 171 "Reserved" 172 "Reserved" 173 "Reserved" 174 "Reserved" 175 "Reserved" 176 "Reserved" 177 "Reserved" 178 "Reserved" 179 "Reserved" 180 "Reserved" 181 "Reserved" 182 "Reserved" 183 "Reserved" 184 "Reserved" 185 "Reserved" 186 "Reserved" 187 "Reserved" 188 "Reserved" 189 "Reserved" 190 "Reserved" 191 "Reserved" 192 "Reserved" 193 "Reserved" 194 "Reserved" 195 "Reserved" 196 "Reserved" 197 "Reserved" 198 "Reserved" 199 "Reserved" 200 "Reserved" 201 "Reserved" 202 "Reserved" 203 "Reserved" 204 "Reserved" 205 "Reserved" 206 "Reserved" 207 "Reserved" 208 "Reserved" 209 "Reserved" 210 "Reserved" 211 "Reserved" 212 "Reserved" 213 "Reserved" 214 "Reserved" 215 "Reserved" 216 "Reserved" 217 "Reserved" 218 "Reserved" 219 "Reserved" 220 "Reserved" 221 "Reserved" 222 "Reserved" 223 "Reserved" 224 "Reserved" 225 "Reserved" 226 "Reserved" 227 "Reserved" 228 "Reserved" 229 "Reserved" 230 "Reserved" 231 "Reserved" 232 "Reserved" 233 "Reserved" 234 "Reserved" 235 "Reserved" 236 "Reserved" 237 "Reserved" 238 "Reserved" 239 "Reserved" 240 "Reserved" 241 "Reserved" 242 "Reserved" 243 "Reserved" 244 "Reserved" 245 "Reserved" 246 "Reserved" 247 "Reserved" 248 "Reserved" 249 "Reserved" 250 "Reserved" 251 "Reserved" 252 "Reserved" 253 "Reserved" 254 "Reserved" 255 "Reserved" ;
VAL_ 117 VCU_LrngSts 0 "VCU_Virgin" 1 "VCU_Learnt" 2 "Reserved" 3 "Reserved" 4 "Reserved" 5 "Reserved" 6 "Reserved" 7 "Reserved" 8 "Reserved" 9 "Reserved" 10 "Reserved" 11 "Reserved" 12 "Reserved" 13 "Reserved" 14 "Reserved" 15 "Reserved" 16 "Reserved" 17 "Reserved" 18 "Reserved" 19 "Reserved" 20 "Reserved" 21 "Reserved" 22 "Reserved" 23 "Reserved" 24 "Reserved" 25 "Reserved" 26 "Reserved" 27 "Reserved" 28 "Reserved" 29 "Reserved" 30 "Reserved" 31 "Reserved" 32 "Reserved" 33 "Reserved" 34 "Reserved" 35 "Reserved" 36 "Reserved" 37 "Reserved" 38 "Reserved" 39 "Reserved" 40 "Reserved" 41 "Reserved" 42 "Reserved" 43 "Reserved" 44 "Reserved" 45 "Reserved" 46 "Reserved" 47 "Reserved" 48 "Reserved" 49 "Reserved" 50 "Reserved" 51 "Reserved" 52 "Reserved" 53 "Reserved" 54 "Reserved" 55 "Reserved" 56 "Reserved" 57 "Reserved" 58 "Reserved" 59 "Reserved" 60 "Reserved" 61 "Reserved" 62 "Reserved" 63 "Reserved" 64 "Reserved" 65 "Reserved" 66 "Reserved" 67 "Reserved" 68 "Reserved" 69 "Reserved" 70 "Reserved" 71 "Reserved" 72 "Reserved" 73 "Reserved" 74 "Reserved" 75 "Reserved" 76 "Reserved" 77 "Reserved" 78 "Reserved" 79 "Reserved" 80 "Reserved" 81 "Reserved" 82 "Reserved" 83 "Reserved" 84 "Reserved" 85 "Reserved" 86 "Reserved" 87 "Reserved" 88 "Reserved" 89 "Reserved" 90 "Reserved" 91 "Reserved" 92 "Reserved" 93 "Reserved" 94 "Reserved" 95 "Reserved" 96 "Reserved" 97 "Reserved" 98 "Reserved" 99 "Reserved" 100 "Reserved" 101 "Reserved" 102 "Reserved" 103 "Reserved" 104 "Reserved" 105 "Reserved" 106 "Reserved" 107 "Reserved" 108 "Reserved" 109 "Reserved" 110 "Reserved" 111 "Reserved" 112 "Reserved" 113 "Reserved" 114 "Reserved" 115 "Reserved" 116 "Reserved" 117 "Reserved" 118 "Reserved" 119 "Reserved" 120 "Reserved" 121 "Reserved" 122 "Reserved" 123 "Reserved" 124 "Reserved" 125 "Reserved" 126 "Reserved" 127 "Reserved" 128 "Reserved" 129 "Reserved" 130 "Reserved" 131 "Reserved" 132 "Reserved" 133 "Reserved" 134 "Reserved" 135 "Reserved" 136 "Reserved" 137 "Reserved" 138 "Reserved" 139 "Reserved" 140 "Reserved" 141 "Reserved" 142 "Reserved" 143 "Reserved" 144 "Reserved" 145 "Reserved" 146 "Reserved" 147 "Reserved" 148 "Reserved" 149 "Reserved" 150 "Reserved" 151 "Reserved" 152 "Reserved" 153 "Reserved" 154 "Reserved" 155 "Reserved" 156 "Reserved" 157 "Reserved" 158 "Reserved" 159 "Reserved" 160 "Reserved" 161 "Reserved" 162 "Reserved" 163 "Reserved" 164 "Reserved" 165 "Reserved" 166 "Reserved" 167 "Reserved" 168 "Reserved" 169 "Reserved" 170 "Reserved" 171 "Reserved" 172 "Reserved" 173 "Reserved" 174 "Reserved" 175 "Reserved" 176 "Reserved" 177 "Reserved" 178 "Reserved" 179 "Reserved" 180 "Reserved" 181 "Reserved" 182 "Reserved" 183 "Reserved" 184 "Reserved" 185 "Reserved" 186 "Reserved" 187 "Reserved" 188 "Reserved" 189 "Reserved" 190 "Reserved" 191 "Reserved" 192 "Reserved" 193 "Reserved" 194 "Reserved" 195 "Reserved" 196 "Reserved" 197 "Reserved" 198 "Reserved" 199 "Reserved" 200 "Reserved" 201 "Reserved" 202 "Reserved" 203 "Reserved" 204 "Reserved" 205 "Reserved" 206 "Reserved" 207 "Reserved" 208 "Reserved" 209 "Reserved" 210 "Reserved" 211 "Reserved" 212 "Reserved" 213 "Reserved" 214 "Reserved" 215 "Reserved" 216 "Reserved" 217 "Reserved" 218 "Reserved" 219 "Reserved" 220 "Reserved" 221 "Reserved" 222 "Reserved" 223 "Reserved" 224 "Reserved" 225 "Reserved" 226 "Reserved" 227 "Reserved" 228 "Reserved" 229 "Reserved" 230 "Reserved" 231 "Reserved" 232 "Reserved" 233 "Reserved" 234 "Reserved" 235 "Reserved" 236 "Reserved" 237 "Reserved" 238 "Reserved" 239 "Reserved" 240 "Reserved" 241 "Reserved" 242 "Reserved" 243 "Reserved" 244 "Reserved" 245 "Reserved" 246 "Reserved" 247 "Reserved" 248 "Reserved" 249 "Reserved" 250 "Reserved" 251 "Reserved" 252 "Reserved" 253 "Reserved" 254 "Reserved" 255 "Reserved" ;
VAL_ 119 VCU_SUB_ID_77 0 "Reserved" 1 "Report_VCU_Learning_Status" 2 "Share_FF_Of_SKC_And_SC" 3 "Share_SF_Of_SKC_And_SC" 4 "Share_3rdF_Of_SKC_And_SC" 5 "Response_To_Set_Learnt_Command" 6 "Postive_Reply_SC" 7 "Reserved" 8 "Reserved" 9 "Reserved" 10 "Reserved" 11 "Reserved" 12 "Reserved" 13 "Reserved" 14 "Reserved" 15 "Reserved" 16 "Reserved" 17 "Reserved" 18 "Reserved" 19 "Reserved" 20 "Reserved" 21 "Reserved" 22 "Reserved" 23 "Reserved" 24 "Reserved" 25 "Reserved" 26 "Reserved" 27 "Reserved" 28 "Reserved" 29 "Reserved" 30 "Reserved" 31 "Reserved" 32 "Reserved" 33 "Reserved" 34 "Reserved" 35 "Reserved" 36 "Reserved" 37 "Reserved" 38 "Reserved" 39 "Reserved" 40 "Reserved" 41 "Reserved" 42 "Reserved" 43 "Reserved" 44 "Reserved" 45 "Reserved" 46 "Reserved" 47 "Reserved" 48 "Reserved" 49 "Reserved" 50 "Reserved" 51 "Reserved" 52 "Reserved" 53 "Reserved" 54 "Reserved" 55 "Reserved" 56 "Reserved" 57 "Reserved" 58 "Reserved" 59 "Reserved" 60 "Reserved" 61 "Reserved" 62 "Reserved" 63 "Reserved" 64 "Reserved" 65 "Reserved" 66 "Reserved" 67 "Reserved" 68 "Reserved" 69 "Reserved" 70 "Reserved" 71 "Reserved" 72 "Reserved" 73 "Reserved" 74 "Reserved" 75 "Reserved" 76 "Reserved" 77 "Reserved" 78 "Reserved" 79 "Reserved" 80 "Reserved" 81 "Reserved" 82 "Reserved" 83 "Reserved" 84 "Reserved" 85 "Reserved" 86 "Reserved" 87 "Reserved" 88 "Reserved" 89 "Reserved" 90 "Reserved" 91 "Reserved" 92 "Reserved" 93 "Reserved" 94 "Reserved" 95 "Reserved" 96 "Reserved" 97 "Reserved" 98 "Reserved" 99 "Reserved" 100 "Reserved" 101 "Reserved" 102 "Reserved" 103 "Reserved" 104 "Reserved" 105 "Reserved" 106 "Reserved" 107 "Reserved" 108 "Reserved" 109 "Reserved" 110 "Reserved" 111 "Reserved" 112 "Reserved" 113 "Reserved" 114 "Reserved" 115 "Reserved" 116 "Reserved" 117 "Reserved" 118 "Reserved" 119 "Reserved" 120 "Reserved" 121 "Reserved" 122 "Reserved" 123 "Reserved" 124 "Reserved" 125 "Reserved" 126 "Reserved" 127 "Reserved" 128 "Reserved" 129 "Reserved" 130 "Reserved" 131 "Reserved" 132 "Reserved" 133 "Reserved" 134 "Reserved" 135 "Reserved" 136 "Reserved" 137 "Reserved" 138 "Reserved" 139 "Reserved" 140 "Reserved" 141 "Reserved" 142 "Reserved" 143 "Reserved" 144 "Reserved" 145 "Reserved" 146 "Reserved" 147 "Reserved" 148 "Reserved" 149 "Reserved" 150 "Reserved" 151 "Reserved" 152 "Reserved" 153 "Reserved" 154 "Reserved" 155 "Reserved" 156 "Reserved" 157 "Reserved" 158 "Reserved" 159 "Reserved" 160 "Reserved" 161 "Reserved" 162 "Reserved" 163 "Reserved" 164 "Reserved" 165 "Reserved" 166 "Reserved" 167 "Reserved" 168 "Reserved" 169 "Reserved" 170 "Reserved" 171 "Reserved" 172 "Reserved" 173 "Reserved" 174 "Reserved" 175 "Reserved" 176 "Reserved" 177 "Reserved" 178 "Reserved" 179 "Reserved" 180 "Reserved" 181 "Reserved" 182 "Reserved" 183 "Reserved" 184 "Reserved" 185 "Reserved" 186 "Reserved" 187 "Reserved" 188 "Reserved" 189 "Reserved" 190 "Reserved" 191 "Reserved" 192 "Reserved" 193 "Reserved" 194 "Reserved" 195 "Reserved" 196 "Reserved" 197 "Reserved" 198 "Reserved" 199 "Reserved" 200 "Reserved" 201 "Reserved" 202 "Reserved" 203 "Reserved" 204 "Reserved" 205 "Reserved" 206 "Reserved" 207 "Reserved" 208 "Reserved" 209 "Reserved" 210 "Reserved" 211 "Reserved" 212 "Reserved" 213 "Reserved" 214 "Reserved" 215 "Reserved" 216 "Reserved" 217 "Reserved" 218 "Reserved" 219 "Reserved" 220 "Reserved" 221 "Reserved" 222 "Reserved" 223 "Reserved" 224 "Reserved" 225 "Reserved" 226 "Reserved" 227 "Reserved" 228 "Reserved" 229 "Reserved" 230 "Reserved" 231 "Reserved" 232 "Reserved" 233 "Reserved" 234 "Reserved" 235 "Reserved" 236 "Reserved" 237 "Reserved" 238 "Reserved" 239 "Reserved" 240 "Reserved" 241 "Reserved" 242 "Reserved" 243 "Reserved" 244 "Reserved" 245 "Reserved" 246 "Reserved" 247 "Reserved" 248 "Reserved" 249 "Reserved" 250 "Reserved" 251 "Reserved" 252 "Reserved" 253 "Reserved" 254 "Reserved" 255 "Reserved" ;
VAL_ 121 TBOX_LrnFbInfoClassn 0 "Reserved" 1 "Report_TBOX_Learning_Status" 2 "Reserved" 3 "Reserved" 4 "Reserved" 5 "Response_To_Set_Learnt_Command" 6 "Reserved" 7 "Reserved" 8 "Reserved" 9 "Reserved" 10 "Reserved" 11 "Reserved" 12 "Reserved" 13 "Reserved" 14 "Reserved" 15 "Reserved" 16 "Reserved" 17 "Reserved" 18 "Reserved" 19 "Reserved" 20 "Reserved" 21 "Reserved" 22 "Reserved" 23 "Reserved" 24 "Reserved" 25 "Reserved" 26 "Reserved" 27 "Reserved" 28 "Reserved" 29 "Reserved" 30 "Reserved" 31 "Reserved" 32 "Reserved" 33 "Reserved" 34 "Reserved" 35 "Reserved" 36 "Reserved" 37 "Reserved" 38 "Reserved" 39 "Reserved" 40 "Reserved" 41 "Reserved" 42 "Reserved" 43 "Reserved" 44 "Reserved" 45 "Reserved" 46 "Reserved" 47 "Reserved" 48 "Reserved" 49 "Reserved" 50 "Reserved" 51 "Reserved" 52 "Reserved" 53 "Reserved" 54 "Reserved" 55 "Reserved" 56 "Reserved" 57 "Reserved" 58 "Reserved" 59 "Reserved" 60 "Reserved" 61 "Reserved" 62 "Reserved" 63 "Reserved" 64 "Reserved" 65 "Reserved" 66 "Reserved" 67 "Reserved" 68 "Reserved" 69 "Reserved" 70 "Reserved" 71 "Reserved" 72 "Reserved" 73 "Reserved" 74 "Reserved" 75 "Reserved" 76 "Reserved" 77 "Reserved" 78 "Reserved" 79 "Reserved" 80 "Reserved" 81 "Reserved" 82 "Reserved" 83 "Reserved" 84 "Reserved" 85 "Reserved" 86 "Reserved" 87 "Reserved" 88 "Reserved" 89 "Reserved" 90 "Reserved" 91 "Reserved" 92 "Reserved" 93 "Reserved" 94 "Reserved" 95 "Reserved" 96 "Reserved" 97 "Reserved" 98 "Reserved" 99 "Reserved" 100 "Reserved" 101 "Reserved" 102 "Reserved" 103 "Reserved" 104 "Reserved" 105 "Reserved" 106 "Reserved" 107 "Reserved" 108 "Reserved" 109 "Reserved" 110 "Reserved" 111 "Reserved" 112 "Reserved" 113 "Reserved" 114 "Reserved" 115 "Reserved" 116 "Reserved" 117 "Reserved" 118 "Reserved" 119 "Reserved" 120 "Reserved" 121 "Reserved" 122 "Reserved" 123 "Reserved" 124 "Reserved" 125 "Reserved" 126 "Reserved" 127 "Reserved" 128 "Reserved" 129 "Reserved" 130 "Reserved" 131 "Reserved" 132 "Reserved" 133 "Reserved" 134 "Reserved" 135 "Reserved" 136 "Reserved" 137 "Reserved" 138 "Reserved" 139 "Reserved" 140 "Reserved" 141 "Reserved" 142 "Reserved" 143 "Reserved" 144 "Reserved" 145 "Reserved" 146 "Reserved" 147 "Reserved" 148 "Reserved" 149 "Reserved" 150 "Reserved" 151 "Reserved" 152 "Reserved" 153 "Reserved" 154 "Reserved" 155 "Reserved" 156 "Reserved" 157 "Reserved" 158 "Reserved" 159 "Reserved" 160 "Reserved" 161 "Reserved" 162 "Reserved" 163 "Reserved" 164 "Reserved" 165 "Reserved" 166 "Reserved" 167 "Reserved" 168 "Reserved" 169 "Reserved" 170 "Reserved" 171 "Reserved" 172 "Reserved" 173 "Reserved" 174 "Reserved" 175 "Reserved" 176 "Reserved" 177 "Reserved" 178 "Reserved" 179 "Reserved" 180 "Reserved" 181 "Reserved" 182 "Reserved" 183 "Reserved" 184 "Reserved" 185 "Reserved" 186 "Reserved" 187 "Reserved" 188 "Reserved" 189 "Reserved" 190 "Reserved" 191 "Reserved" 192 "Reserved" 193 "Reserved" 194 "Reserved" 195 "Reserved" 196 "Reserved" 197 "Reserved" 198 "Reserved" 199 "Reserved" 200 "Reserved" 201 "Reserved" 202 "Reserved" 203 "Reserved" 204 "Reserved" 205 "Reserved" 206 "Reserved" 207 "Reserved" 208 "Reserved" 209 "Reserved" 210 "Reserved" 211 "Reserved" 212 "Reserved" 213 "Reserved" 214 "Reserved" 215 "Reserved" 216 "Reserved" 217 "Reserved" 218 "Reserved" 219 "Reserved" 220 "Reserved" 221 "Reserved" 222 "Reserved" 223 "Reserved" 224 "Reserved" 225 "Reserved" 226 "Reserved" 227 "Reserved" 228 "Reserved" 229 "Reserved" 230 "Reserved" 231 "Reserved" 232 "Reserved" 233 "Reserved" 234 "Reserved" 235 "Reserved" 236 "Reserved" 237 "Reserved" 238 "Reserved" 239 "Reserved" 240 "Reserved" 241 "Reserved" 242 "Reserved" 243 "Reserved" 244 "Reserved" 245 "Reserved" 246 "Reserved" 247 "Reserved" 248 "Reserved" 249 "Reserved" 250 "Reserved" 251 "Reserved" 252 "Reserved" 253 "Reserved" 254 "Reserved" 255 "Reserved" ;
VAL_ 121 TBOX_LrngSts 0 "TBOX_Virgin" 1 "TBOX_Learnt" 2 "Reserved" 3 "Reserved" 4 "Reserved" 5 "Reserved" 6 "Reserved" 7 "Reserved" 8 "Reserved" 9 "Reserved" 10 "Reserved" 11 "Reserved" 12 "Reserved" 13 "Reserved" 14 "Reserved" 15 "Reserved" 16 "Reserved" 17 "Reserved" 18 "Reserved" 19 "Reserved" 20 "Reserved" 21 "Reserved" 22 "Reserved" 23 "Reserved" 24 "Reserved" 25 "Reserved" 26 "Reserved" 27 "Reserved" 28 "Reserved" 29 "Reserved" 30 "Reserved" 31 "Reserved" 32 "Reserved" 33 "Reserved" 34 "Reserved" 35 "Reserved" 36 "Reserved" 37 "Reserved" 38 "Reserved" 39 "Reserved" 40 "Reserved" 41 "Reserved" 42 "Reserved" 43 "Reserved" 44 "Reserved" 45 "Reserved" 46 "Reserved" 47 "Reserved" 48 "Reserved" 49 "Reserved" 50 "Reserved" 51 "Reserved" 52 "Reserved" 53 "Reserved" 54 "Reserved" 55 "Reserved" 56 "Reserved" 57 "Reserved" 58 "Reserved" 59 "Reserved" 60 "Reserved" 61 "Reserved" 62 "Reserved" 63 "Reserved" 64 "Reserved" 65 "Reserved" 66 "Reserved" 67 "Reserved" 68 "Reserved" 69 "Reserved" 70 "Reserved" 71 "Reserved" 72 "Reserved" 73 "Reserved" 74 "Reserved" 75 "Reserved" 76 "Reserved" 77 "Reserved" 78 "Reserved" 79 "Reserved" 80 "Reserved" 81 "Reserved" 82 "Reserved" 83 "Reserved" 84 "Reserved" 85 "Reserved" 86 "Reserved" 87 "Reserved" 88 "Reserved" 89 "Reserved" 90 "Reserved" 91 "Reserved" 92 "Reserved" 93 "Reserved" 94 "Reserved" 95 "Reserved" 96 "Reserved" 97 "Reserved" 98 "Reserved" 99 "Reserved" 100 "Reserved" 101 "Reserved" 102 "Reserved" 103 "Reserved" 104 "Reserved" 105 "Reserved" 106 "Reserved" 107 "Reserved" 108 "Reserved" 109 "Reserved" 110 "Reserved" 111 "Reserved" 112 "Reserved" 113 "Reserved" 114 "Reserved" 115 "Reserved" 116 "Reserved" 117 "Reserved" 118 "Reserved" 119 "Reserved" 120 "Reserved" 121 "Reserved" 122 "Reserved" 123 "Reserved" 124 "Reserved" 125 "Reserved" 126 "Reserved" 127 "Reserved" 128 "Reserved" 129 "Reserved" 130 "Reserved" 131 "Reserved" 132 "Reserved" 133 "Reserved" 134 "Reserved" 135 "Reserved" 136 "Reserved" 137 "Reserved" 138 "Reserved" 139 "Reserved" 140 "Reserved" 141 "Reserved" 142 "Reserved" 143 "Reserved" 144 "Reserved" 145 "Reserved" 146 "Reserved" 147 "Reserved" 148 "Reserved" 149 "Reserved" 150 "Reserved" 151 "Reserved" 152 "Reserved" 153 "Reserved" 154 "Reserved" 155 "Reserved" 156 "Reserved" 157 "Reserved" 158 "Reserved" 159 "Reserved" 160 "Reserved" 161 "Reserved" 162 "Reserved" 163 "Reserved" 164 "Reserved" 165 "Reserved" 166 "Reserved" 167 "Reserved" 168 "Reserved" 169 "Reserved" 170 "Reserved" 171 "Reserved" 172 "Reserved" 173 "Reserved" 174 "Reserved" 175 "Reserved" 176 "Reserved" 177 "Reserved" 178 "Reserved" 179 "Reserved" 180 "Reserved" 181 "Reserved" 182 "Reserved" 183 "Reserved" 184 "Reserved" 185 "Reserved" 186 "Reserved" 187 "Reserved" 188 "Reserved" 189 "Reserved" 190 "Reserved" 191 "Reserved" 192 "Reserved" 193 "Reserved" 194 "Reserved" 195 "Reserved" 196 "Reserved" 197 "Reserved" 198 "Reserved" 199 "Reserved" 200 "Reserved" 201 "Reserved" 202 "Reserved" 203 "Reserved" 204 "Reserved" 205 "Reserved" 206 "Reserved" 207 "Reserved" 208 "Reserved" 209 "Reserved" 210 "Reserved" 211 "Reserved" 212 "Reserved" 213 "Reserved" 214 "Reserved" 215 "Reserved" 216 "Reserved" 217 "Reserved" 218 "Reserved" 219 "Reserved" 220 "Reserved" 221 "Reserved" 222 "Reserved" 223 "Reserved" 224 "Reserved" 225 "Reserved" 226 "Reserved" 227 "Reserved" 228 "Reserved" 229 "Reserved" 230 "Reserved" 231 "Reserved" 232 "Reserved" 233 "Reserved" 234 "Reserved" 235 "Reserved" 236 "Reserved" 237 "Reserved" 238 "Reserved" 239 "Reserved" 240 "Reserved" 241 "Reserved" 242 "Reserved" 243 "Reserved" 244 "Reserved" 245 "Reserved" 246 "Reserved" 247 "Reserved" 248 "Reserved" 249 "Reserved" 250 "Reserved" 251 "Reserved" 252 "Reserved" 253 "Reserved" 254 "Reserved" 255 "Reserved" ;
VAL_ 122 TBOX_LrngSubID_7A 0 "Reserved" 1 "Report_TBOX_LearningST" 2 "Share_FF_Of_SKC_And_SC" 3 "Share_SF_Of_SKC_And_SC" 4 "Share_3rd_F_Of_SKC_And_SC" 5 "Response_To_Set_Learnt_Command" 6 "Postive_Reply_SC" 7 "Reserved" 8 "Reserved" 9 "Reserved" 10 "Reserved" 11 "Reserved" 12 "Reserved" 13 "Reserved" 14 "Reserved" 15 "Reserved" 16 "Reserved" 17 "Reserved" 18 "Reserved" 19 "Reserved" 20 "Reserved" 21 "Reserved" 22 "Reserved" 23 "Reserved" 24 "Reserved" 25 "Reserved" 26 "Reserved" 27 "Reserved" 28 "Reserved" 29 "Reserved" 30 "Reserved" 31 "Reserved" 32 "Reserved" 33 "Reserved" 34 "Reserved" 35 "Reserved" 36 "Reserved" 37 "Reserved" 38 "Reserved" 39 "Reserved" 40 "Reserved" 41 "Reserved" 42 "Reserved" 43 "Reserved" 44 "Reserved" 45 "Reserved" 46 "Reserved" 47 "Reserved" 48 "Reserved" 49 "Reserved" 50 "Reserved" 51 "Reserved" 52 "Reserved" 53 "Reserved" 54 "Reserved" 55 "Reserved" 56 "Reserved" 57 "Reserved" 58 "Reserved" 59 "Reserved" 60 "Reserved" 61 "Reserved" 62 "Reserved" 63 "Reserved" 64 "Reserved" 65 "Reserved" 66 "Reserved" 67 "Reserved" 68 "Reserved" 69 "Reserved" 70 "Reserved" 71 "Reserved" 72 "Reserved" 73 "Reserved" 74 "Reserved" 75 "Reserved" 76 "Reserved" 77 "Reserved" 78 "Reserved" 79 "Reserved" 80 "Reserved" 81 "Reserved" 82 "Reserved" 83 "Reserved" 84 "Reserved" 85 "Reserved" 86 "Reserved" 87 "Reserved" 88 "Reserved" 89 "Reserved" 90 "Reserved" 91 "Reserved" 92 "Reserved" 93 "Reserved" 94 "Reserved" 95 "Reserved" 96 "Reserved" 97 "Reserved" 98 "Reserved" 99 "Reserved" 100 "Reserved" 101 "Reserved" 102 "Reserved" 103 "Reserved" 104 "Reserved" 105 "Reserved" 106 "Reserved" 107 "Reserved" 108 "Reserved" 109 "Reserved" 110 "Reserved" 111 "Reserved" 112 "Reserved" 113 "Reserved" 114 "Reserved" 115 "Reserved" 116 "Reserved" 117 "Reserved" 118 "Reserved" 119 "Reserved" 120 "Reserved" 121 "Reserved" 122 "Reserved" 123 "Reserved" 124 "Reserved" 125 "Reserved" 126 "Reserved" 127 "Reserved" 128 "Reserved" 129 "Reserved" 130 "Reserved" 131 "Reserved" 132 "Reserved" 133 "Reserved" 134 "Reserved" 135 "Reserved" 136 "Reserved" 137 "Reserved" 138 "Reserved" 139 "Reserved" 140 "Reserved" 141 "Reserved" 142 "Reserved" 143 "Reserved" 144 "Reserved" 145 "Reserved" 146 "Reserved" 147 "Reserved" 148 "Reserved" 149 "Reserved" 150 "Reserved" 151 "Reserved" 152 "Reserved" 153 "Reserved" 154 "Reserved" 155 "Reserved" 156 "Reserved" 157 "Reserved" 158 "Reserved" 159 "Reserved" 160 "Reserved" 161 "Reserved" 162 "Reserved" 163 "Reserved" 164 "Reserved" 165 "Reserved" 166 "Reserved" 167 "Reserved" 168 "Reserved" 169 "Reserved" 170 "Reserved" 171 "Reserved" 172 "Reserved" 173 "Reserved" 174 "Reserved" 175 "Reserved" 176 "Reserved" 177 "Reserved" 178 "Reserved" 179 "Reserved" 180 "Reserved" 181 "Reserved" 182 "Reserved" 183 "Reserved" 184 "Reserved" 185 "Reserved" 186 "Reserved" 187 "Reserved" 188 "Reserved" 189 "Reserved" 190 "Reserved" 191 "Reserved" 192 "Reserved" 193 "Reserved" 194 "Reserved" 195 "Reserved" 196 "Reserved" 197 "Reserved" 198 "Reserved" 199 "Reserved" 200 "Reserved" 201 "Reserved" 202 "Reserved" 203 "Reserved" 204 "Reserved" 205 "Reserved" 206 "Reserved" 207 "Reserved" 208 "Reserved" 209 "Reserved" 210 "Reserved" 211 "Reserved" 212 "Reserved" 213 "Reserved" 214 "Reserved" 215 "Reserved" 216 "Reserved" 217 "Reserved" 218 "Reserved" 219 "Reserved" 220 "Reserved" 221 "Reserved" 222 "Reserved" 223 "Reserved" 224 "Reserved" 225 "Reserved" 226 "Reserved" 227 "Reserved" 228 "Reserved" 229 "Reserved" 230 "Reserved" 231 "Reserved" 232 "Reserved" 233 "Reserved" 234 "Reserved" 235 "Reserved" 236 "Reserved" 237 "Reserved" 238 "Reserved" 239 "Reserved" 240 "Reserved" 241 "Reserved" 242 "Reserved" 243 "Reserved" 244 "Reserved" 245 "Reserved" 246 "Reserved" 247 "Reserved" 248 "Reserved" 249 "Reserved" 250 "Reserved" 251 "Reserved" 252 "Reserved" 253 "Reserved" 254 "Reserved" 255 "Reserved" ;
VAL_ 147 VCU_93_AliveCounter 0 "NotActive" 1 "Active" ;
VAL_ 147 VCU_EmgyShutOff 0 "NotActive" 1 "Active" ;
VAL_ 147 VCU_IsolationMonitor_Rq 0 "NotActive" 1 "Active" ;
VAL_ 147 VCU_Set_Chrg_Mod 0 "Undefined" 1 "NO_Charging_NoChargerisConnected" 2 "AC_Charging_ACChargerisActive" 3 "DC_Charging_DCChargerisConnected" ;
VAL_ 147 VCU_Set_BMS_Mod 0 "Undefined(SignalValueUndefined)" 1 "BMS_ActiveSet_BMStoActiveMode_WhereitisAWakeAndOperating" 2 "BMS_SLEEP_SetBMStoSleepMode" 3 "Reserved" ;
VAL_ 147 VCU_HVBActivateDeactivateRq 0 "Undefined_SignalValueUndefined" 1 "HV_Off_BatteryShouldbeDisConnected" 2 "HV_ON_BatteryShouldbeConnected" ;
VAL_ 147 VCU_Set_Balc_Mod 0 "Undefined" 1 "BALANCING_Off_BalancingisforbiddenByVCU" 2 "BALANCING_ON_BalancingisallowedByVCU" ;
VAL_ 235 BMS_ErrorWarning_OverChargeCurre 0 "WarningNotActive" 1 "Warning" ;
VAL_ 235 BMS_ErrorActive_OverChargeCurren 0 "ErrorNotActive" 1 "Error" ;
VAL_ 235 BMS_ErrorWarning_OverDischargeCu 0 "WarningNotActive" 1 "Warning" ;
VAL_ 235 BMS_ErrorActive_OverDischargeCur 0 "ErrorNotActive" 1 "Error" ;
VAL_ 235 BMS_ErrorWarning_ChargePowerLimi 0 "WarningNotActive" 1 "Warning" ;
VAL_ 235 BMS_ErrorActive_ChargePowerLimit 0 "ErrorNotActive" 1 "Error" ;
VAL_ 235 BMS_ErrorWarning_DischargePowerL 0 "WarningNotActive" 1 "Warning" ;
VAL_ 235 BMS_ErrorActive_DischargePowerLi 0 "ErrorNotActive" 1 "Error" ;
VAL_ 235 BMS_ErrorWarning_SOC_Low 0 "WarningNotActive" 1 "Warning" ;
VAL_ 235 BMS_ErrorActive_SOC_Low 0 "ErrorNotActive" 1 "Error" ;
VAL_ 235 BMS_ErrorWarning_Iso 0 "WarningNotActive" 1 "Warning" ;
VAL_ 235 BMS_ErrorActive_Iso_Crit 0 "ErrorNotActive" 1 "Error" ;
VAL_ 235 BMS_ErrorActive_AbsChargeCurrent 0 "ErrorNotActive" 1 "Error" ;
VAL_ 235 BMS_ErrorActive_AbsDischargeCurr 0 "ErrorNotActive" 1 "Error" ;
VAL_ 235 BMS_ErrorActive_AbsChargePowerLi 0 "ErrorNotActive" 1 "Error" ;
VAL_ 235 BMS_ErrorActive_AbsDischargePowe 0 "ErrorNotActive" 1 "Error" ;
VAL_ 235 BMS_ErrorWarning_overcurrent_Pre 0 "WarningNotActive" 1 "Warning" ;
VAL_ 235 BMS_ErrorActive_ServState 0 "ErrorNotActive" 1 "Error" ;
VAL_ 235 BMS_SystemError_KL30C 0 "ErrorNotActive" 1 "Error" ;
VAL_ 235 BMS_SystemError_OmmissionOfKL15 0 "ErrorNotActive" 1 "Error" ;
VAL_ 235 BMS_SystemError_HV_Interlock 0 "ErrorNotActive" 1 "Error" ;
VAL_ 235 BMS_SystemError_HV_Fuse 0 "ErrorNotActive" 1 "Error" ;
VAL_ 235 BMS_CommError_CommFailure 0 "ErrorNotActive" 1 "Error" ;
VAL_ 235 BMS_CommWarning_PEC_High 0 "WarningNotActive" 1 "Warning" ;
VAL_ 235 BMS_CommError_PEC_High 0 "ErrorNotActive" 1 "Error" ;
VAL_ 235 BMS_HVlinkError_VCU_Comm_Failure 0 "ErrorNotActive" 1 "Error" ;
VAL_ 235 BMS_HVlinkError_Iso_Dev 0 "ErrorNotActive" 1 "Error" ;
VAL_ 235 BMS_HVlinkError_Iso_Dig_Sig 0 "ErrorNotActive" 1 "Error" ;
VAL_ 235 BMS_HVlinkError_ContactorWelded 0 "ErrorNotActive" 1 "Error" ;
VAL_ 235 BMS_HVlinkError_HV_Interlock_Bad 0 "ErrorNotActive" 1 "Error" ;
VAL_ 235 BMS_HardwareError_LCM_General_Fa 0 "ErrorNotActive" 1 "Error" ;
VAL_ 235 BMS_SoftwareError_General_Failr 0 "ErrorNotActive" 1 "Error" ;
VAL_ 235 BMS_ErrorWarning_CellOverVoltage 0 "WarningNotActive" 1 "Warning" ;
VAL_ 235 BMS_ErrorActive_CellOverVoltage 0 "ErrorNotActive" 1 "Error" ;
VAL_ 235 BMS_ErrorWarning_CellUnderVoltag 0 "WarningNotActive" 1 "Warning" ;
VAL_ 235 BMS_ErrorActive_CellUnderVoltage 0 "ErrorNotActive" 1 "Error" ;
VAL_ 235 BMS_ErrorWarning_CellTempHigh 0 "WarningNotActive" 1 "Warning" ;
VAL_ 235 BMS_ErrorActive_CellTempHigh 0 "ErrorNotActive" 1 "Error" ;
VAL_ 235 BMS_ErrorWarning_CellTempLow 0 "WarningNotActive" 1 "Warning" ;
VAL_ 235 BMS_ErrorActive_CellTempLow 0 "ErrorNotActive" 1 "Error" ;
VAL_ 235 BMS_ErrorWarning_HV_OverVoltage 0 "WarningNotActive" 1 "Warning" ;
VAL_ 235 BMS_ErrorActive_HV_OverVoltage 0 "ErrorNotActive" 1 "Error" ;
VAL_ 235 BMS_ErrorWarning_HV_UnderVoltage 0 "WarningNotActive" 1 "Warning" ;
VAL_ 235 BMS_ErrorActive_HV_UnderVoltage 0 "ErrorNotActive" 1 "Error" ;
VAL_ 235 BMS_PVIU_CANcommError 0 "ErrorNotActive" 1 "Error" ;
VAL_ 237 BMS_OperationStates 0 "BMS_Undefined" 1 "BMS_BOOT" 2 "BMS_PRE_OperatIONAL" 3 "BMS_OperatIONAL" 4 "BMS_PRE_SLEEP" 5 "BMS_Config" ;
VAL_ 237 BMS_BallancingStatus 0 "BMS_BALC_DEActivATED" 1 "BMS_BALC_IDLE" 2 "BMS_BALC_Start" 3 "BMS_BALC_OperatIONAL" 4 "BMS_BALC_STOP" 5 "BMS_BALC_RELAXATION" 15 "BMS_BALC_Undefined" ;
VAL_ 237 BMS_ErrorCategory_CAT0 0 "CATOK" 1 "CATFailure" ;
VAL_ 237 BMS_ErrorCategory_CAT1 0 "CATOK" 1 "CATFailure" ;
VAL_ 237 BMS_ErrorCategory_CAT2 0 "CATOK" 1 "CATFailure" ;
VAL_ 237 BMS_ErrorCategory_CAT3 0 "CATOK" 1 "CATFailure" ;
VAL_ 237 BMS_ErrorCategory_CAT4 0 "CATOK" 1 "CATFailure" ;
VAL_ 237 BMS_ErrorCategory_CAT5 0 "CATOK" 1 "CATFailure" ;
VAL_ 237 BMS_ErrorCategory_CAT6 0 "CATOK" 1 "CATFailure" ;
VAL_ 237 BMS_ErrorCategory_CAT7 0 "CATOK" 1 "CATFailure" ;
VAL_ 237 BMS_ErrorCategory_CAT8 0 "CATOK" 1 "CATFailure" ;
VAL_ 237 BMS_HardwareStatus_OK 0 "InitFail" 1 "OK" ;
VAL_ 237 BMS_ErrorCategory_Mem_Empty 0 "InitFail" 1 "OK" ;
VAL_ 237 BMS_ConfigurationStatus_OK 0 "InitFail" 1 "OK" ;
VAL_ 237 BMS_MeasurementModules_OK 0 "InitFail" 1 "OK" ;
VAL_ 237 BMS_BatteryGeneralStatus_OK 0 "InitFail" 1 "OK" ;
VAL_ 237 BMS_SDIL_Sts 0 "Off" 1 "On" ;
VAL_ 237 BMS_CL30C_Sts 0 "Off" 1 "On" ;
VAL_ 237 BMS_CL15_Sts 0 "Off" 1 "On" ;
VAL_ 237 BMS_HVIL_OK 0 "InitFail" 1 "OK" ;
VAL_ 237 BMS_HV_ContactorsStatus_OK 0 "InitFail" 1 "OK" ;
VAL_ 237 BMS_SW_Status_OK 0 "InitFail" 1 "OK" ;
VAL_ 237 BMS_CurrentSensor_OK 0 "InitFail" 1 "OK" ;
VAL_ 237 BMS_IsolatoinStatus_OK 0 "InitFail" 1 "OK" ;
VAL_ 237 BMS_StateMAchine_Status 1 "not_used" 2 "BMS_initializing" 3 "BMS_Standby" 4 "BMS_precharging" 5 "HV_active" 6 "not_used" 7 "BMS_HV_OFF_Emergency" 8 "BMS_shutdown" 9 "not_used" 10 "not_used" 11 "not_used" ;
VAL_ 237 BMS_BDU_Status 1 "not_used" 2 "BMS_initializing" 3 "BMS_Standby" 4 "BMS_precharging" 5 "HV_active" 6 "not_used" 7 "BMS_HV_OFF_Emergency" 8 "BMS_shutdown" 9 "not_used" 10 "not_used" 11 "not_used" ;
VAL_ 242 BMS_CL30C_Volt 65535 "Invalid" ;
VAL_ 276 ESP_OTARdy_Fb 0 "Initial" 1 "Ready" 2 "Not_Ready" 3 "Invalid" ;
VAL_ 276 ESP_FltIndcn_DTC 0 "No_Fault" 1 "Fault" ;
VAL_ 276 ESP_ActvSig_VDC 0 "ESP_Standby" 1 "ESP_Actually_Operating" ;
VAL_ 276 ESP_ActvSig_TCS 0 "TCS_Standby" 1 "TCS_Actually_Operating" ;
VAL_ 276 ESP_ActvSig_EBD 0 "EBD_Not_Active" 1 "EBD_Active" ;
VAL_ 276 ESP_ActvSig_DTC 0 "DTC_Not_Active" 1 "DTC_Active" ;
VAL_ 276 ESP_WarningOn 0 "No_Request" 1 "Yellow_Lamp_Request" 2 "Red_Lamp_Request" 3 "Reserved" ;
VAL_ 276 ESP_Actvndcn_CDD 0 "Not_Active" 1 "Active" ;
VAL_ 276 ESP_FltIndcn_CDD 0 "Available" 1 "Not_Available" ;
VAL_ 276 ESP_ActvIndcn_ABA 0 "Not_Active" 1 "Active" ;
VAL_ 276 ESP_FltIndcn_ABA 0 "Available" 1 "Not_Available" ;
VAL_ 276 ESP_ActvIndcn_ABP 0 "Not_Active" 1 "Active" ;
VAL_ 276 ESP_FltIndcn_ABP 0 "Available" 1 "Not_Available" ;
VAL_ 276 ESP_ActvIndcn_AEB 0 "Not_Active" 1 "Active" ;
VAL_ 276 ESP_FltIndcn_AEB 0 "Available" 1 "Not_Available" ;
VAL_ 276 ESP_ActvIndcn_AWB 0 "Not_Active" 1 "Active" ;
VAL_ 276 ESP_FltIndcn_AWB 0 "Available" 1 "Not_Available" ;
VAL_ 276 ESP_VehStandstillIndcn 0 "Not_Standstill" 1 "Standstill" 2 "Invalid" 3 "Reserved" ;
VAL_ 276 ESP_BrkOverTIndcn 0 "Not_High" 1 "Temp_Too_High" ;
VAL_ 276 ESP_FltIndcn_VDC 0 "No_Fault" 1 "Fault" ;
VAL_ 276 ESP_ActvIndcn_CDD_AP 0 "Not_Active" 1 "Active" ;
VAL_ 276 ESP_FltIndcn_CDD_AP 0 "No_Error" 1 "Error" ;
VAL_ 336 MCU_F_CrtTqVld 0 "Initializing" 1 "Valid" 2 "Invalid" 3 "Reserved" ;
VAL_ 336 MCU_F_CrtRotDir 0 "Standstill" 1 "Forward_rotation_(forward_mode)" 2 "Reverse_(reverse_mode)" 3 "Invalid" ;
VAL_ 336 MCU_F_CrtSpd 65535 "Invalid" ;
VAL_ 336 MCU_F_CrtTq 2047 "Invalid" ;
VAL_ 336 MCU_F_CrtSpdSigVld 0 "Initializing" 1 "Valid" 2 "Invalid" 3 "Reserved" ;
VAL_ 336 MCU_F_CrtMod 0 "Initialization_(function)" 1 "LV_ready" 2 "Standby" 3 "reserved" 4 "Torque_mode" 5 "Speed_control" 6 "reserved" 7 "Internal_inverter_error" 8 "reserved" 9 "Service_job" 10 "Postrun:" 11 "Sleep_Ready" 12 "Reserved" 13 "Reserved" 14 "Init_(dbc_init_value)" 15 "Invalid" ;
VAL_ 336 MCU_F_HVActvDchaSts 0 "Not_discharged" 1 "Discharging" 2 "Discharge_complete" 3 "Discharge_failure" 4 "Reserved" 5 "Reserved" 6 "Init_(dbc_init_value)" 7 "Invalid" ;
VAL_ 336 MCU_F_SlipCtrlActMode 0 "Slip_control_deactivated" 1 "Slip_control_idling" 2 "Slip_control_working" 3 "Fault" ;
VAL_ 336 MCU_F_AlrmLamp_FS 0 "Disable" 1 "Enable" ;
VAL_ 336 MCU_F_HVChkEndFlg 0 "Not_completed" 1 "Completed" ;
VAL_ 337 MCU_R_CrtTqVld 0 "Initializing" 1 "Valid" 2 "Invalid" 3 "Reserved" ;
VAL_ 337 MCU_R_CrtRotDir 0 "Standstill" 1 "Forward_rotation_(forward_mode)" 2 "Reverse_(reverse_mode)" 3 "Invalid" ;
VAL_ 337 MCU_R_CrtSpd 65535 "Invalid" ;
VAL_ 337 MCU_R_CrtTq 2047 "Invalid" ;
VAL_ 337 MCU_R_CrtSpdSigVld 0 "Initializing" 1 "Valid" 2 "Invalid" 3 "Reserved" ;
VAL_ 337 MCU_R_CrtMod 0 "Initialization_(function)" 1 "LV_ready" 2 "Standby" 3 "reserved" 4 "Torque_mode" 5 "Speed_control" 6 "reserved" 7 "Internal_inverter_error" 8 "reserved" 9 "Service_job" 10 "Postrun:" 11 "Sleep_Ready" 12 "Reserved" 13 "Reserved" 14 "Init_(dbc_init_value)" 15 "Invalid" ;
VAL_ 337 MCU_R_Decoup_State 0 "Init" 1 "Disconnect" 2 "Connect_in_progress" 3 "Synchronized" 4 "Connected" 5 "Disconnect_in_progress" 6 "Fault_disconnected" 7 "Fault_connected" 8 "Fault_connect_state_unknown" 9 "Connect_conditions_not_fulfilled" ;
VAL_ 337 MCU_R_HVActvDchaSts 0 "Not_discharged" 1 "Discharging" 2 "Discharge_complete" 3 "Discharge_failure" 4 "Reserved" 5 "Reserved" 6 "Init_(dbc_init_value)" 7 "Invalid" ;
VAL_ 337 MCU_R_SlipCtrlActMode 0 "Slip_control_deactivated" 1 "Slip_control_idling" 2 "Slip_control_working" 3 "Fault" ;
VAL_ 337 MCU_R_AlrmLamp_FS 0 "Disable" 1 "Enable" ;
VAL_ 337 MCU_R_HVChkEndFlg 0 "Not_completed" 1 "Completed" ;
VAL_ 345 ACU_Pass_OCS_St 0 "Seat_not_occupied" 1 "Seat_occupied" 2 "Fault" 3 "Invalid" ;
VAL_ 345 ACU_AirBagSysAlrmLampSts 0 "Warning_lamp_off" 1 "Warning_lamp_on" 2 "Warning_lamp_blinking" 3 "Invalid" ;
VAL_ 345 ACU_Pass_Airbag_LED 0 "LED_1_2_OFF/OFF" 1 "LED_1_2_ON/OFF" 2 "LED_1_2_OFF/ON" 3 "LED_1_2_ON/ON" 4 "LED_1_2_Blinking" 5 "not_used" 6 "not_used" 7 "Invalid" ;
VAL_ 345 ACU_Drvr_Occpt_St 0 "Seat_not_occupied" 1 "Seat_occupied" 2 "Fault" 3 "invalid" ;
VAL_ 345 ACU_BucSwtStFrntDrvr 0 "Buckled" 1 "Not_Buckled" 2 "Fault" 3 "Invalid" ;
VAL_ 345 ACU_BucSwtStFrntPass 0 "Buckled" 1 "Not_Buckled" 2 "Fault" 3 "Invalid" ;
VAL_ 345 ACU_SeatTrkPosnSwtFrntDrvr 0 "Seat_not_formost_position" 1 "Seat_formost_position" 2 "Fault" 3 "Invalid" ;
VAL_ 345 ACU_SeatTrkPosnSwtFrntPass 0 "Seat_not_formost_position" 1 "Seat_formost_position" 2 "Fault" 3 "Invalid" ;
VAL_ 393 CIM_PBtnSts1 0 "P-Button1_not_pressed" 1 "P-Button1_pressed" 2 "Reserved" 3 "Reserved" ;
VAL_ 393 CIM_PBtnSts2 0 "P-Button2_not_pressed" 1 "P-Button2_pressed" 2 "Reserved" 3 "Reserved" ;
VAL_ 393 CIM_PBtnVld 0 "P_button_invalid" 1 "P_button_valid" ;
VAL_ 393 CIM_GearLvrCrtPosnInfo 0 "Gear_Lever_neutral_position_(N)" 1 "Gear_Lever_Counter_Clockwise_1st_dyn_point_-_NR" 2 "Gear_Lever_Counter_Clockwise_2nd_dyn_point_-_R" 3 "Gear_Lever_Clockwise_1st_dyn_point_-_ND" 4 "Gear_Lever_Clockwise_2nd_dyn_point_-_D" 5 "Reserved" 6 "Reserved" 7 "Sensors_fault_sensor_fault" ;
VAL_ 393 CIM_GearleverFltSts 0 "No_fault" 1 "Controller_fault" 2 "Reserved" 3 "Invalid" ;
VAL_ 393 CIM_OTARdy_Fb 0 "Initial" 1 "Ready" 2 "Not_Ready" 3 "Invalid" ;
VAL_ 425 ECC_VCU_ReqChgPwrLim 0 "No_Request" 1 "Req_increase" 2 "Req_decrease" 7 "SNV" ;
VAL_ 425 ECC_OTARdy_Fb 0 "Initial" 1 "Ready" 2 "Not_Ready" 3 "Invalid" ;
VAL_ 438 PKC_TpMnvrCancel 0 "Reserved" 1 "Cancel_request" 2 "Request_not_canceled" 3 "Invalid" ;
VAL_ 438 PKC_TpActDeactInp 0 "Reserved" 1 "Activation" 2 "Deactivation" 3 "Invalid" ;
VAL_ 438 PKC_RemPwrOnOffReq 0 "Invalid" 1 "Power_on" 2 "Power_off" 3 "Reserved" ;
VAL_ 438 PKC_RemDrvgReq 0 "Standby" 1 "Forward" 2 "Reverse" 3 "Turn_left" 4 "Right_turn" 5 "Turn_left" 6 "Forward_right" 7 "Backward_turn_left" 8 "Reverse:Turn_right" 9 "Steering_returnability" 10 "Reserved" 11 "Reserved" 12 "Reserved" 13 "Reserved" 14 "Reserved" 15 "Reserved" ;
VAL_ 438 PKC_RemChrgDchaGunUnlckCmd 0 "Initial_value" 1 "Not_unlocked" 2 "Unlocking" 3 "No_demand" ;
VAL_ 438 PKC_BLE_Online 0 "Not_on_line" 1 "On_line" ;
VAL_ 438 PKC_DviceRngeDist 0 "None" 1 "3_meters_or_less" 2 "Between_3_and_6_meters" 3 "More_than_6_meters" ;
VAL_ 438 PKC_MnvreEnblInput 0 "Not_Pressed" 1 "Pressed_Forward" 2 "Pressed_Backward" 3 "Invalid" ;
VAL_ 438 PKC_RapActDeactInp 0 "Reserved" 1 "Activation" 2 "Deactivation" 3 "Invalid" ;
VAL_ 438 PKC_MnvrRemsumeKey 0 "None" 1 "Not_Pressed" 2 "Pressed" 3 "Reserved" ;
VAL_ 438 PKC_MnvrRtnStartKey 0 "None" 1 "Not_Pressed" 2 "Pressed" 3 "Reserved" ;
VAL_ 438 PKC_AuthUsr 0 "Invalid" 1 "Authentication_Valid" 2 "Authentication_Invalid" 3 "Reserved" ;
VAL_ 438 PKC_AlcInterlockReqPromt 0 "Inactive" 1 "Permission_not_granted_to_drive,_alcohol_test_missing" 2 "Permission_not_granted_to_drive,_alcohol_test_failed_or_invalid" 3 "Invalid" ;
VAL_ 438 PKC_NFCReminderPromt 0 "Inactive" 1 "Timeout_elapsed._Put_Key_Fob/Smartphone_on_the_NFC_reader" 2 "Reserved" 3 "Invalid" ;
VAL_ 532 VCU_RdyLamp 0 "Not_ready" 1 "Ready" ;
VAL_ 532 VCU_BrkLampCtrlSts 0 "No_request" 1 "lighting_request" ;
VAL_ 532 VCU_RemWakeUpEndFlg 0 "remote_control_not_ended" 1 "remote_control_ended" ;
VAL_ 532 VCU_StgyGearSig 0 "Undefined_initial_value" 1 "gear_P" 2 "gear_N" 3 "R_gear" 4 "gear_D" 5 "Reserved" 6 "gear_E" 7 "gear_S" 8 "Reserved" 9 "Reserved" 10 "Reserved" 11 "Reserved" 12 "Reserved" 13 "Reserved" 14 "Reserved" 15 "Reserved" ;
VAL_ 532 VCU_ShiftMisoper 0 "Normal" 1 "Abnormal" ;
VAL_ 532 VCU_GearSigVld 0 "Initializing" 1 "Valid" 2 "Invalid" 3 "Reserved" ;
VAL_ 532 VCU_GearSig 0 "Undefined_initial_value" 1 "gear_P" 2 "gear_N" 3 "R_gear" 4 "D_gear" 5 "Reserved" 6 "gear_E" 7 "gear_S" 8 "Reserved" 9 "Reserved" 10 "Reserved" 11 "Reserved" 12 "Reserved" 13 "Reserved" 14 "Reserved" 15 "Reserved" ;
VAL_ 532 VCU_ACCRdy 0 "Not_ready" 1 "Ready" ;
VAL_ 532 VCU_ParkRdy 0 "Not_ready" 1 "Ready" ;
VAL_ 532 VCU_APSPercVld 0 "Initializing" 1 "Valid" 2 "Invalid" 3 "Reserved" ;
VAL_ 532 VCU_VehSt 0 "VCUSleep" 1 "WakeUp" 2 "Init/StartUp" 3 "Standby" 4 "Driving" 5 "Charging" 6 "PostConditioning" 7 "HV_Active_Discharge" 8 "Afterrun" 9 "EmgcyOff" 10 "EmgcyOff_ADisch" 11 "Safestate" 65535 "Invalid" ;
VAL_ 532 VCU_BrkSig 0 "brake_pedal_not_pressed" 1 "Brake_pedal_depressed" ;
VAL_ 532 VCU_BrkSigVld 0 "Initializing" 1 "Valid" 2 "Invalid" 3 "Reserved" ;
VAL_ 532 VCU_DrvModSigFb 0 "Eco" 1 "Normal" 2 "Sport" 3 "Custom" 4 "Snow" 5 "Offroad" 6 "Valet" 7 "Invalid" ;
VAL_ 532 VCU_DrvModShiftMisoper 0 "Normal" 1 "Abnormal" ;
VAL_ 532 VCU_SpclTerrainModEnaSig 0 "Not_enabled" 1 "Enable" ;
VAL_ 533 BMS_PwrBattOverTFlt_FS 0 "Normal" 1 "Abnormal" ;
VAL_ 533 BMS_PwrBattOverCrtFlt_FS 0 "Normal" 1 "Abnormal" ;
VAL_ 533 BMS_PwrBattNegRlyAdh_FS 0 "Normal" 1 "Abnormal" ;
VAL_ 533 BMS_PwrBattPosRlyAdh_FS 0 "Normal" 1 "Abnormal" ;
VAL_ 533 BMS_CellUnderrVoltFlt_FS 0 "Normal" 1 "Abnormal" ;
VAL_ 533 BMS_PwrBattCellOverVolt_FS 0 "Normal" 1 "Abnormal" ;
VAL_ 533 BMS_BattInlTSnsrFlt 0 "Normal" 1 "Abnormal" ;
VAL_ 533 BMS_BattOutlTSnsrFlt 0 "Normal" 1 "Abnormal" ;
VAL_ 533 BMS_PwrBattPrecRlyAdh_FS 0 "Normal" 1 "Abnormal" ;
VAL_ 533 BMS_AlrmLamp_FS 0 "Normal" 1 "Abnormal" ;
VAL_ 533 BMS_PwrBattLoadTotVoltV3_FS 65535 "Invalid" ;
VAL_ 533 BMS_FctSftyErrCod 0 "Function_safety_mechanism_startup_state_code" 1 "Function_safety_mechanism_startup_state_code" 2 "Function_safety_mechanism_startup_state_code" 3 "Function_safety_mechanism_startup_state_code" 4 "Function_safety_mechanism_startup_state_code" 5 "Function_safety_mechanism_startup_state_code" 6 "Function_safety_mechanism_startup_state_code" 7 "Function_safety_mechanism_startup_state_code" 8 "Function_safety_mechanism_startup_state_code" 9 "Function_safety_mechanism_startup_state_code" 10 "Function_safety_mechanism_startup_state_code" 11 "Function_safety_mechanism_startup_state_code" 12 "Function_safety_mechanism_startup_state_code" 13 "Function_safety_mechanism_startup_state_code" 14 "Function_safety_mechanism_startup_state_code" 15 "Function_safety_mechanism_startup_state_code" 16 "Function_safety_mechanism_startup_state_code" 17 "Function_safety_mechanism_startup_state_code" 18 "Function_safety_mechanism_startup_state_code" 19 "Function_safety_mechanism_startup_state_code" 20 "Function_safety_mechanism_startup_state_code" 21 "Function_safety_mechanism_startup_state_code" 22 "Function_safety_mechanism_startup_state_code" 23 "Function_safety_mechanism_startup_state_code" 24 "Function_safety_mechanism_startup_state_code" 25 "Function_safety_mechanism_startup_state_code" 26 "Function_safety_mechanism_startup_state_code" 27 "Function_safety_mechanism_startup_state_code" 28 "Function_safety_mechanism_startup_state_code" 29 "Function_safety_mechanism_startup_state_code" 30 "Function_safety_mechanism_startup_state_code" 31 "Function_safety_mechanism_startup_state_code" 32 "Function_safety_mechanism_startup_state_code" 33 "Function_safety_mechanism_startup_state_code" 34 "Function_safety_mechanism_startup_state_code" 35 "Function_safety_mechanism_startup_state_code" 36 "Function_safety_mechanism_startup_state_code" 37 "Function_safety_mechanism_startup_state_code" 38 "Function_safety_mechanism_startup_state_code" 39 "Function_safety_mechanism_startup_state_code" 40 "Function_safety_mechanism_startup_state_code" 41 "Function_safety_mechanism_startup_state_code" 42 "Function_safety_mechanism_startup_state_code" 43 "Function_safety_mechanism_startup_state_code" 44 "Function_safety_mechanism_startup_state_code" 45 "Function_safety_mechanism_startup_state_code" 46 "Function_safety_mechanism_startup_state_code" 47 "Function_safety_mechanism_startup_state_code" 48 "Function_safety_mechanism_startup_state_code" 49 "Function_safety_mechanism_startup_state_code" 50 "Function_safety_mechanism_startup_state_code" 51 "Function_safety_mechanism_startup_state_code" 52 "Function_safety_mechanism_startup_state_code" 53 "Function_safety_mechanism_startup_state_code" 54 "Function_safety_mechanism_startup_state_code" 55 "Function_safety_mechanism_startup_state_code" 56 "Function_safety_mechanism_startup_state_code" 57 "Function_safety_mechanism_startup_state_code" 58 "Function_safety_mechanism_startup_state_code" 59 "Function_safety_mechanism_startup_state_code" 60 "Function_safety_mechanism_startup_state_code" 61 "Function_safety_mechanism_startup_state_code" 62 "Function_safety_mechanism_startup_state_code" 63 "Function_safety_mechanism_startup_state_code" 64 "Function_safety_mechanism_startup_state_code" 65 "Function_safety_mechanism_startup_state_code" 66 "Function_safety_mechanism_startup_state_code" 67 "Function_safety_mechanism_startup_state_code" 68 "Function_safety_mechanism_startup_state_code" 69 "Function_safety_mechanism_startup_state_code" 70 "Function_safety_mechanism_startup_state_code" 71 "Function_safety_mechanism_startup_state_code" 72 "Function_safety_mechanism_startup_state_code" 73 "Function_safety_mechanism_startup_state_code" 74 "Function_safety_mechanism_startup_state_code" 75 "Function_safety_mechanism_startup_state_code" 76 "Function_safety_mechanism_startup_state_code" 77 "Function_safety_mechanism_startup_state_code" 78 "Function_safety_mechanism_startup_state_code" 79 "Function_safety_mechanism_startup_state_code" 80 "Function_safety_mechanism_startup_state_code" 81 "Function_safety_mechanism_startup_state_code" 82 "Function_safety_mechanism_startup_state_code" 83 "Function_safety_mechanism_startup_state_code" 84 "Function_safety_mechanism_startup_state_code" 85 "Function_safety_mechanism_startup_state_code" 86 "Function_safety_mechanism_startup_state_code" 87 "Function_safety_mechanism_startup_state_code" 88 "Function_safety_mechanism_startup_state_code" 89 "Function_safety_mechanism_startup_state_code" 90 "Function_safety_mechanism_startup_state_code" 91 "Function_safety_mechanism_startup_state_code" 92 "Function_safety_mechanism_startup_state_code" 93 "Function_safety_mechanism_startup_state_code" 94 "Function_safety_mechanism_startup_state_code" 95 "Function_safety_mechanism_startup_state_code" 96 "Function_safety_mechanism_startup_state_code" 97 "Function_safety_mechanism_startup_state_code" 98 "Function_safety_mechanism_startup_state_code" 99 "Function_safety_mechanism_startup_state_code" 100 "Function_safety_mechanism_startup_state_code" 101 "Function_safety_mechanism_startup_state_code" 102 "Function_safety_mechanism_startup_state_code" 103 "Function_safety_mechanism_startup_state_code" 104 "Function_safety_mechanism_startup_state_code" 105 "Function_safety_mechanism_startup_state_code" 106 "Function_safety_mechanism_startup_state_code" 107 "Function_safety_mechanism_startup_state_code" 108 "Function_safety_mechanism_startup_state_code" 109 "Function_safety_mechanism_startup_state_code" 110 "Function_safety_mechanism_startup_state_code" 111 "Function_safety_mechanism_startup_state_code" 112 "Function_safety_mechanism_startup_state_code" 113 "Function_safety_mechanism_startup_state_code" 114 "Function_safety_mechanism_startup_state_code" 115 "Function_safety_mechanism_startup_state_code" 116 "Function_safety_mechanism_startup_state_code" 117 "Function_safety_mechanism_startup_state_code" 118 "Function_safety_mechanism_startup_state_code" 119 "Function_safety_mechanism_startup_state_code" 120 "Function_safety_mechanism_startup_state_code" 121 "Function_safety_mechanism_startup_state_code" 122 "Function_safety_mechanism_startup_state_code" 123 "Function_safety_mechanism_startup_state_code" 124 "Function_safety_mechanism_startup_state_code" 125 "Function_safety_mechanism_startup_state_code" 126 "Function_safety_mechanism_startup_state_code" 127 "Function_safety_mechanism_startup_state_code" 128 "Function_safety_mechanism_startup_state_code" 129 "Function_safety_mechanism_startup_state_code" 130 "Function_safety_mechanism_startup_state_code" 131 "Function_safety_mechanism_startup_state_code" 132 "Function_safety_mechanism_startup_state_code" 133 "Function_safety_mechanism_startup_state_code" 134 "Function_safety_mechanism_startup_state_code" 135 "Function_safety_mechanism_startup_state_code" 136 "Function_safety_mechanism_startup_state_code" 137 "Function_safety_mechanism_startup_state_code" 138 "Function_safety_mechanism_startup_state_code" 139 "Function_safety_mechanism_startup_state_code" 140 "Function_safety_mechanism_startup_state_code" 141 "Function_safety_mechanism_startup_state_code" 142 "Function_safety_mechanism_startup_state_code" 143 "Function_safety_mechanism_startup_state_code" 144 "Function_safety_mechanism_startup_state_code" 145 "Function_safety_mechanism_startup_state_code" 146 "Function_safety_mechanism_startup_state_code" 147 "Function_safety_mechanism_startup_state_code" 148 "Function_safety_mechanism_startup_state_code" 149 "Function_safety_mechanism_startup_state_code" 150 "Function_safety_mechanism_startup_state_code" 151 "Function_safety_mechanism_startup_state_code" 152 "Function_safety_mechanism_startup_state_code" 153 "Function_safety_mechanism_startup_state_code" 154 "Function_safety_mechanism_startup_state_code" 155 "Function_safety_mechanism_startup_state_code" 156 "Function_safety_mechanism_startup_state_code" 157 "Function_safety_mechanism_startup_state_code" 158 "Function_safety_mechanism_startup_state_code" 159 "Function_safety_mechanism_startup_state_code" 160 "Function_safety_mechanism_startup_state_code" 161 "Function_safety_mechanism_startup_state_code" 162 "Function_safety_mechanism_startup_state_code" 163 "Function_safety_mechanism_startup_state_code" 164 "Function_safety_mechanism_startup_state_code" 165 "Function_safety_mechanism_startup_state_code" 166 "Function_safety_mechanism_startup_state_code" 167 "Function_safety_mechanism_startup_state_code" 168 "Function_safety_mechanism_startup_state_code" 169 "Function_safety_mechanism_startup_state_code" 170 "Function_safety_mechanism_startup_state_code" 171 "Function_safety_mechanism_startup_state_code" 172 "Function_safety_mechanism_startup_state_code" 173 "Function_safety_mechanism_startup_state_code" 174 "Function_safety_mechanism_startup_state_code" 175 "Function_safety_mechanism_startup_state_code" 176 "Function_safety_mechanism_startup_state_code" 177 "Function_safety_mechanism_startup_state_code" 178 "Function_safety_mechanism_startup_state_code" 179 "Function_safety_mechanism_startup_state_code" 180 "Function_safety_mechanism_startup_state_code" 181 "Function_safety_mechanism_startup_state_code" 182 "Function_safety_mechanism_startup_state_code" 183 "Function_safety_mechanism_startup_state_code" 184 "Function_safety_mechanism_startup_state_code" 185 "Function_safety_mechanism_startup_state_code" 186 "Function_safety_mechanism_startup_state_code" 187 "Function_safety_mechanism_startup_state_code" 188 "Function_safety_mechanism_startup_state_code" 189 "Function_safety_mechanism_startup_state_code" 190 "Function_safety_mechanism_startup_state_code" 191 "Function_safety_mechanism_startup_state_code" 192 "Function_safety_mechanism_startup_state_code" 193 "Function_safety_mechanism_startup_state_code" 194 "Function_safety_mechanism_startup_state_code" 195 "Function_safety_mechanism_startup_state_code" 196 "Function_safety_mechanism_startup_state_code" 197 "Function_safety_mechanism_startup_state_code" 198 "Function_safety_mechanism_startup_state_code" 199 "Function_safety_mechanism_startup_state_code" 200 "Function_safety_mechanism_startup_state_code" 201 "Function_safety_mechanism_startup_state_code" 202 "Function_safety_mechanism_startup_state_code" 203 "Function_safety_mechanism_startup_state_code" 204 "Function_safety_mechanism_startup_state_code" 205 "Function_safety_mechanism_startup_state_code" 206 "Function_safety_mechanism_startup_state_code" 207 "Function_safety_mechanism_startup_state_code" 208 "Function_safety_mechanism_startup_state_code" 209 "Function_safety_mechanism_startup_state_code" 210 "Function_safety_mechanism_startup_state_code" 211 "Function_safety_mechanism_startup_state_code" 212 "Function_safety_mechanism_startup_state_code" 213 "Function_safety_mechanism_startup_state_code" 214 "Function_safety_mechanism_startup_state_code" 215 "Function_safety_mechanism_startup_state_code" 216 "Function_safety_mechanism_startup_state_code" 217 "Function_safety_mechanism_startup_state_code" 218 "Function_safety_mechanism_startup_state_code" 219 "Function_safety_mechanism_startup_state_code" 220 "Function_safety_mechanism_startup_state_code" 221 "Function_safety_mechanism_startup_state_code" 222 "Function_safety_mechanism_startup_state_code" 223 "Function_safety_mechanism_startup_state_code" 224 "Function_safety_mechanism_startup_state_code" 225 "Function_safety_mechanism_startup_state_code" 226 "Function_safety_mechanism_startup_state_code" 227 "Function_safety_mechanism_startup_state_code" 228 "Function_safety_mechanism_startup_state_code" 229 "Function_safety_mechanism_startup_state_code" 230 "Function_safety_mechanism_startup_state_code" 231 "Function_safety_mechanism_startup_state_code" 232 "Function_safety_mechanism_startup_state_code" 233 "Function_safety_mechanism_startup_state_code" 234 "Function_safety_mechanism_startup_state_code" 235 "Function_safety_mechanism_startup_state_code" 236 "Function_safety_mechanism_startup_state_code" 237 "Function_safety_mechanism_startup_state_code" 238 "Function_safety_mechanism_startup_state_code" 239 "Function_safety_mechanism_startup_state_code" 240 "Function_safety_mechanism_startup_state_code" 241 "Function_safety_mechanism_startup_state_code" 242 "Function_safety_mechanism_startup_state_code" 243 "Function_safety_mechanism_startup_state_code" 244 "Function_safety_mechanism_startup_state_code" 245 "Function_safety_mechanism_startup_state_code" 246 "Function_safety_mechanism_startup_state_code" 247 "Function_safety_mechanism_startup_state_code" 248 "Function_safety_mechanism_startup_state_code" 249 "Function_safety_mechanism_startup_state_code" 250 "Function_safety_mechanism_startup_state_code" 251 "Function_safety_mechanism_startup_state_code" 252 "Function_safety_mechanism_startup_state_code" 253 "Function_safety_mechanism_startup_state_code" 254 "Function_safety_mechanism_startup_state_code" 255 "Invalid" ;
VAL_ 549 VCU_VehFltProcLvl 0 "Initial_value" 1 "High_voltage_immediately_(high_voltage_power_on_is_prohibited)" 2 "High_voltage_off_delay" 3 "Zero_torque" 4 "Limp" 5 "power_limit" 6 "unlimited_(no_processing)" 7 "Reserved" ;
VAL_ 549 VCU_OverMod 0 "No_Override_Not_Overcovered" 1 "Drive_ver_Override" ;
VAL_ 549 VCU_MotChkACCFltFbFlg 0 "No_Error" 1 "Reversible_error" 2 "Irreversible_Error_(Reserved)_error_irreversible" 3 "Reserved" ;
VAL_ 549 VCU_VehTqFltSts 0 "No_Failure" 1 "Failure" ;
VAL_ 549 VCU_PwrAntitheftAuthentReqFlg 0 "Power_immobilizer_authentication_request_is_not_allowed" 1 "It_is_allowed_to_send_the_power_immobilizer_authentication_request" 2 "Reserved" 3 "Reserved" ;
VAL_ 549 VCU_PwrModSwtReq 0 "No_request" 1 "With_request" ;
VAL_ 549 VCU_KL15Req 0 "Without_Request" 1 "With_Request" ;
